VERSION ""

NS_ :

BS_:

BU_: L_3HKBD L_FHPTC L_ATCU L_2HKBD L_PCM L_ATCU_vMON L_EVNT L_HKBD L_RHPTC

BO_ 36 L_ATCU_04: 8 L_ATCU
 SG_ L_ATCU_ArClnIntroEvt : 0|1@1+ (1,0) [0|0] ""  L_HKBD
 SG_ L_ATCU_ArClnSmblClr : 1|4@1+ (1,0) [0|0] ""  L_HKBD
 SG_ L_ATCU_DustLevelDis : 19|3@1+ (1,0) [0|0] ""  L_HKBD
 SG_ L_ATCU_DustBarDisOff : 22|1@1+ (1,0) [0|0] ""  L_HKBD
 SG_ L_ATCU_DustSnrStepDis : 23|6@1+ (1,0) [0|0] ""  L_HKBD
 SG_ L_ATCU_FragStrhDis : 29|2@1+ (1,0) [0|0] ""  L_HKBD,L_PCM
 SG_ L_ATCU_FragKindDis : 31|3@1+ (1,0) [0|0] ""  L_HKBD,L_PCM
 SG_ L_ATCU_Frag1Inform : 34|4@1+ (1,0) [0|0] ""  L_HKBD,L_PCM
 SG_ L_ATCU_Frag2Inform : 38|4@1+ (1,0) [0|0] ""  L_HKBD,L_PCM
 SG_ L_ATCU_Frag1RemainDisp : 42|4@1+ (1,0) [0|0] ""  L_HKBD,L_PCM
 SG_ L_ATCU_Frag2RemainDisp : 46|4@1+ (1,0) [0|0] ""  L_2HKBD,L_HKBD
 SG_ L_ATCU_ArClnSmblTyp : 5|4@1+ (1,0) [0|0] ""  L_HKBD
 SG_ L_ATCU_FrtBlwMaxLvlVaild : 50|4@1+ (1,0) [0|0] ""  L_2HKBD,L_HKBD
 SG_ L_ATCU_OpSta : 54|3@1+ (1,0) [0|0] ""  L_EVNT,L_HKBD
 SG_ L_ATCU_TempDispUnit : 57|2@1+ (1,0) [0|0] ""  L_2HKBD,L_HKBD
 SG_ L_ATCU_DrvAUTOStep : 59|4@1+ (1,0) [0|0] ""  L_HKBD
 SG_ L_ATCU_DiagCodeDis : 9|10@1+ (1,-1) [0|0] ""  L_HKBD

BO_ 784 L_ATCU_MON_35: 8 L_ATCU_vMON
 SG_ MON_StatMngr_AirQuality : 0|64@1+ (1,0) [0|0] ""  L_ATCU

BO_ 37 L_ATCU_05: 8 L_ATCU
 SG_ L_ATCU_RrOpSta : 0|3@1+ (1,0) [0|0] ""  L_2HKBD,L_HKBD
 SG_ L_ATCU_RrDrvTempFDis : 11|8@1+ (1,56) [0|0] "¢µ"  L_2HKBD,L_HKBD
 SG_ L_ATCU_RrDrvModDis : 19|4@1+ (1,0) [0|0] ""  L_2HKBD,L_EVNT,L_HKBD
 SG_ L_ATCU_RrDrvBlwDis : 23|4@1+ (1,0) [0|0] ""  L_2HKBD,L_HKBD
 SG_ L_ATCU_RrDrvAutoDis : 27|2@1+ (1,0) [0|0] ""  L_2HKBD,L_HKBD
 SG_ L_ATCU_RrDrvMultiAutoBlwDis : 29|2@1+ (1,0) [0|0] ""  L_2HKBD,L_HKBD
 SG_ L_ATCU_RrDrvTempCDis : 3|8@1+ (0.5,14) [0|0] "¡É"  L_2HKBD,L_HKBD
 SG_ L_ATCU_RrSyncDis : 31|2@1+ (1,0) [0|0] ""  L_2HKBD,L_HKBD
 SG_ L_ATCU_RrLcdBckLightSta : 33|1@1+ (1,0) [0|0] ""  L_2HKBD,L_HKBD
 SG_ L_ATCU_RrGUIBlankDis : 34|1@1+ (1,0) [0|0] ""  L_2HKBD,L_HKBD
 SG_ L_ATCU_RLStHeatSwHInd : 35|1@1+ (1,0) [0|0] ""  L_2HKBD,L_HKBD
 SG_ L_ATCU_RLStHeatSwMInd : 36|1@1+ (1,0) [0|0] ""  L_2HKBD,L_HKBD
 SG_ L_ATCU_RLStHeatSwLInd : 37|1@1+ (1,0) [0|0] ""  L_2HKBD,L_HKBD
 SG_ L_ATCU_RLStVntSwHInd : 38|1@1+ (1,0) [0|0] ""  L_2HKBD,L_HKBD
 SG_ L_ATCU_RLStVntSwMInd : 39|1@1+ (1,0) [0|0] ""  L_2HKBD,L_HKBD
 SG_ L_ATCU_RLStVntSwLInd : 40|1@1+ (1,0) [0|0] ""  L_2HKBD,L_HKBD
 SG_ L_ATCU_RRStHeatSwHInd : 41|1@1+ (1,0) [0|0] ""  L_2HKBD,L_HKBD
 SG_ L_ATCU_RRStHeatSwMInd : 42|1@1+ (1,0) [0|0] ""  L_2HKBD,L_HKBD
 SG_ L_ATCU_RRStHeatSwLInd : 43|1@1+ (1,0) [0|0] ""  L_2HKBD,L_HKBD
 SG_ L_ATCU_RRStVntSwHInd : 44|1@1+ (1,0) [0|0] ""  L_2HKBD,L_HKBD
 SG_ L_ATCU_RRStVntSwMInd : 45|1@1+ (1,0) [0|0] ""  L_2HKBD,L_HKBD
 SG_ L_ATCU_RRStVntSwLInd : 46|1@1+ (1,0) [0|0] ""  L_2HKBD,L_HKBD
 SG_ L_ATCU_RrMTCOpSta : 47|2@1+ (1,0) [0|0] ""  L_2HKBD,L_HKBD
 SG_ L_ATCU_RrMTCTempLvl : 49|4@1+ (1,0) [0|0] ""  L_2HKBD,L_HKBD
 SG_ L_ATCU_RrPsModDis : 53|4@1+ (1,0) [0|0] ""  L_2HKBD,L_EVNT,L_HKBD
 SG_ L_ATCU_RrLockDis : 57|2@1+ (1,0) [0|0] ""  L_2HKBD,L_HKBD
 SG_ L_ATCU_RrDrvAutoStep : 59|4@1+ (1,0) [0|0] ""  L_2HKBD,L_HKBD

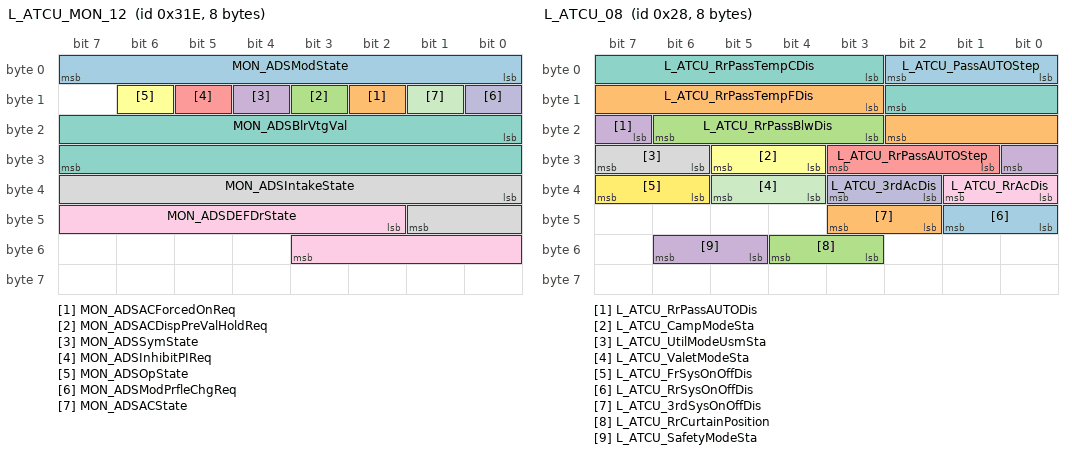
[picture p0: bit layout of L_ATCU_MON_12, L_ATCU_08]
BO_ 798 L_ATCU_MON_12: 8 L_ATCU_vMON
 SG_ MON_ADSModState : 0|8@1+ (1,0) [0|0] ""  L_ATCU
 SG_ MON_ADSACForcedOnReq : 10|1@1+ (1,0) [0|0] ""  L_ATCU
 SG_ MON_ADSACDispPreValHoldReq : 11|1@1+ (1,0) [0|0] ""  L_ATCU
 SG_ MON_ADSSymState : 12|1@1+ (1,0) [0|0] ""  L_ATCU
 SG_ MON_ADSInhibitPIReq : 13|1@1+ (1,0) [0|0] ""  L_ATCU
 SG_ MON_ADSOpState : 14|1@1+ (1,0) [0|0] ""  L_ATCU
 SG_ MON_ADSBlrVtgVal : 16|16@1+ (0.001,0) [0|0] ""  L_ATCU
 SG_ MON_ADSIntakeState : 32|10@1+ (1,0) [0|0] ""  L_ATCU
 SG_ MON_ADSDEFDrState : 42|10@1+ (0.1,0) [0|0] ""  L_ATCU
 SG_ MON_ADSModPrfleChgReq : 8|1@1+ (1,0) [0|0] ""  L_ATCU
 SG_ MON_ADSACState : 9|1@1+ (1,0) [0|0] ""  L_ATCU

BO_ 40 L_ATCU_08: 8 L_ATCU
 SG_ L_ATCU_PassAUTOStep : 0|3@1+ (1,0) [0|0] ""  L_2HKBD,L_HKBD
 SG_ L_ATCU_RrPassTempFDis : 11|8@1+ (1,56) [0|0] "¢µ"  L_2HKBD,L_HKBD
 SG_ L_ATCU_RrPassBlwDis : 19|4@1+ (1,0) [0|0] ""  L_2HKBD,L_HKBD
 SG_ L_ATCU_RrPassAUTODis : 23|2@1+ (1,0) [0|0] ""  L_2HKBD,L_HKBD
 SG_ L_ATCU_RrPassAUTOStep : 25|3@1+ (1,0) [0|0] ""  L_2HKBD,L_HKBD
 SG_ L_ATCU_CampModeSta : 28|2@1+ (1,0) [0|0] ""  L_2HKBD,L_3HKBD,L_EVNT,L_HKBD
 SG_ L_ATCU_RrPassTempCDis : 3|8@1+ (0.5,14) [0|0] "¡É"  L_2HKBD,L_HKBD
 SG_ L_ATCU_UtilModeUsmSta : 30|2@1+ (1,0) [0|0] ""  L_2HKBD,L_3HKBD,L_EVNT,L_HKBD
 SG_ L_ATCU_RrAcDis : 32|2@1+ (1,0) [0|0] ""  L_2HKBD,L_3HKBD,L_HKBD
 SG_ L_ATCU_3rdAcDis : 34|2@1+ (1,0) [0|0] ""  L_2HKBD,L_3HKBD,L_HKBD
 SG_ L_ATCU_ValetModeSta : 36|2@1+ (1,0) [0|0] ""  L_EVNT
 SG_ L_ATCU_FrSysOnOffDis : 38|2@1+ (1,0) [0|0] ""  L_2HKBD,L_3HKBD,L_HKBD
 SG_ L_ATCU_RrSysOnOffDis : 40|2@1+ (1,0) [0|0] ""  L_2HKBD,L_3HKBD,L_HKBD
 SG_ L_ATCU_3rdSysOnOffDis : 42|2@1+ (1,0) [0|0] ""  L_2HKBD,L_3HKBD,L_HKBD
 SG_ L_ATCU_RrCurtainPosition : 51|2@1+ (1,0) [0|0] ""  L_2HKBD,L_3HKBD
 SG_ L_ATCU_SafetyModeSta : 53|2@1+ (1,0) [0|0] ""  L_2HKBD,L_3HKBD,L_EVNT,L_HKBD

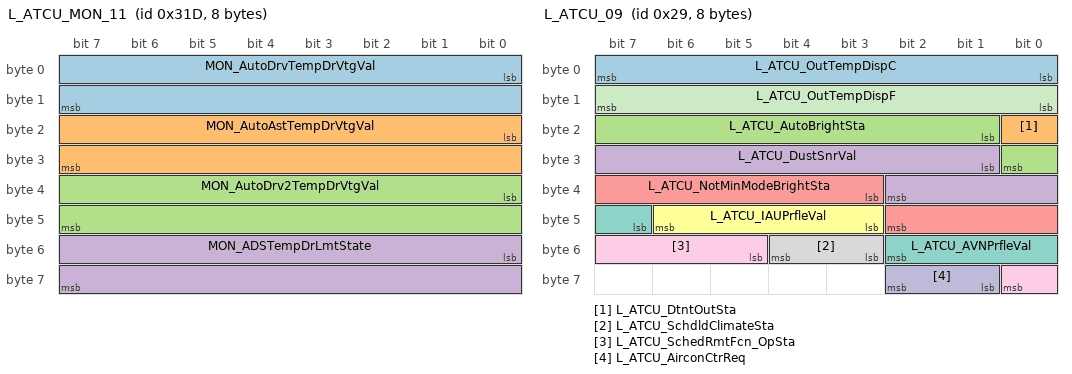
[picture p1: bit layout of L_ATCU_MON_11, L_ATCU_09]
BO_ 797 L_ATCU_MON_11: 8 L_ATCU_vMON
 SG_ MON_AutoDrvTempDrVtgVal : 0|16@1+ (0.001,0) [0|0] ""  L_ATCU
 SG_ MON_AutoAstTempDrVtgVal : 16|16@1+ (0.001,0) [0|0] ""  L_ATCU
 SG_ MON_AutoDrv2TempDrVtgVal : 32|16@1+ (0.001,0) [0|0] ""  L_ATCU
 SG_ MON_ADSTempDrLmtState : 48|16@1+ (0.001,0) [0|0] ""  L_ATCU

BO_ 41 L_ATCU_09: 8 L_ATCU
 SG_ L_ATCU_OutTempDispC : 0|8@1+ (0.5,-41) [0|0] "¡É"  L_FHPTC,L_HKBD,L_RHPTC
 SG_ L_ATCU_DtntOutSta : 16|1@1+ (1,0) [0|0] ""  L_2HKBD,L_EVNT,L_HKBD
 SG_ L_ATCU_AutoBrightSta : 17|8@1+ (1,0) [0|0] ""  L_2HKBD,L_EVNT,L_HKBD
 SG_ L_ATCU_DustSnrVal : 25|10@1+ (1,0) [0|0] "um/m3"  L_HKBD
 SG_ L_ATCU_NotMinModeBrightSta : 35|8@1+ (1,0) [0|0] ""  L_2HKBD,L_3HKBD,L_EVNT,L_HKBD
 SG_ L_ATCU_IAUPrfleVal : 43|4@1+ (1,0) [0|0] ""  L_EVNT
 SG_ L_ATCU_AVNPrfleVal : 47|4@1+ (1,0) [0|0] ""  L_EVNT
 SG_ L_ATCU_SchdldClimateSta : 51|2@1+ (1,0) [0|0] ""  L_EVNT
 SG_ L_ATCU_SchedRmtFcn_OpSta : 53|4@1+ (1,0) [0|15] ""  L_2HKBD,L_3HKBD,L_EVNT,L_HKBD
 SG_ L_ATCU_AirconCtrReq : 57|2@1+ (1,0) [0|0] ""  L_2HKBD,L_3HKBD,L_EVNT,L_HKBD
 SG_ L_ATCU_OutTempDispF : 8|8@1+ (1,-42) [0|0] "¢µ"  L_FHPTC,L_HKBD,L_RHPTC

BO_ 795 L_ATCU_MON_46: 8 L_ATCU_vMON
 SG_ MON_StatMngr_2ndFuelEfficiency : 0|64@1+ (1,0) [0|0] ""  L_ATCU

BO_ 794 L_ATCU_MON_45: 8 L_ATCU_vMON
 SG_ MON_StatMngr_2ndETC : 0|64@1+ (1,0) [0|0] ""  L_ATCU

BO_ 793 L_ATCU_MON_44: 8 L_ATCU_vMON
 SG_ MON_StatMngr_2ndAirQuality : 0|64@1+ (1,0) [0|0] ""  L_ATCU

BO_ 792 L_ATCU_MON_43: 8 L_ATCU_vMON
 SG_ MON_StatMngr_2ndConvenience : 0|64@1+ (1,0) [0|0] ""  L_ATCU

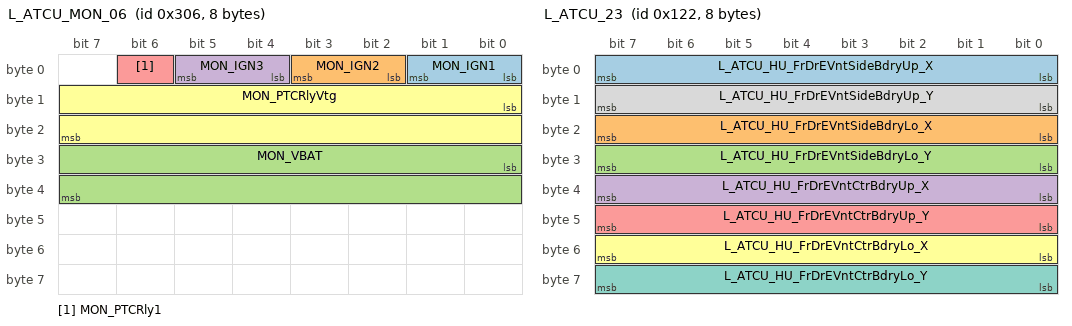
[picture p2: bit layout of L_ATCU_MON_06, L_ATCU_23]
BO_ 774 L_ATCU_MON_06: 8 L_ATCU_vMON
 SG_ MON_IGN1 : 0|2@1+ (1,0) [0|3] ""  L_ATCU
 SG_ MON_IGN2 : 2|2@1+ (1,0) [0|3] ""  L_ATCU
 SG_ MON_VBAT : 24|16@1+ (0.001,0) [0|0] ""  L_ATCU
 SG_ MON_IGN3 : 4|2@1+ (1,0) [0|3] ""  L_ATCU
 SG_ MON_PTCRly1 : 6|1@1+ (1,0) [0|1] ""  L_ATCU
 SG_ MON_PTCRlyVtg : 8|16@1+ (0.001,0) [0|5] "V"  L_ATCU

BO_ 775 L_ATCU_MON_07: 8 L_ATCU_vMON
 SG_ MON_RgnOpt : 0|4@1+ (1,0) [0|15] ""  L_ATCU
 SG_ MON_DrvOnlyOpt : 10|1@1+ (1,0) [0|1] ""  L_ATCU
 SG_ MON_ADSOpt : 11|1@1+ (1,0) [0|1] ""  L_ATCU
 SG_ MON_AfterBlowOpt : 12|1@1+ (1,0) [0|1] ""  L_ATCU
 SG_ MON_SchdldVentOpt : 13|1@1+ (1,0) [0|1] ""  L_ATCU
 SG_ MON_FineDustOpt : 14|1@1+ (1,0) [0|1] ""  L_ATCU
 SG_ MON_FrontSyncCtrlTypOpt : 15|1@1+ (1,0) [0|1] ""  L_ATCU
 SG_ MON_CompOpt : 16|3@1+ (1,0) [0|7] ""  L_ATCU
 SG_ MON_WheelDrivePosOpt : 19|2@1+ (1,0) [0|3] ""  L_ATCU
 SG_ MON_NetworkTypOpt : 21|3@1+ (1,0) [0|7] ""  L_ATCU
 SG_ MON_AutoSwTyp : 24|1@1+ (1,0) [0|1] ""  L_ATCU
 SG_ MON_ModSwTypOpt : 25|2@1+ (1,0) [0|3] ""  L_ATCU
 SG_ MON_IntakeSwTypOpt : 27|1@1+ (1,0) [0|1] ""  L_ATCU
 SG_ MON_OffSwTypOpt : 28|2@1+ (1,0) [0|3] ""  L_ATCU
 SG_ MON_TempSwKnobOpt : 30|1@1+ (1,0) [0|1] ""  L_ATCU
 SG_ MON_BlrSwKnobOpt : 31|1@1+ (1,0) [0|1] ""  L_ATCU
 SG_ MON_BATCoolingTypOpt : 32|2@1+ (1,0) [0|3] ""  L_ATCU
 SG_ MON_PTCStepOpt : 34|1@1+ (1,0) [0|1] ""  L_ATCU
 SG_ MON_PTCTypOpt : 35|2@1+ (1,0) [0|3] ""  L_ATCU
 SG_ MON_ThermostatOpt : 37|1@1+ (1,0) [0|1] ""  L_ATCU
 SG_ MON_SmartVentOpt : 38|1@1+ (1,0) [0|1] ""  L_ATCU
 SG_ MON_ROATypOpt : 39|1@1+ (1,0) [0|1] ""  L_ATCU
 SG_ MON_VehTypOpt : 4|3@1+ (1,0) [0|7] ""  L_ATCU
 SG_ MON_VRLedOpt : 40|1@1+ (1,0) [0|1] ""  L_ATCU
 SG_ MON_FrontAutoStepOpt : 41|2@1+ (1,0) [0|3] ""  L_ATCU
 SG_ MON_2ndAutoStepOpt : 43|2@1+ (1,0) [0|3] ""  L_ATCU
 SG_ MON_2ndAutoSwTyp : 45|1@1+ (1,0) [0|1] ""  L_ATCU
 SG_ MON_2ndOffSwTypOpt : 46|2@1+ (1,0) [0|3] ""  L_ATCU
 SG_ MON_2ndModSwTypOpt : 48|2@1+ (1,0) [0|3] ""  L_ATCU
 SG_ MON_2ndAutoBtnOpt : 50|2@1+ (1,0) [0|3] ""  L_ATCU
 SG_ MON_2ndBlrBtnOpt : 52|2@1+ (1,0) [0|3] ""  L_ATCU
 SG_ MON_2ndModBtnOpt : 54|2@1+ (1,0) [0|3] ""  L_ATCU
 SG_ MON_2ndTmpBtnOpt : 56|2@1+ (1,0) [0|3] ""  L_ATCU
 SG_ MON_2ndTempSwKnobOpt : 58|1@1+ (1,0) [0|1] ""  L_ATCU
 SG_ MON_DrvHndSideOpt : 7|1@1+ (1,0) [0|1] ""  L_ATCU
 SG_ MON_DisplayOpt : 8|2@1+ (1,0) [0|3] ""  L_ATCU

BO_ 290 L_ATCU_23: 8 L_ATCU
 SG_ L_ATCU_HU_FrDrEVntSideBdryUp_X : 0|8@1+ (10,0) [0|0] ""  L_EVNT
 SG_ L_ATCU_HU_FrDrEVntSideBdryLo_X : 16|8@1+ (10,0) [0|0] ""  L_EVNT
 SG_ L_ATCU_HU_FrDrEVntSideBdryLo_Y : 24|8@1+ (10,0) [0|0] ""  L_EVNT
 SG_ L_ATCU_HU_FrDrEVntCtrBdryUp_X : 32|8@1+ (10,0) [0|0] ""  L_EVNT
 SG_ L_ATCU_HU_FrDrEVntCtrBdryUp_Y : 40|8@1+ (10,0) [0|0] ""  L_EVNT
 SG_ L_ATCU_HU_FrDrEVntCtrBdryLo_X : 48|8@1+ (10,0) [0|0] ""  L_EVNT
 SG_ L_ATCU_HU_FrDrEVntCtrBdryLo_Y : 56|8@1+ (10,0) [0|0] ""  L_EVNT
 SG_ L_ATCU_HU_FrDrEVntSideBdryUp_Y : 8|8@1+ (10,0) [0|0] ""  L_EVNT

BO_ 49 L_ATCU_11: 8 L_ATCU
 SG_ L_ATCU_ResetPreWrngForOthers : 0|2@1+ (1,0) [0|0] ""  L_2HKBD,L_3HKBD,L_EVNT,L_HKBD,L_PCM
 SG_ L_ATCU_ResetReqForOthers : 2|2@1+ (1,0) [0|0] ""  L_2HKBD,L_3HKBD,L_EVNT,L_HKBD,L_PCM

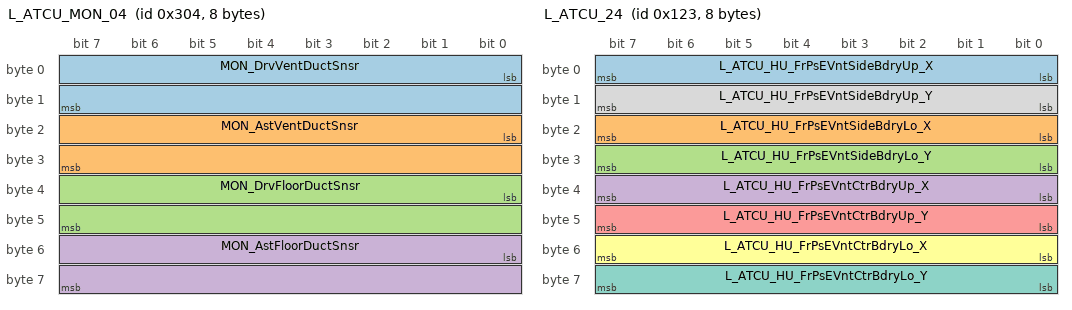
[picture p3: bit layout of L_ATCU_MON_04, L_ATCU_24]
BO_ 772 L_ATCU_MON_04: 8 L_ATCU_vMON
 SG_ MON_DrvVentDuctSnsr : 0|16@1+ (0.1,-40) [-40|120] "¡É"  L_ATCU
 SG_ MON_AstVentDuctSnsr : 16|16@1+ (0.1,-40) [-40|120] "¡É"  L_ATCU
 SG_ MON_DrvFloorDuctSnsr : 32|16@1+ (0.1,-40) [-40|120] "¡É"  L_ATCU
 SG_ MON_AstFloorDuctSnsr : 48|16@1+ (0.1,-40) [-40|120] "¡É"  L_ATCU

BO_ 291 L_ATCU_24: 8 L_ATCU
 SG_ L_ATCU_HU_FrPsEVntSideBdryUp_X : 0|8@1+ (10,0) [0|0] ""  L_EVNT
 SG_ L_ATCU_HU_FrPsEVntSideBdryLo_X : 16|8@1+ (10,0) [0|0] ""  L_EVNT
 SG_ L_ATCU_HU_FrPsEVntSideBdryLo_Y : 24|8@1+ (10,0) [0|0] ""  L_EVNT
 SG_ L_ATCU_HU_FrPsEVntCtrBdryUp_X : 32|8@1+ (10,0) [0|0] ""  L_EVNT
 SG_ L_ATCU_HU_FrPsEVntCtrBdryUp_Y : 40|8@1+ (10,0) [0|0] ""  L_EVNT
 SG_ L_ATCU_HU_FrPsEVntCtrBdryLo_X : 48|8@1+ (10,0) [0|0] ""  L_EVNT
 SG_ L_ATCU_HU_FrPsEVntCtrBdryLo_Y : 56|8@1+ (10,0) [0|0] ""  L_EVNT
 SG_ L_ATCU_HU_FrPsEVntSideBdryUp_Y : 8|8@1+ (10,0) [0|0] ""  L_EVNT

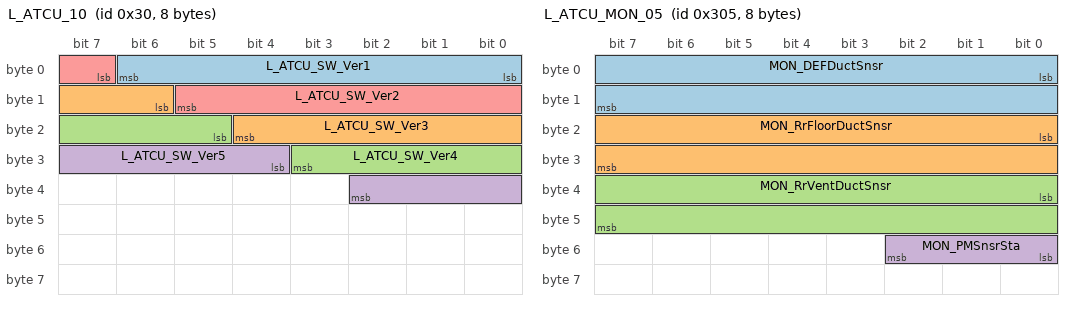
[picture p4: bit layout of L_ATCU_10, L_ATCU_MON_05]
BO_ 48 L_ATCU_10: 8 L_ATCU
 SG_ L_ATCU_SW_Ver1 : 0|7@1+ (1,0) [0|0] ""  L_HKBD
 SG_ L_ATCU_SW_Ver3 : 14|7@1+ (1,0) [0|0] ""  L_HKBD
 SG_ L_ATCU_SW_Ver4 : 21|7@1+ (1,0) [0|0] ""  L_HKBD
 SG_ L_ATCU_SW_Ver5 : 28|7@1+ (1,0) [0|0] ""  L_HKBD
 SG_ L_ATCU_SW_Ver2 : 7|7@1+ (1,0) [0|0] ""  L_HKBD

BO_ 773 L_ATCU_MON_05: 8 L_ATCU_vMON
 SG_ MON_DEFDuctSnsr : 0|16@1+ (0.1,-40) [-40|120] "¡É"  L_ATCU
 SG_ MON_RrFloorDuctSnsr : 16|16@1+ (0.1,-40) [-40|120] "¡É"  L_ATCU
 SG_ MON_RrVentDuctSnsr : 32|16@1+ (0.1,-40) [-40|120] "¡É"  L_ATCU
 SG_ MON_PMSnsrSta : 48|3@1+ (1,0) [0|0] ""  L_ATCU

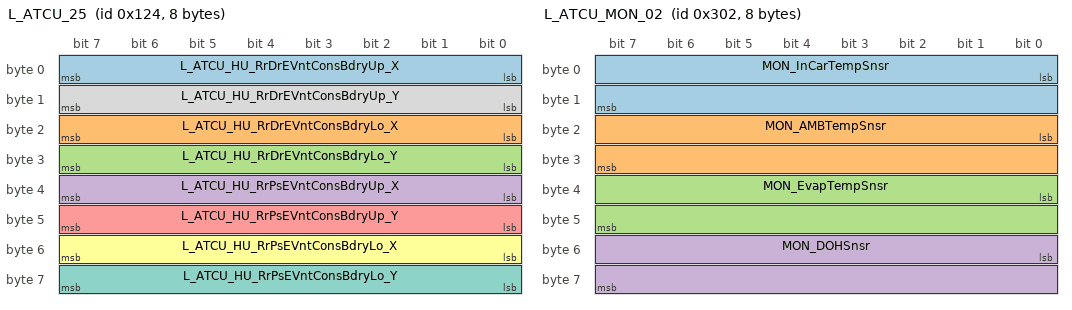
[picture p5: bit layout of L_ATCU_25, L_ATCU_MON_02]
BO_ 292 L_ATCU_25: 8 L_ATCU
 SG_ L_ATCU_HU_RrDrEVntConsBdryUp_X : 0|8@1+ (10,0) [0|0] ""  L_EVNT
 SG_ L_ATCU_HU_RrDrEVntConsBdryLo_X : 16|8@1+ (10,0) [0|0] ""  L_EVNT
 SG_ L_ATCU_HU_RrDrEVntConsBdryLo_Y : 24|8@1+ (10,0) [0|0] ""  L_EVNT
 SG_ L_ATCU_HU_RrPsEVntConsBdryUp_X : 32|8@1+ (10,0) [0|0] ""  L_EVNT
 SG_ L_ATCU_HU_RrPsEVntConsBdryUp_Y : 40|8@1+ (10,0) [0|0] ""  L_EVNT
 SG_ L_ATCU_HU_RrPsEVntConsBdryLo_X : 48|8@1+ (10,0) [0|0] ""  L_EVNT
 SG_ L_ATCU_HU_RrPsEVntConsBdryLo_Y : 56|8@1+ (10,0) [0|0] ""  L_EVNT
 SG_ L_ATCU_HU_RrDrEVntConsBdryUp_Y : 8|8@1+ (10,0) [0|0] ""  L_EVNT

BO_ 770 L_ATCU_MON_02: 8 L_ATCU_vMON
 SG_ MON_InCarTempSnsr : 0|16@1+ (0.1,-40) [-40|60] "¡É"  L_ATCU
 SG_ MON_AMBTempSnsr : 16|16@1+ (0.1,-40) [-40|60] "¡É"  L_ATCU
 SG_ MON_EvapTempSnsr : 32|16@1+ (0.1,-20) [-20|40] "¡É"  L_ATCU
 SG_ MON_DOHSnsr : 48|16@1+ (1,0) [0|100] "%"  L_ATCU

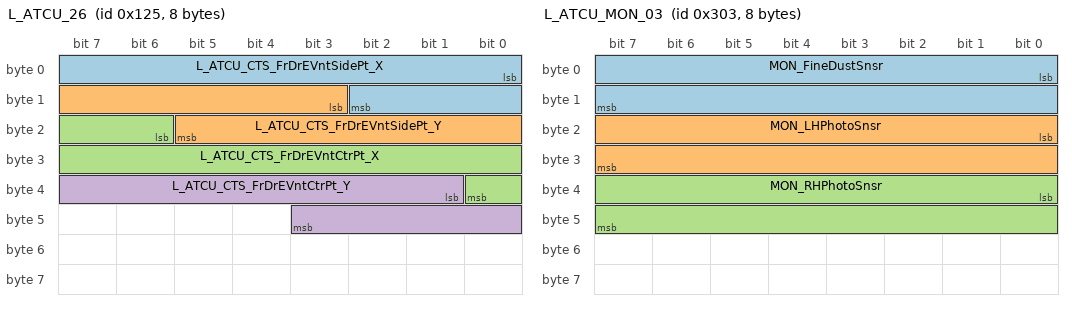
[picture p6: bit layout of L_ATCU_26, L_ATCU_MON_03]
BO_ 293 L_ATCU_26: 8 L_ATCU
 SG_ L_ATCU_CTS_FrDrEVntSidePt_X : 0|11@1+ (1,0) [0|0] ""  L_EVNT
 SG_ L_ATCU_CTS_FrDrEVntSidePt_Y : 11|11@1+ (1,0) [0|0] ""  L_EVNT
 SG_ L_ATCU_CTS_FrDrEVntCtrPt_X : 22|11@1+ (1,0) [0|0] ""  L_EVNT
 SG_ L_ATCU_CTS_FrDrEVntCtrPt_Y : 33|11@1+ (1,0) [0|0] ""  L_EVNT

BO_ 771 L_ATCU_MON_03: 8 L_ATCU_vMON
 SG_ MON_FineDustSnsr : 0|16@1+ (1,0) [0|255] ""  L_ATCU
 SG_ MON_LHPhotoSnsr : 16|16@1+ (0.001,0) [0|5] "V"  L_ATCU
 SG_ MON_RHPhotoSnsr : 32|16@1+ (0.001,0) [0|5] "V"  L_ATCU

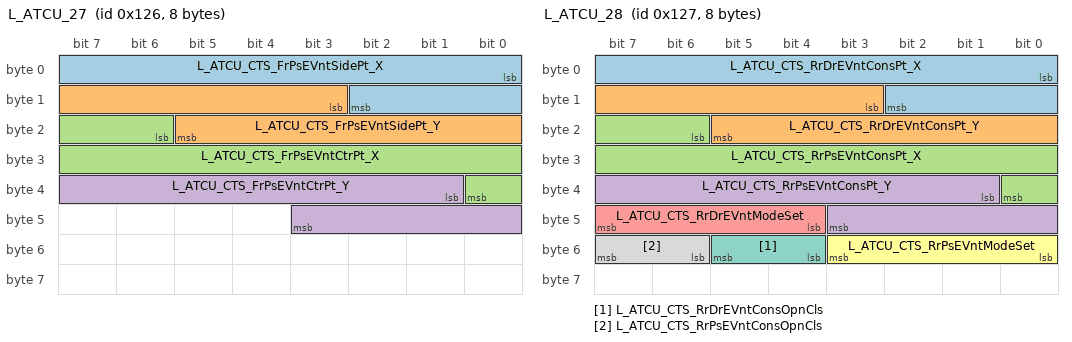
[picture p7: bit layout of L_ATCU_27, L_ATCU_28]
BO_ 294 L_ATCU_27: 8 L_ATCU
 SG_ L_ATCU_CTS_FrPsEVntSidePt_X : 0|11@1+ (1,0) [0|0] ""  L_EVNT
 SG_ L_ATCU_CTS_FrPsEVntSidePt_Y : 11|11@1+ (1,0) [0|0] ""  L_EVNT
 SG_ L_ATCU_CTS_FrPsEVntCtrPt_X : 22|11@1+ (1,0) [0|0] ""  L_EVNT
 SG_ L_ATCU_CTS_FrPsEVntCtrPt_Y : 33|11@1+ (1,0) [0|0] ""  L_EVNT

BO_ 295 L_ATCU_28: 8 L_ATCU
 SG_ L_ATCU_CTS_RrDrEVntConsPt_X : 0|11@1+ (1,0) [0|0] ""  L_EVNT
 SG_ L_ATCU_CTS_RrDrEVntConsPt_Y : 11|11@1+ (1,0) [0|0] ""  L_EVNT
 SG_ L_ATCU_CTS_RrPsEVntConsPt_X : 22|11@1+ (1,0) [0|0] ""  L_EVNT
 SG_ L_ATCU_CTS_RrPsEVntConsPt_Y : 33|11@1+ (1,0) [0|0] ""  L_EVNT
 SG_ L_ATCU_CTS_RrDrEVntModeSet : 44|4@1+ (1,0) [0|0] ""  L_EVNT
 SG_ L_ATCU_CTS_RrPsEVntModeSet : 48|4@1+ (1,0) [0|0] ""  L_EVNT
 SG_ L_ATCU_CTS_RrDrEVntConsOpnCls : 52|2@1+ (1,0) [0|0] ""  L_EVNT
 SG_ L_ATCU_CTS_RrPsEVntConsOpnCls : 54|2@1+ (1,0) [0|0] ""  L_EVNT

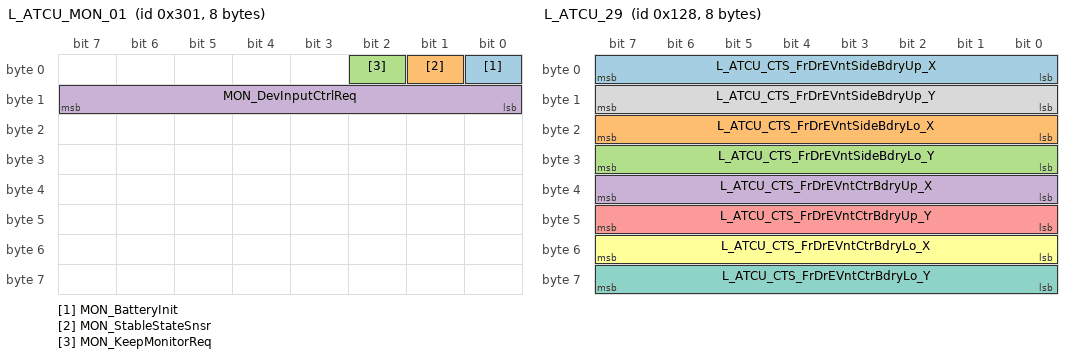
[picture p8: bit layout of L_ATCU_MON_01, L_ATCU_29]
BO_ 769 L_ATCU_MON_01: 8 L_ATCU_vMON
 SG_ MON_BatteryInit : 0|1@1+ (1,0) [0|1] ""  L_ATCU
 SG_ MON_StableStateSnsr : 1|1@1+ (1,0) [0|1] ""  L_ATCU
 SG_ MON_KeepMonitorReq : 2|1@1+ (1,0) [0|1] ""  L_ATCU
 SG_ MON_DevInputCtrlReq : 8|8@1+ (1,0) [0|0] ""  L_ATCU

BO_ 782 L_ATCU_MON_33: 8 L_ATCU_vMON
 SG_ MON_StatMngr_Mngr : 0|64@1+ (1,0) [0|0] ""  L_ATCU

BO_ 296 L_ATCU_29: 8 L_ATCU
 SG_ L_ATCU_CTS_FrDrEVntSideBdryUp_X : 0|8@1+ (10,0) [0|0] ""  L_EVNT
 SG_ L_ATCU_CTS_FrDrEVntSideBdryLo_X : 16|8@1+ (10,0) [0|0] ""  L_EVNT
 SG_ L_ATCU_CTS_FrDrEVntSideBdryLo_Y : 24|8@1+ (10,0) [0|0] ""  L_EVNT
 SG_ L_ATCU_CTS_FrDrEVntCtrBdryUp_X : 32|8@1+ (10,0) [0|0] ""  L_EVNT
 SG_ L_ATCU_CTS_FrDrEVntCtrBdryUp_Y : 40|8@1+ (10,0) [0|0] ""  L_EVNT
 SG_ L_ATCU_CTS_FrDrEVntCtrBdryLo_X : 48|8@1+ (10,0) [0|0] ""  L_EVNT
 SG_ L_ATCU_CTS_FrDrEVntCtrBdryLo_Y : 56|8@1+ (10,0) [0|0] ""  L_EVNT
 SG_ L_ATCU_CTS_FrDrEVntSideBdryUp_Y : 8|8@1+ (10,0) [0|0] ""  L_EVNT

BO_ 783 L_ATCU_MON_34: 8 L_ATCU_vMON
 SG_ MON_StatMngr_Convenience : 0|64@1+ (1,0) [0|0] ""  L_ATCU

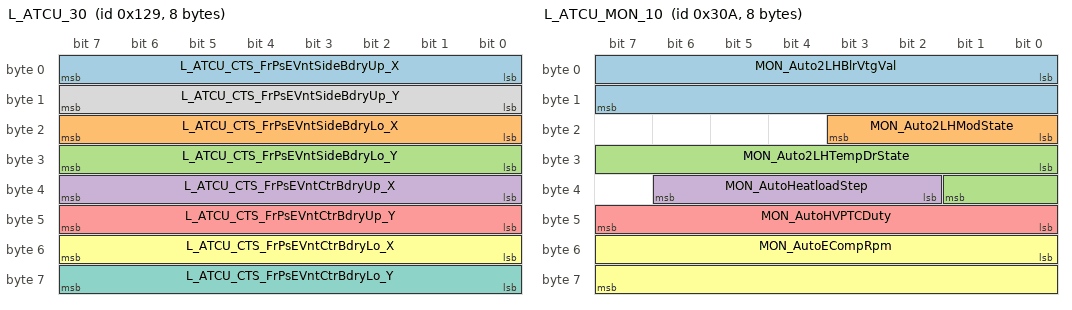
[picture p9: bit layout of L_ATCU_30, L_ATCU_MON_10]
BO_ 297 L_ATCU_30: 8 L_ATCU
 SG_ L_ATCU_CTS_FrPsEVntSideBdryUp_X : 0|8@1+ (10,0) [0|0] ""  L_EVNT
 SG_ L_ATCU_CTS_FrPsEVntSideBdryLo_X : 16|8@1+ (10,0) [0|0] ""  L_EVNT
 SG_ L_ATCU_CTS_FrPsEVntSideBdryLo_Y : 24|8@1+ (10,0) [0|0] ""  L_EVNT
 SG_ L_ATCU_CTS_FrPsEVntCtrBdryUp_X : 32|8@1+ (10,0) [0|0] ""  L_EVNT
 SG_ L_ATCU_CTS_FrPsEVntCtrBdryUp_Y : 40|8@1+ (10,0) [0|0] ""  L_EVNT
 SG_ L_ATCU_CTS_FrPsEVntCtrBdryLo_X : 48|8@1+ (10,0) [0|0] ""  L_EVNT
 SG_ L_ATCU_CTS_FrPsEVntCtrBdryLo_Y : 56|8@1+ (10,0) [0|0] ""  L_EVNT
 SG_ L_ATCU_CTS_FrPsEVntSideBdryUp_Y : 8|8@1+ (10,0) [0|0] ""  L_EVNT

BO_ 780 L_ATCU_MON_31: 8 L_ATCU_vMON
 SG_ MON_StatMngr_Temp : 0|64@1+ (1,0) [0|0] ""  L_ATCU

BO_ 781 L_ATCU_MON_32: 8 L_ATCU_vMON
 SG_ MON_StatMngr_SafetynCool : 0|64@1+ (1,0) [0|0] ""  L_ATCU

BO_ 778 L_ATCU_MON_10: 8 L_ATCU_vMON
 SG_ MON_Auto2LHBlrVtgVal : 0|16@1+ (1,0) [0|65535] ""  L_ATCU
 SG_ MON_Auto2LHModState : 16|4@1+ (1,0) [0|15] ""  L_ATCU
 SG_ MON_Auto2LHTempDrState : 24|10@1+ (1,0) [0|1023] ""  L_ATCU
 SG_ MON_AutoHeatloadStep : 34|5@1+ (1,0) [0|31] ""  L_ATCU
 SG_ MON_AutoHVPTCDuty : 40|8@1+ (1,0) [0|255] "%"  L_ATCU
 SG_ MON_AutoECompRpm : 48|16@1+ (1,0) [0|65535] ""  L_ATCU

BO_ 779 L_ATCU_MON_30: 8 L_ATCU_vMON
 SG_ MON_StatMngr_Humid : 0|64@1+ (1,0) [0|0] ""  L_ATCU

CM_ BO_ 36 "[PE] Periodic and On Event";
CM_ SG_ 36 L_ATCU_ArClnIntroEvt "ATCU_AirCleaningIntroEvent";
CM_ SG_ 36 L_ATCU_ArClnSmblClr "ATCU_AirCleaningSymbolColor";
CM_ SG_ 36 L_ATCU_DustLevelDis "ATCU_DustLevelDisplay";
CM_ SG_ 36 L_ATCU_DustBarDisOff "ATCU_DustBarDisplayOff";
CM_ SG_ 36 L_ATCU_DustSnrStepDis "ATCU_DustSensorStepDisplay";
CM_ SG_ 36 L_ATCU_FragStrhDis "ATCU_FragStrengthDisplay";
CM_ SG_ 36 L_ATCU_FragKindDis "ATCU_FragKindDisplay";
CM_ SG_ 36 L_ATCU_Frag1Inform "ATCU_Frag1Information";
CM_ SG_ 36 L_ATCU_Frag2Inform "ATCU_Frag2Information";
CM_ SG_ 36 L_ATCU_Frag1RemainDisp "ATCU_Frag1RemainDisplay";
CM_ SG_ 36 L_ATCU_Frag2RemainDisp "ATCU_Frag2RemainDisplay";
CM_ SG_ 36 L_ATCU_ArClnSmblTyp "ATCU_AircCleaningSymbolType";
CM_ SG_ 36 L_ATCU_FrtBlwMaxLvlVaild "ATCU_FrontBlowerMaxLevelVaild";
CM_ SG_ 36 L_ATCU_OpSta "ATCU_OperationStatus";
CM_ SG_ 36 L_ATCU_TempDispUnit "ATCU_TemperatureDisplayUnit";
CM_ SG_ 36 L_ATCU_DrvAUTOStep "ATCU_DriverAutoStep";
CM_ SG_ 36 L_ATCU_DiagCodeDis "ATCU_DiagCodeDisplay";
CM_ BO_ 37 "[PE] Periodic and On Event";
CM_ SG_ 37 L_ATCU_RrOpSta "ATCU_RearOperationStatus";
CM_ SG_ 37 L_ATCU_RrDrvTempFDis "ATCU_RearDriverTemperature¢µDisplay";
CM_ SG_ 37 L_ATCU_RrDrvModDis "ATCU_RearDriverModeDisplay";
CM_ SG_ 37 L_ATCU_RrDrvBlwDis "ATCU_RearDriverBlowerDisplay";
CM_ SG_ 37 L_ATCU_RrDrvAutoDis "ATCU_RearDriverAutoDisplay";
CM_ SG_ 37 L_ATCU_RrDrvMultiAutoBlwDis "ATCU_RearDriverMultiAutoBlowerDisplay";
CM_ SG_ 37 L_ATCU_RrDrvTempCDis "ATCU_RearDriverTemperature¡ÉDisplay";
CM_ SG_ 37 L_ATCU_RrSyncDis "ATCU_RearSyncDisplay";
CM_ SG_ 37 L_ATCU_RrLcdBckLightSta "ATCU_RearLCDBackLightStatus";
CM_ SG_ 37 L_ATCU_RrGUIBlankDis "ATCU_RearGUIBlankDisplay";
CM_ SG_ 37 L_ATCU_RLStHeatSwHInd "ATCU_RearLeftSeatHeatSwitchHighIndicator";
CM_ SG_ 37 L_ATCU_RLStHeatSwMInd "ATCU_RearLeftSeatHeatSwitchMiddleIndicator";
CM_ SG_ 37 L_ATCU_RLStHeatSwLInd "ATCU_RearLeftSeatHeatSwitchLowIndicator";
CM_ SG_ 37 L_ATCU_RLStVntSwHInd "ATCU_RearLeftSeatVentilationSwitchHighIndicator";
CM_ SG_ 37 L_ATCU_RLStVntSwMInd "ATCU_RearLeftSeatVentilationSwitchMiddleIndicator";
CM_ SG_ 37 L_ATCU_RLStVntSwLInd "ATCU_RearLeftSeatVentilationSwitchLowIndicator";
CM_ SG_ 37 L_ATCU_RRStHeatSwHInd "ATCU_RearRightSeatHeatSwitchHighIndicator";
CM_ SG_ 37 L_ATCU_RRStHeatSwMInd "ATCU_RearRightSeatHeatSwitchMiddleIndicator";
CM_ SG_ 37 L_ATCU_RRStHeatSwLInd "ATCU_RearRightSeatHeatSwitchLowIndicator";
CM_ SG_ 37 L_ATCU_RRStVntSwHInd "ATCU_RearRightSeatVentilationSwitchHighIndicator";
CM_ SG_ 37 L_ATCU_RRStVntSwMInd "ATCU_RearRightSeatVentilationSwitchMiddleIndicator";
CM_ SG_ 37 L_ATCU_RRStVntSwLInd "ATCU_RearRightSeatVentilationSwitchLowIndicator";
CM_ SG_ 37 L_ATCU_RrMTCOpSta "ATCU_RearMTCOperationStatus";
CM_ SG_ 37 L_ATCU_RrMTCTempLvl "ATCU_RearMTCTempLevel";
CM_ SG_ 37 L_ATCU_RrPsModDis "ATCU_RearPassengerModeDisplay";
CM_ SG_ 37 L_ATCU_RrLockDis "ATCU_RearLockDisplay";
CM_ SG_ 37 L_ATCU_RrDrvAutoStep "ATCU_RearDriverAutoStep";
CM_ BO_ 40 "[PE] Periodic and On Event";
CM_ SG_ 40 L_ATCU_PassAUTOStep "ATCU_PassAUTOStep";
CM_ SG_ 40 L_ATCU_RrPassTempFDis "ATCU_RrPassTempFDisplay";
CM_ SG_ 40 L_ATCU_RrPassBlwDis "ATCU_RrPassBlwDis";
CM_ SG_ 40 L_ATCU_RrPassAUTODis "ATCU_RrPassAUTODis";
CM_ SG_ 40 L_ATCU_RrPassAUTOStep "ATCU_RrPassAUTOStep";
CM_ SG_ 40 L_ATCU_CampModeSta "ATCU_CampModeStatus";
CM_ SG_ 40 L_ATCU_RrPassTempCDis "ATCU_RrPassTempCDisplay";
CM_ SG_ 40 L_ATCU_UtilModeUsmSta "ATCU_UtilityModeUSMStatus";
CM_ SG_ 40 L_ATCU_RrAcDis "ATCU_RrAcDisplay";
CM_ SG_ 40 L_ATCU_3rdAcDis "L_ATCU_3rdAcDisplay";
CM_ SG_ 40 L_ATCU_ValetModeSta "L_ATCU_ValetModeSta";
CM_ SG_ 40 L_ATCU_FrSysOnOffDis "DATC_FrontSystemOnOffDisplay";
CM_ SG_ 40 L_ATCU_RrSysOnOffDis "DATC_RearSystemOnOffDisplay";
CM_ SG_ 40 L_ATCU_3rdSysOnOffDis "DATC_3rdSystemOnOffDisplay";
CM_ SG_ 40 L_ATCU_RrCurtainPosition "Rear Curtain Position Information. This signal is valid when rear curtain is wire type.";
CM_ SG_ 40 L_ATCU_SafetyModeSta "L_ATCU_SafetyModeSta";
CM_ BO_ 41 "[P] Periodic";
CM_ SG_ 41 L_ATCU_OutTempDispC "ATCU_OutTemperatureDisplay(¡É)";
CM_ SG_ 41 L_ATCU_DtntOutSta "ATCU_DetentOutStatus";
CM_ SG_ 41 L_ATCU_AutoBrightSta "ATCU_AutoBrightStatus";
CM_ SG_ 41 L_ATCU_DustSnrVal "ATCU_DustSensorValue";
CM_ SG_ 41 L_ATCU_NotMinModeBrightSta "ATCU_NotMinimumModeBrightStatus";
CM_ SG_ 41 L_ATCU_IAUPrfleVal "L_ATCU_IAUProfileValue";
CM_ SG_ 41 L_ATCU_AVNPrfleVal "L_ATCU_AVNProfileValue";
CM_ SG_ 41 L_ATCU_SchdldClimateSta "Operation of the air conditioning system, controlled by the remote control instructions according to the Power status and VCU(HCU, CCU, etc.), NOT ROUTING.";
CM_ SG_ 41 L_ATCU_SchedRmtFcn_OpSta "L_ATCU_ScheduledRemoteFunction_OperatingStatus";
CM_ SG_ 41 L_ATCU_AirconCtrReq "L_ATCU_AirconControlRequest";
CM_ SG_ 41 L_ATCU_OutTempDispF "ATCU_OutTemperatureDisplay(¢µ)";
CM_ BO_ 48 "[PE] Periodic and On Event";
CM_ SG_ 48 L_ATCU_SW_Ver1 "ATCU_SoftWare_Version1";
CM_ SG_ 48 L_ATCU_SW_Ver3 "ATCU_SoftWare_Version3";
CM_ SG_ 48 L_ATCU_SW_Ver4 "ATCU_SoftWare_Version4";
CM_ SG_ 48 L_ATCU_SW_Ver5 "ATCU_SoftWare_Version5";
CM_ SG_ 48 L_ATCU_SW_Ver2 "ATCU_SoftWare_Version2";
CM_ BO_ 49 "[PE] Periodic and On Event";
CM_ SG_ 49 L_ATCU_ResetPreWrngForOthers "This is a PDC routing signal for reset preparing sideeffect of reset";
CM_ SG_ 49 L_ATCU_ResetReqForOthers "This is a PDC routing signal for SW reset except for Gateway";
CM_ BO_ 290 "[P] Periodic";
CM_ SG_ 290 L_ATCU_HU_FrDrEVntSideBdryUp_X "Front Driver Electric Vent Side Boundary Upper X Point";
CM_ SG_ 290 L_ATCU_HU_FrDrEVntSideBdryLo_X "Front Driver Electric Vent Side Boundary Lower X Point";
CM_ SG_ 290 L_ATCU_HU_FrDrEVntSideBdryLo_Y "Front Driver Electric Vent Side Boundary Lower Y Point";
CM_ SG_ 290 L_ATCU_HU_FrDrEVntCtrBdryUp_X "Front Driver Electric Vent Center Boundary Upper X Point";
CM_ SG_ 290 L_ATCU_HU_FrDrEVntCtrBdryUp_Y "Front Driver Electric Vent Center Boundary Upper Y Point";
CM_ SG_ 290 L_ATCU_HU_FrDrEVntCtrBdryLo_X "Front Driver Electric Vent Center Boundary Lower X Point";
CM_ SG_ 290 L_ATCU_HU_FrDrEVntCtrBdryLo_Y "Front Driver Electric Vent Center Boundary Lower Y Point";
CM_ SG_ 290 L_ATCU_HU_FrDrEVntSideBdryUp_Y "Front Driver Electric Vent Side Boundary Upper Y Point";
CM_ BO_ 291 "[P] Periodic";
CM_ SG_ 291 L_ATCU_HU_FrPsEVntSideBdryUp_X "Front Passenger Electric Vent Side Boundary Upper X Point";
CM_ SG_ 291 L_ATCU_HU_FrPsEVntSideBdryLo_X "Front Passenger Electric Vent Side Boundary Lower X Point";
CM_ SG_ 291 L_ATCU_HU_FrPsEVntSideBdryLo_Y "Front Passenger Electric Vent Side Boundary Lower Y Point";
CM_ SG_ 291 L_ATCU_HU_FrPsEVntCtrBdryUp_X "Front Passenger Electric Vent Center Boundary Upper X Point";
CM_ SG_ 291 L_ATCU_HU_FrPsEVntCtrBdryUp_Y "Front Passenger Electric Vent Center Boundary Upper Y Point";
CM_ SG_ 291 L_ATCU_HU_FrPsEVntCtrBdryLo_X "Front Passenger Electric Vent Center Boundary Lower X Point";
CM_ SG_ 291 L_ATCU_HU_FrPsEVntCtrBdryLo_Y "Front Passenger Electric Vent Center Boundary Lower Y Point";
CM_ SG_ 291 L_ATCU_HU_FrPsEVntSideBdryUp_Y "Front Passenger Electric Vent Side Boundary Upper Y Point";
CM_ BO_ 292 "[P] Periodic";
CM_ SG_ 292 L_ATCU_HU_RrDrEVntConsBdryUp_X "Rear Driver Electric Vent Console Boundary Upper X Point";
CM_ SG_ 292 L_ATCU_HU_RrDrEVntConsBdryLo_X "Rear Driver Electric Vent Console Boundary Lower X Point";
CM_ SG_ 292 L_ATCU_HU_RrDrEVntConsBdryLo_Y "Rear Driver Electric Vent Console Boundary Lower Y Point";
CM_ SG_ 292 L_ATCU_HU_RrPsEVntConsBdryUp_X "Rear Passenger Electric Vent Console Boundary Upper X Point";
CM_ SG_ 292 L_ATCU_HU_RrPsEVntConsBdryUp_Y "Rear Passenger Electric Vent Console Boundary Upper Y Point";
CM_ SG_ 292 L_ATCU_HU_RrPsEVntConsBdryLo_X "Rear Passenger Electric Vent Console Boundary Lower X Point";
CM_ SG_ 292 L_ATCU_HU_RrPsEVntConsBdryLo_Y "Rear Passenger Electric Vent Console Boundary Lower Y Point";
CM_ SG_ 292 L_ATCU_HU_RrDrEVntConsBdryUp_Y "Rear Driver Electric Vent Console Boundary Upper Y Point";
CM_ BO_ 293 "[EC] On Event and On Change";
CM_ SG_ 293 L_ATCU_CTS_FrDrEVntSidePt_X "Front Driver Electric Vent Side Touch Point X Value";
CM_ SG_ 293 L_ATCU_CTS_FrDrEVntSidePt_Y "Front Driver Electric Vent Side Touch Point Y Value";
CM_ SG_ 293 L_ATCU_CTS_FrDrEVntCtrPt_X "Front Driver Electric Vent Center Touch Point X Value";
CM_ SG_ 293 L_ATCU_CTS_FrDrEVntCtrPt_Y "Front Driver Electric Vent Center Touch Point Y Value";
CM_ BO_ 294 "[EC] On Event and On Change";
CM_ SG_ 294 L_ATCU_CTS_FrPsEVntSidePt_X "Front Passenger Electric Vent Side Touch Point X Value";
CM_ SG_ 294 L_ATCU_CTS_FrPsEVntSidePt_Y "Front Passenger Electric Vent Side Touch Point Y Value";
CM_ SG_ 294 L_ATCU_CTS_FrPsEVntCtrPt_X "Front Passenger Electric Vent Center Touch Point X Value";
CM_ SG_ 294 L_ATCU_CTS_FrPsEVntCtrPt_Y "Front Passenger Electric Vent Center Touch Point Y Value";
CM_ BO_ 295 "[EC] On Event and On Change";
CM_ SG_ 295 L_ATCU_CTS_RrDrEVntConsPt_X "Rear Driver Electric Vent Console Touch Point  X Value";
CM_ SG_ 295 L_ATCU_CTS_RrDrEVntConsPt_Y "Rear Driver Electric Vent Console Touch Point  Y Value";
CM_ SG_ 295 L_ATCU_CTS_RrPsEVntConsPt_X "Rear Passenger Electric Vent Console Touch Point  X Value";
CM_ SG_ 295 L_ATCU_CTS_RrPsEVntConsPt_Y "Rear Passenger Electric Vent Console Touch Point  Y Value";
CM_ SG_ 295 L_ATCU_CTS_RrDrEVntModeSet "Rear Driver Electric Vent Mode Set";
CM_ SG_ 295 L_ATCU_CTS_RrPsEVntModeSet "Rear Passenger Electric Vent Mode Set";
CM_ SG_ 295 L_ATCU_CTS_RrDrEVntConsOpnCls "Rear Driver Electric Vent Console Open Close Signal";
CM_ SG_ 295 L_ATCU_CTS_RrPsEVntConsOpnCls "Rear Passenger Electric Vent Console Open Close Signal";
CM_ BO_ 296 "[P] Periodic";
CM_ SG_ 296 L_ATCU_CTS_FrDrEVntSideBdryUp_X "Front Driver Electric Vent Side Boundary Upper X Point";
CM_ SG_ 296 L_ATCU_CTS_FrDrEVntSideBdryLo_X "Front Driver Electric Vent Side Boundary Lower X Point";
CM_ SG_ 296 L_ATCU_CTS_FrDrEVntSideBdryLo_Y "Front Driver Electric Vent Side Boundary Lower Y Point";
CM_ SG_ 296 L_ATCU_CTS_FrDrEVntCtrBdryUp_X "Front Driver Electric Vent Center Boundary Upper X Point";
CM_ SG_ 296 L_ATCU_CTS_FrDrEVntCtrBdryUp_Y "Front Driver Electric Vent Center Boundary Upper Y Point";
CM_ SG_ 296 L_ATCU_CTS_FrDrEVntCtrBdryLo_X "Front Driver Electric Vent Center Boundary Lower X Point";
CM_ SG_ 296 L_ATCU_CTS_FrDrEVntCtrBdryLo_Y "Front Driver Electric Vent Center Boundary Lower Y Point";
CM_ SG_ 296 L_ATCU_CTS_FrDrEVntSideBdryUp_Y "Front Driver Electric Vent Side Boundary Upper Y Point";
CM_ BO_ 297 "[P] Periodic";
CM_ SG_ 297 L_ATCU_CTS_FrPsEVntSideBdryUp_X "Front Passenger Electric Vent Side Boundary Upper X Point";
CM_ SG_ 297 L_ATCU_CTS_FrPsEVntSideBdryLo_X "Front Passenger Electric Vent Side Boundary Lower X Point";
CM_ SG_ 297 L_ATCU_CTS_FrPsEVntSideBdryLo_Y "Front Passenger Electric Vent Side Boundary Lower Y Point";
CM_ SG_ 297 L_ATCU_CTS_FrPsEVntCtrBdryUp_X "Front Passenger Electric Vent Center Boundary Upper X Point";
CM_ SG_ 297 L_ATCU_CTS_FrPsEVntCtrBdryUp_Y "Front Passenger Electric Vent Center Boundary Upper Y Point";
CM_ SG_ 297 L_ATCU_CTS_FrPsEVntCtrBdryLo_X "Front Passenger Electric Vent Center Boundary Lower X Point";
CM_ SG_ 297 L_ATCU_CTS_FrPsEVntCtrBdryLo_Y "Front Passenger Electric Vent Center Boundary Lower Y Point";
CM_ SG_ 297 L_ATCU_CTS_FrPsEVntSideBdryUp_Y "Front Passenger Electric Vent Side Boundary Upper Y Point";
CM_ BO_ 769 "[PE] Periodic and On Event";
CM_ SG_ 769 MON_BatteryInit "ATCU Monitoring Function Battery Init Req";
CM_ SG_ 769 MON_StableStateSnsr "ATCU Monitoring Function Sensor Stable State";
CM_ SG_ 769 MON_KeepMonitorReq "ATCU Monitoring Function Keep Operating Req";
CM_ SG_ 769 MON_DevInputCtrlReq "ATCU Monitoring Function Development Mode Request";
CM_ BO_ 770 "[PE] Periodic and On Event";
CM_ SG_ 770 MON_InCarTempSnsr "ATCU Monitoring InCarTemp Raw Value";
CM_ SG_ 770 MON_AMBTempSnsr "ATCU Monitoring AmbTemp Raw Value";
CM_ SG_ 770 MON_EvapTempSnsr "ATCU Monitoring EvapTemp Raw Value";
CM_ SG_ 770 MON_DOHSnsr "ATCU Monitoring DOH Raw Value";
CM_ BO_ 771 "[PE] Periodic and On Event";
CM_ SG_ 771 MON_FineDustSnsr "ATCU Monitoring FineDust Raw Value";
CM_ SG_ 771 MON_LHPhotoSnsr "ATCU Monitoring Photo Sensor(Drv) Raw Value";
CM_ SG_ 771 MON_RHPhotoSnsr "ATCU Monitoring Photo Sensor(Ast) Raw Value";
CM_ BO_ 772 "[PE] Periodic and On Event";
CM_ SG_ 772 MON_DrvVentDuctSnsr "ATCU Monitoring Driver Vent Duct Temp Raw Value";
CM_ SG_ 772 MON_AstVentDuctSnsr "ATCU Monitoring Assist Vent Duct Temp Raw Value";
CM_ SG_ 772 MON_DrvFloorDuctSnsr "ATCU Monitoring Driver Floor Duct Temp Raw Value";
CM_ SG_ 772 MON_AstFloorDuctSnsr "ATCU Monitoring Assist Floor Duct Temp Raw Value";
CM_ BO_ 773 "[PE] Periodic and On Event";
CM_ SG_ 773 MON_DEFDuctSnsr "ATCU Monitoring DEF Duct Temp Raw Value";
CM_ SG_ 773 MON_RrFloorDuctSnsr "ATCU Monitoring 2nd LH Vent Duct Temp Raw Value";
CM_ SG_ 773 MON_RrVentDuctSnsr "ATCU Monitoring 2nd LH Floor Duct Temp Raw Value";
CM_ SG_ 773 MON_PMSnsrSta "ATCU Monitoring PM Sensor State";
CM_ BO_ 774 "[PE] Periodic and On Event";
CM_ SG_ 774 MON_IGN1 "ATCU Monitoring Function Ignition1 power test state";
CM_ SG_ 774 MON_IGN2 "ATCU Monitoring Function Ignition2 power test state";
CM_ SG_ 774 MON_VBAT "ATCU Monitoring Function Battery Voltage";
CM_ SG_ 774 MON_IGN3 "ATCU Monitoring Function Ignition3 power test state";
CM_ SG_ 774 MON_PTCRly1 "ATCU Monitoring Function PTC operation test state";
CM_ SG_ 774 MON_PTCRlyVtg "ATCU Monitoring Function PTC Relay voltage test state";
CM_ BO_ 775 "[PE] Periodic and On Event";
CM_ SG_ 775 MON_RgnOpt "ATCU Monitoring Test Mode Region Option";
CM_ SG_ 775 MON_DrvOnlyOpt "ATCU Monitoring Test Mode DriverOnly Option";
CM_ SG_ 775 MON_ADSOpt "ATCU Monitoring Test Mode ATCU Library ADS Option";
CM_ SG_ 775 MON_AfterBlowOpt "ATCU Monitoring Test Mode AfterBlow Option";
CM_ SG_ 775 MON_SchdldVentOpt "ATCU Monitoring Test Mode Schduled Ventilation Option";
CM_ SG_ 775 MON_FineDustOpt "ATCU Monitoring Test Mode FineDust Option";
CM_ SG_ 775 MON_FrontSyncCtrlTypOpt "ATCU Monitoring Test Mode Sync Option";
CM_ SG_ 775 MON_CompOpt "ATCU Monitoring Test Mode Compressor Type";
CM_ SG_ 775 MON_WheelDrivePosOpt "ATCU Monitoring Test Mode Drive Wheel Position Type";
CM_ SG_ 775 MON_NetworkTypOpt "ATCU Monitoring Test Mode NetworkType";
CM_ SG_ 775 MON_AutoSwTyp "ATCU Monitoring Test Mode Auto Switch Type(1/2 button)";
CM_ SG_ 775 MON_ModSwTypOpt "ATCU Monitoring Test Mode Mode Switch Type(1/2/3 button) Option";
CM_ SG_ 775 MON_IntakeSwTypOpt "ATCU Monitoring Test Mode Intake Switch Type(1/2 button) Option";
CM_ SG_ 775 MON_OffSwTypOpt "ATCU Monitoring Test Mode Off Switch Type(Off/DownOff) Option";
CM_ SG_ 775 MON_TempSwKnobOpt "ATCU Monitoring Test Mode Temp Knob Option";
CM_ SG_ 775 MON_BlrSwKnobOpt "ATCU Monitoring Test Mode Blower Knob Option";
CM_ SG_ 775 MON_BATCoolingTypOpt "ATCU Monitoring Test Mode Battery Cooling Type";
CM_ SG_ 775 MON_PTCStepOpt "ATCU Monitoring Test Mode PTC Step Option";
CM_ SG_ 775 MON_PTCTypOpt "ATCU Monitoring Test Mode PTC Type";
CM_ SG_ 775 MON_ThermostatOpt "ATCU Monitoring Test Mode Thermostat Option";
CM_ SG_ 775 MON_SmartVentOpt "ATCU Monitoring Test Mode SmartVent Option";
CM_ SG_ 775 MON_ROATypOpt "ATCU Monitoring Test Mode ROA Option";
CM_ SG_ 775 MON_VehTypOpt "ATCU Monitoring Test Mode Vehicle Type (ICE/HEV/EV)";
CM_ SG_ 775 MON_VRLedOpt "ATCU Monitoring Test Mode VR LED Option";
CM_ SG_ 775 MON_FrontAutoStepOpt "ATCU Monitoring Test Mode Auto Step Option";
CM_ SG_ 775 MON_2ndAutoStepOpt "ATCU Monitoring Test Mode 2nd Auto Step Option";
CM_ SG_ 775 MON_2ndAutoSwTyp "ATCU Monitoring Test Mode 2nd Auto Switch Type(1/2 button)";
CM_ SG_ 775 MON_2ndOffSwTypOpt "ATCU Monitoring Test Mode 2nd Off Switch Type(Off/DownOff) Option";
CM_ SG_ 775 MON_2ndModSwTypOpt "ATCU Monitoring Test Mode 2nd Mode Switch Type(1/2/3 button) Option";
CM_ SG_ 775 MON_2ndAutoBtnOpt "ATCU Monitoring Test Mode 2nd Auto Type (Single/Dual)";
CM_ SG_ 775 MON_2ndBlrBtnOpt "ATCU Monitoring Test Mode 2nd Blower Type (Single/Dual)";
CM_ SG_ 775 MON_2ndModBtnOpt "ATCU Monitoring Test Mode 2nd Mode Type (Single/Dual)";
CM_ SG_ 775 MON_2ndTmpBtnOpt "ATCU Monitoring Test Mode 2nd Temp Type (Single/Dual)";
CM_ SG_ 775 MON_2ndTempSwKnobOpt "ATCU Monitoring Test Mode 2nd Temp Knob Option";
CM_ SG_ 775 MON_DrvHndSideOpt "ATCU Monitoring Test Mode Driver Handel Side Type";
CM_ SG_ 775 MON_DisplayOpt "ATCU Monitoring Test Mode LCD Display Type";
CM_ BO_ 778 "[PE] Periodic and On Event";
CM_ SG_ 778 MON_Auto2LHBlrVtgVal "ATCU Monitoring Test mode AutoLogic:2nd Leftside Blower Voltage";
CM_ SG_ 778 MON_Auto2LHModState "ATCU Monitoring Test mode AutoLogic:2nd Leftside Mode";
CM_ SG_ 778 MON_Auto2LHTempDrState "ATCU Monitoring Test mode AutoLogic:2nd Leftside Temp Door";
CM_ SG_ 778 MON_AutoHeatloadStep "ATCU Monitoring Test mode AutoLogic:Heatload Step";
CM_ SG_ 778 MON_AutoHVPTCDuty "ATCU Monitoring Test mode AutoLogic:High Voltage PTC Duty";
CM_ SG_ 778 MON_AutoECompRpm "ATCU Monitoring Test mode AutoLogic:Electric Comprossor RPM";
CM_ BO_ 797 "[PE] Periodic and On Event";
CM_ SG_ 797 MON_AutoDrvTempDrVtgVal "ATCU Monitoring Test mode AutoLogic:Driverside Temp Door Voltage Value";
CM_ SG_ 797 MON_AutoAstTempDrVtgVal "ATCU Monitoring Test mode AutoLogic:Driverside Temp Door Voltage Value";
CM_ SG_ 797 MON_AutoDrv2TempDrVtgVal "ATCU Monitoring Test mode AutoLogic:Driverside Temp Door Voltage Value";
CM_ SG_ 797 MON_ADSTempDrLmtState "ATCU Monitoring Test mode ADS TempDoor Limited State";
CM_ BO_ 798 "[PE] Periodic and On Event";
CM_ SG_ 798 MON_ADSModState "ATCU Monitoring Test mode ADS Mode State";
CM_ SG_ 798 MON_ADSACForcedOnReq "ATCU Monitoring Test mode ADS Forced On Request";
CM_ SG_ 798 MON_ADSACDispPreValHoldReq "ATCU Monitoring Test mode ADS AC Indicator Hold Req";
CM_ SG_ 798 MON_ADSSymState "ATCU Monitoring Test mode ADS Symbol";
CM_ SG_ 798 MON_ADSInhibitPIReq "ATCU Monitoring Test mode ADS Mode State";
CM_ SG_ 798 MON_ADSOpState "ATCU Monitoring Test mode ADS Operating State";
CM_ SG_ 798 MON_ADSBlrVtgVal "ATCU Monitoring Test mode ADS Blower Voltage Value";
CM_ SG_ 798 MON_ADSIntakeState "ATCU Monitoring Test mode ADS Intake";
CM_ SG_ 798 MON_ADSDEFDrState "ATCU Monitoring Test mode ADS DEF Door";
CM_ SG_ 798 MON_ADSModPrfleChgReq "ATCU Monitoring Test mode ADS Mode Profile Change Request";
CM_ SG_ 798 MON_ADSACState "ATCU Monitoring Test mode ADS AC";
CM_ BO_ 779 "[PE] Periodic and On Event";
CM_ SG_ 779 MON_StatMngr_Humid "ATCU Monitoring Test mode StateManagement Control (Humid)";
CM_ BO_ 780 "[PE] Periodic and On Event";
CM_ SG_ 780 MON_StatMngr_Temp "ATCU Monitoring Test mode StateManagement Control (Temp)";
CM_ BO_ 781 "[PE] Periodic and On Event";
CM_ SG_ 781 MON_StatMngr_SafetynCool "ATCU Monitoring Test mode StateManagement Control (SafetynCool)";
CM_ BO_ 782 "[PE] Periodic and On Event";
CM_ SG_ 782 MON_StatMngr_Mngr "ATCU Monitoring Test mode StateManagement Control (Mngr)";
CM_ BO_ 783 "[PE] Periodic and On Event";
CM_ SG_ 783 MON_StatMngr_Convenience "ATCU Monitoring Test mode StateManagement Control (Convenience)";
CM_ BO_ 784 "[PE] Periodic and On Event";
CM_ SG_ 784 MON_StatMngr_AirQuality "ATCU Monitoring Test mode StateManagement Control (AirQuality)";
CM_ BO_ 792 "[PE] Periodic and On Event";
CM_ SG_ 792 MON_StatMngr_2ndConvenience "ATCU Monitoring Test mode StateManagement Control (2ndConvenience)";
CM_ BO_ 793 "[PE] Periodic and On Event";
CM_ SG_ 793 MON_StatMngr_2ndAirQuality "ATCU Monitoring Test mode StateManagement Control (2ndAirQuality)";
CM_ BO_ 794 "[PE] Periodic and On Event";
CM_ SG_ 794 MON_StatMngr_2ndETC "ATCU Monitoring Test mode StateManagement Control (2ndETC)";
CM_ BO_ 795 "[PE] Periodic and On Event";
CM_ SG_ 795 MON_StatMngr_2ndFuelEfficiency "ATCU Monitoring Test mode StateManagement Control (2ndFuelEfficiency)";
BA_DEF_ BO_ "UsrMsgIDSforwardDeviation" INT 0 100 ;
BA_DEF_ BO_ "UsrMsgIDSbackwardDeviation" INT 50 1000 ;
BA_DEF_ BO_ "GenMsgCycleTime" INT 0 2000 ;
BA_DEF_ BO_ "GenMsgStartDelayTime" INT 0 2000 ;
BA_DEF_ BO_ "GenMsgSendType" ENUM "Cyclic","NoMsgSendType" ;
BA_DEF_ BO_ "GenMsgCycleTimeFast" INT 0 500 ;
BA_DEF_ BO_ "GenMsgDelayTime" INT 0 20 ;
BA_DEF_ BO_ "GenMsgILSupport" ENUM "No","Yes" ;
BA_DEF_ BO_ "GenMsgNrOfRepetition" INT 0 3 ;
BA_DEF_ BO_ "VFrameFormat" ENUM "StandardCAN","ExtendedCAN","reserved","reserved","reserved","reserved","reserved","reserved","reserved","reserved","reserved","reserved","reserved","reserved","StandardCAN_FD","ExtendedCAN_FD" ;
BA_DEF_ SG_ "UserSigValidity" ENUM "B+","ACC","IG","IG1","IG2","IG3","IG1 or IG2","IG1 or IG3","Undef" ;
BA_DEF_ SG_ "UsrSigPurpose" ENUM "Undef","FN","DIAG","DIAG(Req)","DIAG(Res)","DIAG(Phy)","DEV","CCP(Req)","CCP(Res)","NM","TP" ;
BA_DEF_ SG_ "GenSigStartValue" INT 0 1215752192 ;
BA_DEF_ SG_ "NetworkRequestHoldingTime" INT 0 65535 ;
BA_DEF_ SG_ "Description" STRING ;
BA_DEF_ SG_ "Version" STRING ;
BA_DEF_ SG_ "GenSigEnvVarType" ENUM "Int","Float","Undef" ;
BA_DEF_ SG_ "GenSigSendType" ENUM "Cyclic","OnWrite","OnWriteWithRepetition","OnChange","OnChangeWithRepetition","IfActive","IfActiveWithRepetition","NoSigSendType","OnChangeAndIfActive","OnChangeAndIfActiveWithRepetition" ;
BA_DEF_ SG_ "GwSigLatencyTime" INT 0 65536 ;
BA_DEF_ SG_ "GwSigMissingSourceType" ENUM "Undef","OldValue","DefaultValue","InitialValue" ;
BA_DEF_ SG_ "NWM-WakeupAllowed" ENUM "<n.a.>" ;
BA_DEF_ SG_ "RoutingFactor" INT 1 1215752192 ;
BA_DEF_REL_ BU_SG_REL_ "GenSigTimeoutTime" INT 0 7000 ;
BA_DEF_DEF_ "UsrMsgIDSforwardDeviation" 10 ;
BA_DEF_DEF_ "UsrMsgIDSbackwardDeviation" 100 ;
BA_DEF_DEF_ "GenMsgCycleTime" 200 ;
BA_DEF_DEF_ "GenMsgStartDelayTime" 0 ;
BA_DEF_DEF_ "GenMsgSendType" "NoMsgSendType" ;
BA_DEF_DEF_ "GenMsgCycleTimeFast" 40 ;
BA_DEF_DEF_ "GenMsgDelayTime" 20 ;
BA_DEF_DEF_ "GenMsgILSupport" "Yes" ;
BA_DEF_DEF_ "GenMsgNrOfRepetition" 3 ;
BA_DEF_DEF_ "VFrameFormat" "StandardCAN" ;
BA_DEF_DEF_ "UserSigValidity" "IG" ;
BA_DEF_DEF_ "UsrSigPurpose" "FN" ;
BA_DEF_DEF_ "GenSigStartValue" 0 ;
BA_DEF_DEF_ "NetworkRequestHoldingTime" 0 ;
BA_DEF_DEF_ "Description" "" ;
BA_DEF_DEF_ "Version" "" ;
BA_DEF_DEF_ "GenSigEnvVarType" "Undef" ;
BA_DEF_DEF_ "GenSigSendType" "NoSigSendType" ;
BA_DEF_DEF_ "GwSigLatencyTime" 40 ;
BA_DEF_DEF_ "GwSigMissingSourceType" "Undef" ;
BA_DEF_DEF_ "NWM-WakeupAllowed" "<n.a.>" ;
BA_DEF_DEF_ "RoutingFactor" 1 ;
BA_DEF_DEF_REL_ "GenSigTimeoutTime" 500 ;
BA_ "GenMsgSendType" BO_ 36 0;
BA_ "GenSigSendType" SG_ 36 L_ATCU_ArClnIntroEvt 4;
BA_ "UserSigValidity" SG_ 36 L_ATCU_ArClnIntroEvt 7;
BA_REL_ "GenSigTimeoutTime" BU_SG_REL_ L_HKBD SG_ 36 L_ATCU_ArClnIntroEvt 1500;
BA_ "Version" SG_ 36 L_ATCU_ArClnIntroEvt "23.08.13";
BA_ "Description" SG_ 36 L_ATCU_ArClnSmblClr "This signal indicates the information about Color of AirCleaning Symbol displaying in the AVN";
BA_ "GenSigSendType" SG_ 36 L_ATCU_ArClnSmblClr 4;
BA_ "UserSigValidity" SG_ 36 L_ATCU_ArClnSmblClr 7;
BA_REL_ "GenSigTimeoutTime" BU_SG_REL_ L_HKBD SG_ 36 L_ATCU_ArClnSmblClr 1500;
BA_ "Version" SG_ 36 L_ATCU_ArClnSmblClr "23.08.13";
BA_ "GenSigSendType" SG_ 36 L_ATCU_DustLevelDis 4;
BA_ "UserSigValidity" SG_ 36 L_ATCU_DustLevelDis 7;
BA_REL_ "GenSigTimeoutTime" BU_SG_REL_ L_HKBD SG_ 36 L_ATCU_DustLevelDis 1500;
BA_ "Version" SG_ 36 L_ATCU_DustLevelDis "23.08.13";
BA_ "GenSigSendType" SG_ 36 L_ATCU_DustBarDisOff 4;
BA_ "UserSigValidity" SG_ 36 L_ATCU_DustBarDisOff 7;
BA_REL_ "GenSigTimeoutTime" BU_SG_REL_ L_HKBD SG_ 36 L_ATCU_DustBarDisOff 1500;
BA_ "Version" SG_ 36 L_ATCU_DustBarDisOff "23.08.13";
BA_ "GenSigSendType" SG_ 36 L_ATCU_DustSnrStepDis 4;
BA_ "UserSigValidity" SG_ 36 L_ATCU_DustSnrStepDis 7;
BA_REL_ "GenSigTimeoutTime" BU_SG_REL_ L_HKBD SG_ 36 L_ATCU_DustSnrStepDis 1500;
BA_ "Version" SG_ 36 L_ATCU_DustSnrStepDis "23.08.13";
BA_ "GenSigSendType" SG_ 36 L_ATCU_FragStrhDis 4;
BA_ "UserSigValidity" SG_ 36 L_ATCU_FragStrhDis 7;
BA_REL_ "GenSigTimeoutTime" BU_SG_REL_ L_HKBD SG_ 36 L_ATCU_FragStrhDis 1500;
BA_REL_ "GenSigTimeoutTime" BU_SG_REL_ L_PCM SG_ 36 L_ATCU_FragStrhDis 1500;
BA_ "Version" SG_ 36 L_ATCU_FragStrhDis "23.08.13";
BA_ "Description" SG_ 36 L_ATCU_FragKindDis "This singal indicates display value of Fragnance kind";
BA_ "GenSigSendType" SG_ 36 L_ATCU_FragKindDis 4;
BA_ "UserSigValidity" SG_ 36 L_ATCU_FragKindDis 7;
BA_REL_ "GenSigTimeoutTime" BU_SG_REL_ L_HKBD SG_ 36 L_ATCU_FragKindDis 1500;
BA_REL_ "GenSigTimeoutTime" BU_SG_REL_ L_PCM SG_ 36 L_ATCU_FragKindDis 1500;
BA_ "Version" SG_ 36 L_ATCU_FragKindDis "24.05.08";
BA_ "Description" SG_ 36 L_ATCU_Frag1Inform "This signal indicates Information of Fragrance 1";
BA_ "GenSigSendType" SG_ 36 L_ATCU_Frag1Inform 4;
BA_ "UserSigValidity" SG_ 36 L_ATCU_Frag1Inform 7;
BA_REL_ "GenSigTimeoutTime" BU_SG_REL_ L_HKBD SG_ 36 L_ATCU_Frag1Inform 1500;
BA_REL_ "GenSigTimeoutTime" BU_SG_REL_ L_PCM SG_ 36 L_ATCU_Frag1Inform 1500;
BA_ "Version" SG_ 36 L_ATCU_Frag1Inform "25.04.02";
BA_ "Description" SG_ 36 L_ATCU_Frag2Inform "This signal indicates Information of Fragrance 2";
BA_ "GenSigSendType" SG_ 36 L_ATCU_Frag2Inform 4;
BA_ "UserSigValidity" SG_ 36 L_ATCU_Frag2Inform 7;
BA_REL_ "GenSigTimeoutTime" BU_SG_REL_ L_HKBD SG_ 36 L_ATCU_Frag2Inform 1500;
BA_REL_ "GenSigTimeoutTime" BU_SG_REL_ L_PCM SG_ 36 L_ATCU_Frag2Inform 1500;
BA_ "Version" SG_ 36 L_ATCU_Frag2Inform "25.04.02";
BA_ "Description" SG_ 36 L_ATCU_Frag1RemainDisp "This signal indicates Remain Display of Ragrnace No.1";
BA_ "GenSigSendType" SG_ 36 L_ATCU_Frag1RemainDisp 4;
BA_ "UserSigValidity" SG_ 36 L_ATCU_Frag1RemainDisp 7;
BA_REL_ "GenSigTimeoutTime" BU_SG_REL_ L_HKBD SG_ 36 L_ATCU_Frag1RemainDisp 1500;
BA_REL_ "GenSigTimeoutTime" BU_SG_REL_ L_PCM SG_ 36 L_ATCU_Frag1RemainDisp 1500;
BA_ "Version" SG_ 36 L_ATCU_Frag1RemainDisp "23.08.13";
BA_ "Description" SG_ 36 L_ATCU_Frag2RemainDisp "This signal indicates Remain Display of Ragrnace No.2";
BA_ "GenSigSendType" SG_ 36 L_ATCU_Frag2RemainDisp 4;
BA_ "UserSigValidity" SG_ 36 L_ATCU_Frag2RemainDisp 7;
BA_REL_ "GenSigTimeoutTime" BU_SG_REL_ L_2HKBD SG_ 36 L_ATCU_Frag2RemainDisp 1500;
BA_REL_ "GenSigTimeoutTime" BU_SG_REL_ L_HKBD SG_ 36 L_ATCU_Frag2RemainDisp 1500;
BA_ "Version" SG_ 36 L_ATCU_Frag2RemainDisp "23.08.13";
BA_ "Description" SG_ 36 L_ATCU_ArClnSmblTyp "This signal indicate the feature of Air Cleaning Symbol displaying in the AVN";
BA_ "GenSigSendType" SG_ 36 L_ATCU_ArClnSmblTyp 4;
BA_ "UserSigValidity" SG_ 36 L_ATCU_ArClnSmblTyp 7;
BA_REL_ "GenSigTimeoutTime" BU_SG_REL_ L_HKBD SG_ 36 L_ATCU_ArClnSmblTyp 1500;
BA_ "Version" SG_ 36 L_ATCU_ArClnSmblTyp "23.08.13";
BA_ "Description" SG_ 36 L_ATCU_FrtBlwMaxLvlVaild "This signal indicates the maximum step of Front Blower according to multi auto steps.";
BA_ "GenSigSendType" SG_ 36 L_ATCU_FrtBlwMaxLvlVaild 4;
BA_ "UserSigValidity" SG_ 36 L_ATCU_FrtBlwMaxLvlVaild 7;
BA_REL_ "GenSigTimeoutTime" BU_SG_REL_ L_2HKBD SG_ 36 L_ATCU_FrtBlwMaxLvlVaild 1500;
BA_REL_ "GenSigTimeoutTime" BU_SG_REL_ L_HKBD SG_ 36 L_ATCU_FrtBlwMaxLvlVaild 1500;
BA_ "Version" SG_ 36 L_ATCU_FrtBlwMaxLvlVaild "23.08.13";
BA_ "GenSigSendType" SG_ 36 L_ATCU_OpSta 4;
BA_ "UserSigValidity" SG_ 36 L_ATCU_OpSta 7;
BA_REL_ "GenSigTimeoutTime" BU_SG_REL_ L_EVNT SG_ 36 L_ATCU_OpSta 1500;
BA_REL_ "GenSigTimeoutTime" BU_SG_REL_ L_HKBD SG_ 36 L_ATCU_OpSta 1500;
BA_ "Version" SG_ 36 L_ATCU_OpSta "23.08.13";
BA_ "Description" SG_ 36 L_ATCU_TempDispUnit "This signal is unit of Temperature display";
BA_ "GenSigSendType" SG_ 36 L_ATCU_TempDispUnit 4;
BA_ "UserSigValidity" SG_ 36 L_ATCU_TempDispUnit 7;
BA_REL_ "GenSigTimeoutTime" BU_SG_REL_ L_2HKBD SG_ 36 L_ATCU_TempDispUnit 1500;
BA_REL_ "GenSigTimeoutTime" BU_SG_REL_ L_HKBD SG_ 36 L_ATCU_TempDispUnit 1500;
BA_ "Version" SG_ 36 L_ATCU_TempDispUnit "24.05.08";
BA_ "GenSigSendType" SG_ 36 L_ATCU_DrvAUTOStep 4;
BA_ "UserSigValidity" SG_ 36 L_ATCU_DrvAUTOStep 7;
BA_REL_ "GenSigTimeoutTime" BU_SG_REL_ L_HKBD SG_ 36 L_ATCU_DrvAUTOStep 1500;
BA_ "Version" SG_ 36 L_ATCU_DrvAUTOStep "23.08.13";
BA_ "Description" SG_ 36 L_ATCU_DiagCodeDis "0x1~0x3FE:PHY=(HEX*1.0-1.0)";
BA_ "GenSigSendType" SG_ 36 L_ATCU_DiagCodeDis 4;
BA_ "UserSigValidity" SG_ 36 L_ATCU_DiagCodeDis 7;
BA_REL_ "GenSigTimeoutTime" BU_SG_REL_ L_HKBD SG_ 36 L_ATCU_DiagCodeDis 1500;
BA_ "Version" SG_ 36 L_ATCU_DiagCodeDis "23.08.13";
BA_ "GenMsgSendType" BO_ 37 0;
BA_ "Description" SG_ 37 L_ATCU_RrOpSta "ATCU_RearOperationStatus";
BA_ "GenSigSendType" SG_ 37 L_ATCU_RrOpSta 4;
BA_ "UserSigValidity" SG_ 37 L_ATCU_RrOpSta 7;
BA_REL_ "GenSigTimeoutTime" BU_SG_REL_ L_2HKBD SG_ 37 L_ATCU_RrOpSta 1500;
BA_REL_ "GenSigTimeoutTime" BU_SG_REL_ L_HKBD SG_ 37 L_ATCU_RrOpSta 1500;
BA_ "Version" SG_ 37 L_ATCU_RrOpSta "24.08.00";
BA_ "Description" SG_ 37 L_ATCU_RrDrvTempFDis "This signal indicates Outside Temperature (¢µ)

(Use for display only)";
BA_ "GenSigSendType" SG_ 37 L_ATCU_RrDrvTempFDis 4;
BA_ "UserSigValidity" SG_ 37 L_ATCU_RrDrvTempFDis 7;
BA_REL_ "GenSigTimeoutTime" BU_SG_REL_ L_2HKBD SG_ 37 L_ATCU_RrDrvTempFDis 1500;
BA_REL_ "GenSigTimeoutTime" BU_SG_REL_ L_HKBD SG_ 37 L_ATCU_RrDrvTempFDis 1500;
BA_ "Version" SG_ 37 L_ATCU_RrDrvTempFDis "23.08.13";
BA_ "Description" SG_ 37 L_ATCU_RrDrvModDis "ATCU_RearDriverModeDisplay";
BA_ "GenSigSendType" SG_ 37 L_ATCU_RrDrvModDis 4;
BA_ "UserSigValidity" SG_ 37 L_ATCU_RrDrvModDis 7;
BA_REL_ "GenSigTimeoutTime" BU_SG_REL_ L_2HKBD SG_ 37 L_ATCU_RrDrvModDis 1500;
BA_REL_ "GenSigTimeoutTime" BU_SG_REL_ L_EVNT SG_ 37 L_ATCU_RrDrvModDis 1500;
BA_REL_ "GenSigTimeoutTime" BU_SG_REL_ L_HKBD SG_ 37 L_ATCU_RrDrvModDis 1500;
BA_ "Version" SG_ 37 L_ATCU_RrDrvModDis "24.05.08";
BA_ "GenSigSendType" SG_ 37 L_ATCU_RrDrvBlwDis 4;
BA_ "UserSigValidity" SG_ 37 L_ATCU_RrDrvBlwDis 7;
BA_REL_ "GenSigTimeoutTime" BU_SG_REL_ L_2HKBD SG_ 37 L_ATCU_RrDrvBlwDis 1500;
BA_REL_ "GenSigTimeoutTime" BU_SG_REL_ L_HKBD SG_ 37 L_ATCU_RrDrvBlwDis 1500;
BA_ "Version" SG_ 37 L_ATCU_RrDrvBlwDis "23.08.13";
BA_ "GenSigSendType" SG_ 37 L_ATCU_RrDrvAutoDis 4;
BA_ "UserSigValidity" SG_ 37 L_ATCU_RrDrvAutoDis 7;
BA_REL_ "GenSigTimeoutTime" BU_SG_REL_ L_2HKBD SG_ 37 L_ATCU_RrDrvAutoDis 1500;
BA_REL_ "GenSigTimeoutTime" BU_SG_REL_ L_HKBD SG_ 37 L_ATCU_RrDrvAutoDis 1500;
BA_ "Version" SG_ 37 L_ATCU_RrDrvAutoDis "23.08.13";
BA_ "GenSigSendType" SG_ 37 L_ATCU_RrDrvMultiAutoBlwDis 4;
BA_ "UserSigValidity" SG_ 37 L_ATCU_RrDrvMultiAutoBlwDis 7;
BA_REL_ "GenSigTimeoutTime" BU_SG_REL_ L_2HKBD SG_ 37 L_ATCU_RrDrvMultiAutoBlwDis 1500;
BA_REL_ "GenSigTimeoutTime" BU_SG_REL_ L_HKBD SG_ 37 L_ATCU_RrDrvMultiAutoBlwDis 1500;
BA_ "Version" SG_ 37 L_ATCU_RrDrvMultiAutoBlwDis "23.08.13";
BA_ "Description" SG_ 37 L_ATCU_RrDrvTempCDis "This signal indicates Outside temperature (¡É).

(Use for display only)";
BA_ "GenSigSendType" SG_ 37 L_ATCU_RrDrvTempCDis 4;
BA_ "UserSigValidity" SG_ 37 L_ATCU_RrDrvTempCDis 7;
BA_REL_ "GenSigTimeoutTime" BU_SG_REL_ L_2HKBD SG_ 37 L_ATCU_RrDrvTempCDis 1500;
BA_REL_ "GenSigTimeoutTime" BU_SG_REL_ L_HKBD SG_ 37 L_ATCU_RrDrvTempCDis 1500;
BA_ "Version" SG_ 37 L_ATCU_RrDrvTempCDis "23.08.13";
BA_ "GenSigSendType" SG_ 37 L_ATCU_RrSyncDis 4;
BA_ "UserSigValidity" SG_ 37 L_ATCU_RrSyncDis 7;
BA_REL_ "GenSigTimeoutTime" BU_SG_REL_ L_2HKBD SG_ 37 L_ATCU_RrSyncDis 1500;
BA_REL_ "GenSigTimeoutTime" BU_SG_REL_ L_HKBD SG_ 37 L_ATCU_RrSyncDis 1500;
BA_ "Version" SG_ 37 L_ATCU_RrSyncDis "23.08.13";
BA_ "GenSigSendType" SG_ 37 L_ATCU_RrLcdBckLightSta 4;
BA_ "UserSigValidity" SG_ 37 L_ATCU_RrLcdBckLightSta 7;
BA_REL_ "GenSigTimeoutTime" BU_SG_REL_ L_2HKBD SG_ 37 L_ATCU_RrLcdBckLightSta 1500;
BA_REL_ "GenSigTimeoutTime" BU_SG_REL_ L_HKBD SG_ 37 L_ATCU_RrLcdBckLightSta 1500;
BA_ "Version" SG_ 37 L_ATCU_RrLcdBckLightSta "23.08.13";
BA_ "GenSigSendType" SG_ 37 L_ATCU_RrGUIBlankDis 4;
BA_ "UserSigValidity" SG_ 37 L_ATCU_RrGUIBlankDis 7;
BA_REL_ "GenSigTimeoutTime" BU_SG_REL_ L_2HKBD SG_ 37 L_ATCU_RrGUIBlankDis 1500;
BA_REL_ "GenSigTimeoutTime" BU_SG_REL_ L_HKBD SG_ 37 L_ATCU_RrGUIBlankDis 1500;
BA_ "Version" SG_ 37 L_ATCU_RrGUIBlankDis "23.08.13";
BA_ "GenSigSendType" SG_ 37 L_ATCU_RLStHeatSwHInd 4;
BA_ "UserSigValidity" SG_ 37 L_ATCU_RLStHeatSwHInd 7;
BA_REL_ "GenSigTimeoutTime" BU_SG_REL_ L_2HKBD SG_ 37 L_ATCU_RLStHeatSwHInd 1500;
BA_REL_ "GenSigTimeoutTime" BU_SG_REL_ L_HKBD SG_ 37 L_ATCU_RLStHeatSwHInd 1500;
BA_ "Version" SG_ 37 L_ATCU_RLStHeatSwHInd "23.08.13";
BA_ "GenSigSendType" SG_ 37 L_ATCU_RLStHeatSwMInd 4;
BA_ "UserSigValidity" SG_ 37 L_ATCU_RLStHeatSwMInd 7;
BA_REL_ "GenSigTimeoutTime" BU_SG_REL_ L_2HKBD SG_ 37 L_ATCU_RLStHeatSwMInd 1500;
BA_REL_ "GenSigTimeoutTime" BU_SG_REL_ L_HKBD SG_ 37 L_ATCU_RLStHeatSwMInd 1500;
BA_ "Version" SG_ 37 L_ATCU_RLStHeatSwMInd "23.08.13";
BA_ "GenSigSendType" SG_ 37 L_ATCU_RLStHeatSwLInd 4;
BA_ "UserSigValidity" SG_ 37 L_ATCU_RLStHeatSwLInd 7;
BA_REL_ "GenSigTimeoutTime" BU_SG_REL_ L_2HKBD SG_ 37 L_ATCU_RLStHeatSwLInd 1500;
BA_REL_ "GenSigTimeoutTime" BU_SG_REL_ L_HKBD SG_ 37 L_ATCU_RLStHeatSwLInd 1500;
BA_ "Version" SG_ 37 L_ATCU_RLStHeatSwLInd "23.08.13";
BA_ "GenSigSendType" SG_ 37 L_ATCU_RLStVntSwHInd 4;
BA_ "UserSigValidity" SG_ 37 L_ATCU_RLStVntSwHInd 7;
BA_REL_ "GenSigTimeoutTime" BU_SG_REL_ L_2HKBD SG_ 37 L_ATCU_RLStVntSwHInd 1500;
BA_REL_ "GenSigTimeoutTime" BU_SG_REL_ L_HKBD SG_ 37 L_ATCU_RLStVntSwHInd 1500;
BA_ "Version" SG_ 37 L_ATCU_RLStVntSwHInd "23.08.13";
BA_ "GenSigSendType" SG_ 37 L_ATCU_RLStVntSwMInd 4;
BA_ "UserSigValidity" SG_ 37 L_ATCU_RLStVntSwMInd 7;
BA_REL_ "GenSigTimeoutTime" BU_SG_REL_ L_2HKBD SG_ 37 L_ATCU_RLStVntSwMInd 1500;
BA_REL_ "GenSigTimeoutTime" BU_SG_REL_ L_HKBD SG_ 37 L_ATCU_RLStVntSwMInd 1500;
BA_ "Version" SG_ 37 L_ATCU_RLStVntSwMInd "23.08.13";
BA_ "GenSigSendType" SG_ 37 L_ATCU_RLStVntSwLInd 4;
BA_ "UserSigValidity" SG_ 37 L_ATCU_RLStVntSwLInd 7;
BA_REL_ "GenSigTimeoutTime" BU_SG_REL_ L_2HKBD SG_ 37 L_ATCU_RLStVntSwLInd 1500;
BA_REL_ "GenSigTimeoutTime" BU_SG_REL_ L_HKBD SG_ 37 L_ATCU_RLStVntSwLInd 1500;
BA_ "Version" SG_ 37 L_ATCU_RLStVntSwLInd "23.08.13";
BA_ "GenSigSendType" SG_ 37 L_ATCU_RRStHeatSwHInd 4;
BA_ "UserSigValidity" SG_ 37 L_ATCU_RRStHeatSwHInd 7;
BA_REL_ "GenSigTimeoutTime" BU_SG_REL_ L_2HKBD SG_ 37 L_ATCU_RRStHeatSwHInd 1500;
BA_REL_ "GenSigTimeoutTime" BU_SG_REL_ L_HKBD SG_ 37 L_ATCU_RRStHeatSwHInd 1500;
BA_ "Version" SG_ 37 L_ATCU_RRStHeatSwHInd "23.08.13";
BA_ "GenSigSendType" SG_ 37 L_ATCU_RRStHeatSwMInd 4;
BA_ "UserSigValidity" SG_ 37 L_ATCU_RRStHeatSwMInd 7;
BA_REL_ "GenSigTimeoutTime" BU_SG_REL_ L_2HKBD SG_ 37 L_ATCU_RRStHeatSwMInd 1500;
BA_REL_ "GenSigTimeoutTime" BU_SG_REL_ L_HKBD SG_ 37 L_ATCU_RRStHeatSwMInd 1500;
BA_ "Version" SG_ 37 L_ATCU_RRStHeatSwMInd "23.08.13";
BA_ "GenSigSendType" SG_ 37 L_ATCU_RRStHeatSwLInd 4;
BA_ "UserSigValidity" SG_ 37 L_ATCU_RRStHeatSwLInd 7;
BA_REL_ "GenSigTimeoutTime" BU_SG_REL_ L_2HKBD SG_ 37 L_ATCU_RRStHeatSwLInd 1500;
BA_REL_ "GenSigTimeoutTime" BU_SG_REL_ L_HKBD SG_ 37 L_ATCU_RRStHeatSwLInd 1500;
BA_ "Version" SG_ 37 L_ATCU_RRStHeatSwLInd "23.08.13";
BA_ "GenSigSendType" SG_ 37 L_ATCU_RRStVntSwHInd 4;
BA_ "UserSigValidity" SG_ 37 L_ATCU_RRStVntSwHInd 7;
BA_REL_ "GenSigTimeoutTime" BU_SG_REL_ L_2HKBD SG_ 37 L_ATCU_RRStVntSwHInd 1500;
BA_REL_ "GenSigTimeoutTime" BU_SG_REL_ L_HKBD SG_ 37 L_ATCU_RRStVntSwHInd 1500;
BA_ "Version" SG_ 37 L_ATCU_RRStVntSwHInd "23.08.13";
BA_ "GenSigSendType" SG_ 37 L_ATCU_RRStVntSwMInd 4;
BA_ "UserSigValidity" SG_ 37 L_ATCU_RRStVntSwMInd 7;
BA_REL_ "GenSigTimeoutTime" BU_SG_REL_ L_2HKBD SG_ 37 L_ATCU_RRStVntSwMInd 1500;
BA_REL_ "GenSigTimeoutTime" BU_SG_REL_ L_HKBD SG_ 37 L_ATCU_RRStVntSwMInd 1500;
BA_ "Version" SG_ 37 L_ATCU_RRStVntSwMInd "23.08.13";
BA_ "GenSigSendType" SG_ 37 L_ATCU_RRStVntSwLInd 4;
BA_ "UserSigValidity" SG_ 37 L_ATCU_RRStVntSwLInd 7;
BA_REL_ "GenSigTimeoutTime" BU_SG_REL_ L_2HKBD SG_ 37 L_ATCU_RRStVntSwLInd 1500;
BA_REL_ "GenSigTimeoutTime" BU_SG_REL_ L_HKBD SG_ 37 L_ATCU_RRStVntSwLInd 1500;
BA_ "Version" SG_ 37 L_ATCU_RRStVntSwLInd "23.08.13";
BA_ "GenSigSendType" SG_ 37 L_ATCU_RrMTCOpSta 4;
BA_ "UserSigValidity" SG_ 37 L_ATCU_RrMTCOpSta 7;
BA_REL_ "GenSigTimeoutTime" BU_SG_REL_ L_2HKBD SG_ 37 L_ATCU_RrMTCOpSta 1500;
BA_REL_ "GenSigTimeoutTime" BU_SG_REL_ L_HKBD SG_ 37 L_ATCU_RrMTCOpSta 1500;
BA_ "Version" SG_ 37 L_ATCU_RrMTCOpSta "23.08.13";
BA_ "GenSigSendType" SG_ 37 L_ATCU_RrMTCTempLvl 4;
BA_ "UserSigValidity" SG_ 37 L_ATCU_RrMTCTempLvl 7;
BA_REL_ "GenSigTimeoutTime" BU_SG_REL_ L_2HKBD SG_ 37 L_ATCU_RrMTCTempLvl 1500;
BA_REL_ "GenSigTimeoutTime" BU_SG_REL_ L_HKBD SG_ 37 L_ATCU_RrMTCTempLvl 1500;
BA_ "Version" SG_ 37 L_ATCU_RrMTCTempLvl "23.08.13";
BA_ "Description" SG_ 37 L_ATCU_RrPsModDis "ATCU_RearPassengerModeDisplay";
BA_ "GenSigSendType" SG_ 37 L_ATCU_RrPsModDis 4;
BA_ "UserSigValidity" SG_ 37 L_ATCU_RrPsModDis 7;
BA_REL_ "GenSigTimeoutTime" BU_SG_REL_ L_2HKBD SG_ 37 L_ATCU_RrPsModDis 1500;
BA_REL_ "GenSigTimeoutTime" BU_SG_REL_ L_EVNT SG_ 37 L_ATCU_RrPsModDis 1500;
BA_REL_ "GenSigTimeoutTime" BU_SG_REL_ L_HKBD SG_ 37 L_ATCU_RrPsModDis 1500;
BA_ "Version" SG_ 37 L_ATCU_RrPsModDis "24.05.08";
BA_ "GenSigSendType" SG_ 37 L_ATCU_RrLockDis 4;
BA_ "UserSigValidity" SG_ 37 L_ATCU_RrLockDis 7;
BA_REL_ "GenSigTimeoutTime" BU_SG_REL_ L_2HKBD SG_ 37 L_ATCU_RrLockDis 1500;
BA_REL_ "GenSigTimeoutTime" BU_SG_REL_ L_HKBD SG_ 37 L_ATCU_RrLockDis 1500;
BA_ "Version" SG_ 37 L_ATCU_RrLockDis "23.08.13";
BA_ "GenSigSendType" SG_ 37 L_ATCU_RrDrvAutoStep 4;
BA_ "UserSigValidity" SG_ 37 L_ATCU_RrDrvAutoStep 7;
BA_REL_ "GenSigTimeoutTime" BU_SG_REL_ L_2HKBD SG_ 37 L_ATCU_RrDrvAutoStep 1500;
BA_REL_ "GenSigTimeoutTime" BU_SG_REL_ L_HKBD SG_ 37 L_ATCU_RrDrvAutoStep 1500;
BA_ "Version" SG_ 37 L_ATCU_RrDrvAutoStep "23.08.13";
BA_ "GenMsgSendType" BO_ 40 0;
BA_ "GenSigSendType" SG_ 40 L_ATCU_PassAUTOStep 4;
BA_ "UserSigValidity" SG_ 40 L_ATCU_PassAUTOStep 7;
BA_REL_ "GenSigTimeoutTime" BU_SG_REL_ L_2HKBD SG_ 40 L_ATCU_PassAUTOStep 1500;
BA_REL_ "GenSigTimeoutTime" BU_SG_REL_ L_HKBD SG_ 40 L_ATCU_PassAUTOStep 1500;
BA_ "Version" SG_ 40 L_ATCU_PassAUTOStep "23.08.13";
BA_ "GenSigSendType" SG_ 40 L_ATCU_RrPassTempFDis 4;
BA_ "UserSigValidity" SG_ 40 L_ATCU_RrPassTempFDis 7;
BA_REL_ "GenSigTimeoutTime" BU_SG_REL_ L_2HKBD SG_ 40 L_ATCU_RrPassTempFDis 1500;
BA_REL_ "GenSigTimeoutTime" BU_SG_REL_ L_HKBD SG_ 40 L_ATCU_RrPassTempFDis 1500;
BA_ "Version" SG_ 40 L_ATCU_RrPassTempFDis "23.08.13";
BA_ "GenSigSendType" SG_ 40 L_ATCU_RrPassBlwDis 4;
BA_ "UserSigValidity" SG_ 40 L_ATCU_RrPassBlwDis 7;
BA_REL_ "GenSigTimeoutTime" BU_SG_REL_ L_2HKBD SG_ 40 L_ATCU_RrPassBlwDis 1500;
BA_REL_ "GenSigTimeoutTime" BU_SG_REL_ L_HKBD SG_ 40 L_ATCU_RrPassBlwDis 1500;
BA_ "Version" SG_ 40 L_ATCU_RrPassBlwDis "23.08.13";
BA_ "GenSigSendType" SG_ 40 L_ATCU_RrPassAUTODis 4;
BA_ "UserSigValidity" SG_ 40 L_ATCU_RrPassAUTODis 7;
BA_REL_ "GenSigTimeoutTime" BU_SG_REL_ L_2HKBD SG_ 40 L_ATCU_RrPassAUTODis 1500;
BA_REL_ "GenSigTimeoutTime" BU_SG_REL_ L_HKBD SG_ 40 L_ATCU_RrPassAUTODis 1500;
BA_ "Version" SG_ 40 L_ATCU_RrPassAUTODis "23.08.13";
BA_ "GenSigSendType" SG_ 40 L_ATCU_RrPassAUTOStep 4;
BA_ "UserSigValidity" SG_ 40 L_ATCU_RrPassAUTOStep 7;
BA_REL_ "GenSigTimeoutTime" BU_SG_REL_ L_2HKBD SG_ 40 L_ATCU_RrPassAUTOStep 1500;
BA_REL_ "GenSigTimeoutTime" BU_SG_REL_ L_HKBD SG_ 40 L_ATCU_RrPassAUTOStep 1500;
BA_ "Version" SG_ 40 L_ATCU_RrPassAUTOStep "23.08.13";
BA_ "Description" SG_ 40 L_ATCU_CampModeSta "Define the status of Camp Mode in EV";
BA_ "GenSigSendType" SG_ 40 L_ATCU_CampModeSta 4;
BA_ "UserSigValidity" SG_ 40 L_ATCU_CampModeSta 7;
BA_REL_ "GenSigTimeoutTime" BU_SG_REL_ L_2HKBD SG_ 40 L_ATCU_CampModeSta 1500;
BA_REL_ "GenSigTimeoutTime" BU_SG_REL_ L_3HKBD SG_ 40 L_ATCU_CampModeSta 1500;
BA_REL_ "GenSigTimeoutTime" BU_SG_REL_ L_EVNT SG_ 40 L_ATCU_CampModeSta 1500;
BA_REL_ "GenSigTimeoutTime" BU_SG_REL_ L_HKBD SG_ 40 L_ATCU_CampModeSta 1500;
BA_ "Version" SG_ 40 L_ATCU_CampModeSta "23.08.13";
BA_ "GenSigSendType" SG_ 40 L_ATCU_RrPassTempCDis 4;
BA_ "UserSigValidity" SG_ 40 L_ATCU_RrPassTempCDis 7;
BA_REL_ "GenSigTimeoutTime" BU_SG_REL_ L_2HKBD SG_ 40 L_ATCU_RrPassTempCDis 1500;
BA_REL_ "GenSigTimeoutTime" BU_SG_REL_ L_HKBD SG_ 40 L_ATCU_RrPassTempCDis 1500;
BA_ "Version" SG_ 40 L_ATCU_RrPassTempCDis "23.08.13";
BA_ "Description" SG_ 40 L_ATCU_UtilModeUsmSta "Timeout : Utility Mode OFF(Rest Mode OFF)";
BA_ "GenSigSendType" SG_ 40 L_ATCU_UtilModeUsmSta 4;
BA_ "UserSigValidity" SG_ 40 L_ATCU_UtilModeUsmSta 7;
BA_REL_ "GenSigTimeoutTime" BU_SG_REL_ L_2HKBD SG_ 40 L_ATCU_UtilModeUsmSta 1500;
BA_REL_ "GenSigTimeoutTime" BU_SG_REL_ L_3HKBD SG_ 40 L_ATCU_UtilModeUsmSta 1500;
BA_REL_ "GenSigTimeoutTime" BU_SG_REL_ L_EVNT SG_ 40 L_ATCU_UtilModeUsmSta 1500;
BA_REL_ "GenSigTimeoutTime" BU_SG_REL_ L_HKBD SG_ 40 L_ATCU_UtilModeUsmSta 1500;
BA_ "Version" SG_ 40 L_ATCU_UtilModeUsmSta "23.08.13";
BA_ "GenSigSendType" SG_ 40 L_ATCU_RrAcDis 4;
BA_ "UserSigValidity" SG_ 40 L_ATCU_RrAcDis 7;
BA_REL_ "GenSigTimeoutTime" BU_SG_REL_ L_2HKBD SG_ 40 L_ATCU_RrAcDis 1500;
BA_REL_ "GenSigTimeoutTime" BU_SG_REL_ L_3HKBD SG_ 40 L_ATCU_RrAcDis 1500;
BA_REL_ "GenSigTimeoutTime" BU_SG_REL_ L_HKBD SG_ 40 L_ATCU_RrAcDis 1500;
BA_ "Version" SG_ 40 L_ATCU_RrAcDis "24.02.01";
BA_ "GenSigSendType" SG_ 40 L_ATCU_3rdAcDis 4;
BA_ "UserSigValidity" SG_ 40 L_ATCU_3rdAcDis 7;
BA_REL_ "GenSigTimeoutTime" BU_SG_REL_ L_2HKBD SG_ 40 L_ATCU_3rdAcDis 1500;
BA_REL_ "GenSigTimeoutTime" BU_SG_REL_ L_3HKBD SG_ 40 L_ATCU_3rdAcDis 1500;
BA_REL_ "GenSigTimeoutTime" BU_SG_REL_ L_HKBD SG_ 40 L_ATCU_3rdAcDis 1500;
BA_ "Version" SG_ 40 L_ATCU_3rdAcDis "24.02.01";
BA_ "GenSigSendType" SG_ 40 L_ATCU_ValetModeSta 4;
BA_ "UserSigValidity" SG_ 40 L_ATCU_ValetModeSta 7;
BA_REL_ "GenSigTimeoutTime" BU_SG_REL_ L_EVNT SG_ 40 L_ATCU_ValetModeSta 1500;
BA_ "Version" SG_ 40 L_ATCU_ValetModeSta "25.05.04";
BA_ "GenSigSendType" SG_ 40 L_ATCU_FrSysOnOffDis 4;
BA_ "UserSigValidity" SG_ 40 L_ATCU_FrSysOnOffDis 7;
BA_REL_ "GenSigTimeoutTime" BU_SG_REL_ L_2HKBD SG_ 40 L_ATCU_FrSysOnOffDis 1500;
BA_REL_ "GenSigTimeoutTime" BU_SG_REL_ L_3HKBD SG_ 40 L_ATCU_FrSysOnOffDis 1500;
BA_REL_ "GenSigTimeoutTime" BU_SG_REL_ L_HKBD SG_ 40 L_ATCU_FrSysOnOffDis 1500;
BA_ "Version" SG_ 40 L_ATCU_FrSysOnOffDis "25.05.04";
BA_ "GenSigSendType" SG_ 40 L_ATCU_RrSysOnOffDis 4;
BA_ "UserSigValidity" SG_ 40 L_ATCU_RrSysOnOffDis 7;
BA_REL_ "GenSigTimeoutTime" BU_SG_REL_ L_2HKBD SG_ 40 L_ATCU_RrSysOnOffDis 1500;
BA_REL_ "GenSigTimeoutTime" BU_SG_REL_ L_3HKBD SG_ 40 L_ATCU_RrSysOnOffDis 1500;
BA_REL_ "GenSigTimeoutTime" BU_SG_REL_ L_HKBD SG_ 40 L_ATCU_RrSysOnOffDis 1500;
BA_ "Version" SG_ 40 L_ATCU_RrSysOnOffDis "25.05.04";
BA_ "GenSigSendType" SG_ 40 L_ATCU_3rdSysOnOffDis 4;
BA_ "UserSigValidity" SG_ 40 L_ATCU_3rdSysOnOffDis 7;
BA_REL_ "GenSigTimeoutTime" BU_SG_REL_ L_2HKBD SG_ 40 L_ATCU_3rdSysOnOffDis 1500;
BA_REL_ "GenSigTimeoutTime" BU_SG_REL_ L_3HKBD SG_ 40 L_ATCU_3rdSysOnOffDis 1500;
BA_REL_ "GenSigTimeoutTime" BU_SG_REL_ L_HKBD SG_ 40 L_ATCU_3rdSysOnOffDis 1500;
BA_ "Version" SG_ 40 L_ATCU_3rdSysOnOffDis "25.05.04";
BA_ "Description" SG_ 40 L_ATCU_RrCurtainPosition "Rear Curtain Position Information.";
BA_ "GenSigSendType" SG_ 40 L_ATCU_RrCurtainPosition 4;
BA_ "UserSigValidity" SG_ 40 L_ATCU_RrCurtainPosition 7;
BA_REL_ "GenSigTimeoutTime" BU_SG_REL_ L_2HKBD SG_ 40 L_ATCU_RrCurtainPosition 1500;
BA_REL_ "GenSigTimeoutTime" BU_SG_REL_ L_3HKBD SG_ 40 L_ATCU_RrCurtainPosition 1500;
BA_ "Version" SG_ 40 L_ATCU_RrCurtainPosition "25.08.06";
BA_ "Description" SG_ 40 L_ATCU_SafetyModeSta "L_ATCU_SafetyModeSta";
BA_ "GenSigSendType" SG_ 40 L_ATCU_SafetyModeSta 4;
BA_ "UserSigValidity" SG_ 40 L_ATCU_SafetyModeSta 7;
BA_REL_ "GenSigTimeoutTime" BU_SG_REL_ L_2HKBD SG_ 40 L_ATCU_SafetyModeSta 1500;
BA_REL_ "GenSigTimeoutTime" BU_SG_REL_ L_3HKBD SG_ 40 L_ATCU_SafetyModeSta 1500;
BA_REL_ "GenSigTimeoutTime" BU_SG_REL_ L_EVNT SG_ 40 L_ATCU_SafetyModeSta 1500;
BA_REL_ "GenSigTimeoutTime" BU_SG_REL_ L_HKBD SG_ 40 L_ATCU_SafetyModeSta 1500;
BA_ "Version" SG_ 40 L_ATCU_SafetyModeSta "25.08.06";
BA_ "GenMsgSendType" BO_ 41 0;
BA_ "GenMsgCycleTime" BO_ 41 20;
BA_ "GenMsgCycleTimeFast" BO_ 41 0;
BA_ "GenMsgNrOfRepetition" BO_ 41 0;
BA_ "GenMsgDelayTime" BO_ 41 0;
BA_ "Description" SG_ 41 L_ATCU_OutTempDispC "This signal indicates Outside temperature (¡É).

(Use for display only)";
BA_ "UserSigValidity" SG_ 41 L_ATCU_OutTempDispC 7;
BA_ "Version" SG_ 41 L_ATCU_OutTempDispC "23.08.13";
BA_ "UserSigValidity" SG_ 41 L_ATCU_DtntOutSta 7;
BA_ "Version" SG_ 41 L_ATCU_DtntOutSta "23.08.13";
BA_ "UserSigValidity" SG_ 41 L_ATCU_AutoBrightSta 7;
BA_ "Version" SG_ 41 L_ATCU_AutoBrightSta "23.08.13";
BA_ "UserSigValidity" SG_ 41 L_ATCU_DustSnrVal 7;
BA_ "Version" SG_ 41 L_ATCU_DustSnrVal "23.08.13";
BA_ "Description" SG_ 41 L_ATCU_NotMinModeBrightSta "This signal indicates the bright level of original state. Original state means the previous state of Camp Mode.";
BA_ "UserSigValidity" SG_ 41 L_ATCU_NotMinModeBrightSta 7;
BA_ "Version" SG_ 41 L_ATCU_NotMinModeBrightSta "23.08.13";
BA_ "Description" SG_ 41 L_ATCU_IAUPrfleVal "This signal Indicate the Current detected Profile ID by IAU.

This signal is a signal that forwards profile signals from IAU to L_ATCU, and L_ATCU then forwards them as is to L_EVNT.(NOTICE : MAIN CAN's original validity is B+)";
BA_ "UserSigValidity" SG_ 41 L_ATCU_IAUPrfleVal 7;
BA_ "Version" SG_ 41 L_ATCU_IAUPrfleVal "24.03.06";
BA_ "Description" SG_ 41 L_ATCU_AVNPrfleVal "This signal is a signal that forwards profile signals from HU to L_ATCU, and L_ATCU then forwards them as is to L_EVNT.(NOTICE : MAIN CAN's original validity is B+) 

Profile 3~Profile9 value is only used from Vehicle Architecture 2.0 (STD_DB_CAR_R2, SV 24.6~) vehicle models Vehicle Architecture 1.0 (STD_DB_CAR) vehicle models can us";
BA_ "GenSigStartValue" SG_ 41 L_ATCU_AVNPrfleVal 15;
BA_ "UserSigValidity" SG_ 41 L_ATCU_AVNPrfleVal 7;
BA_ "Version" SG_ 41 L_ATCU_AVNPrfleVal "24.03.06";
BA_ "Description" SG_ 41 L_ATCU_SchdldClimateSta "Operation of the air conditioning system(NOT ROUTING)";
BA_ "UserSigValidity" SG_ 41 L_ATCU_SchdldClimateSta 7;
BA_ "Version" SG_ 41 L_ATCU_SchdldClimateSta "24.08.08";
BA_ "Description" SG_ 41 L_ATCU_SchedRmtFcn_OpSta "Scheduled and Remote Function's operating status routing ATCU";
BA_ "UserSigValidity" SG_ 41 L_ATCU_SchedRmtFcn_OpSta 7;
BA_ "Version" SG_ 41 L_ATCU_SchedRmtFcn_OpSta "25.06.00";
BA_ "Description" SG_ 41 L_ATCU_AirconCtrReq "Main CAN routing ATCU(VCU_AirconCtrReq)";
BA_ "UserSigValidity" SG_ 41 L_ATCU_AirconCtrReq 7;
BA_ "Version" SG_ 41 L_ATCU_AirconCtrReq "25.06.00";
BA_ "Description" SG_ 41 L_ATCU_OutTempDispF "This signal indicates Outside Temperature (¢µ)

(Use for display only)";
BA_ "UserSigValidity" SG_ 41 L_ATCU_OutTempDispF 7;
BA_ "Version" SG_ 41 L_ATCU_OutTempDispF "23.08.13";
BA_ "GenMsgSendType" BO_ 48 0;
BA_ "GenMsgCycleTime" BO_ 48 500;
BA_ "GenSigSendType" SG_ 48 L_ATCU_SW_Ver1 4;
BA_ "UserSigValidity" SG_ 48 L_ATCU_SW_Ver1 7;
BA_REL_ "GenSigTimeoutTime" BU_SG_REL_ L_HKBD SG_ 48 L_ATCU_SW_Ver1 5000;
BA_ "Version" SG_ 48 L_ATCU_SW_Ver1 "23.08.13";
BA_ "GenSigSendType" SG_ 48 L_ATCU_SW_Ver3 4;
BA_ "UserSigValidity" SG_ 48 L_ATCU_SW_Ver3 7;
BA_REL_ "GenSigTimeoutTime" BU_SG_REL_ L_HKBD SG_ 48 L_ATCU_SW_Ver3 5000;
BA_ "Version" SG_ 48 L_ATCU_SW_Ver3 "23.08.13";
BA_ "GenSigSendType" SG_ 48 L_ATCU_SW_Ver4 4;
BA_ "UserSigValidity" SG_ 48 L_ATCU_SW_Ver4 7;
BA_REL_ "GenSigTimeoutTime" BU_SG_REL_ L_HKBD SG_ 48 L_ATCU_SW_Ver4 5000;
BA_ "Version" SG_ 48 L_ATCU_SW_Ver4 "23.08.13";
BA_ "GenSigSendType" SG_ 48 L_ATCU_SW_Ver5 4;
BA_ "UserSigValidity" SG_ 48 L_ATCU_SW_Ver5 7;
BA_REL_ "GenSigTimeoutTime" BU_SG_REL_ L_HKBD SG_ 48 L_ATCU_SW_Ver5 5000;
BA_ "Version" SG_ 48 L_ATCU_SW_Ver5 "23.08.13";
BA_ "GenSigSendType" SG_ 48 L_ATCU_SW_Ver2 4;
BA_ "UserSigValidity" SG_ 48 L_ATCU_SW_Ver2 7;
BA_REL_ "GenSigTimeoutTime" BU_SG_REL_ L_HKBD SG_ 48 L_ATCU_SW_Ver2 5000;
BA_ "Version" SG_ 48 L_ATCU_SW_Ver2 "23.08.13";
BA_ "GenMsgSendType" BO_ 49 0;
BA_ "Description" SG_ 49 L_ATCU_ResetPreWrngForOthers "This is a PDC routing signal for reset preparing sideeffect of reset";
BA_ "GenSigSendType" SG_ 49 L_ATCU_ResetPreWrngForOthers 4;
BA_ "UserSigValidity" SG_ 49 L_ATCU_ResetPreWrngForOthers 0;
BA_REL_ "GenSigTimeoutTime" BU_SG_REL_ L_2HKBD SG_ 49 L_ATCU_ResetPreWrngForOthers 1500;
BA_REL_ "GenSigTimeoutTime" BU_SG_REL_ L_3HKBD SG_ 49 L_ATCU_ResetPreWrngForOthers 1500;
BA_REL_ "GenSigTimeoutTime" BU_SG_REL_ L_EVNT SG_ 49 L_ATCU_ResetPreWrngForOthers 1500;
BA_REL_ "GenSigTimeoutTime" BU_SG_REL_ L_HKBD SG_ 49 L_ATCU_ResetPreWrngForOthers 1500;
BA_REL_ "GenSigTimeoutTime" BU_SG_REL_ L_PCM SG_ 49 L_ATCU_ResetPreWrngForOthers 1500;
BA_ "Version" SG_ 49 L_ATCU_ResetPreWrngForOthers "24.07.02";
BA_ "Description" SG_ 49 L_ATCU_ResetReqForOthers "This is a PDC routing signal for SW reset except for Gateway";
BA_ "GenSigSendType" SG_ 49 L_ATCU_ResetReqForOthers 4;
BA_ "UserSigValidity" SG_ 49 L_ATCU_ResetReqForOthers 0;
BA_REL_ "GenSigTimeoutTime" BU_SG_REL_ L_2HKBD SG_ 49 L_ATCU_ResetReqForOthers 1500;
BA_REL_ "GenSigTimeoutTime" BU_SG_REL_ L_3HKBD SG_ 49 L_ATCU_ResetReqForOthers 1500;
BA_REL_ "GenSigTimeoutTime" BU_SG_REL_ L_EVNT SG_ 49 L_ATCU_ResetReqForOthers 1500;
BA_REL_ "GenSigTimeoutTime" BU_SG_REL_ L_HKBD SG_ 49 L_ATCU_ResetReqForOthers 1500;
BA_REL_ "GenSigTimeoutTime" BU_SG_REL_ L_PCM SG_ 49 L_ATCU_ResetReqForOthers 1500;
BA_ "Version" SG_ 49 L_ATCU_ResetReqForOthers "24.07.02";
BA_ "GenMsgSendType" BO_ 290 0;
BA_ "GenMsgCycleTime" BO_ 290 1000;
BA_ "GenMsgCycleTimeFast" BO_ 290 0;
BA_ "GenMsgNrOfRepetition" BO_ 290 0;
BA_ "Description" SG_ 290 L_ATCU_HU_FrDrEVntSideBdryUp_X "Electric Vent FRT Dr Side Electric Vent Upper Range X Coordinate";
BA_ "UserSigValidity" SG_ 290 L_ATCU_HU_FrDrEVntSideBdryUp_X 7;
BA_REL_ "GenSigTimeoutTime" BU_SG_REL_ L_EVNT SG_ 290 L_ATCU_HU_FrDrEVntSideBdryUp_X 5000;
BA_ "Version" SG_ 290 L_ATCU_HU_FrDrEVntSideBdryUp_X "24.05.11";
BA_ "Description" SG_ 290 L_ATCU_HU_FrDrEVntSideBdryLo_X "Electric Vent FRT Dr Side Electric Vent Lower Range X Coordinate";
BA_ "UserSigValidity" SG_ 290 L_ATCU_HU_FrDrEVntSideBdryLo_X 7;
BA_REL_ "GenSigTimeoutTime" BU_SG_REL_ L_EVNT SG_ 290 L_ATCU_HU_FrDrEVntSideBdryLo_X 5000;
BA_ "Version" SG_ 290 L_ATCU_HU_FrDrEVntSideBdryLo_X "24.05.11";
BA_ "Description" SG_ 290 L_ATCU_HU_FrDrEVntSideBdryLo_Y "Electric Vent FRT Dr Side Electric Vent Lower Range Y Coordinate";
BA_ "UserSigValidity" SG_ 290 L_ATCU_HU_FrDrEVntSideBdryLo_Y 7;
BA_REL_ "GenSigTimeoutTime" BU_SG_REL_ L_EVNT SG_ 290 L_ATCU_HU_FrDrEVntSideBdryLo_Y 5000;
BA_ "Version" SG_ 290 L_ATCU_HU_FrDrEVntSideBdryLo_Y "24.05.11";
BA_ "Description" SG_ 290 L_ATCU_HU_FrDrEVntCtrBdryUp_X "Electric Vent FRT Dr Center Electric Vent Upper Range X Coordinate";
BA_ "UserSigValidity" SG_ 290 L_ATCU_HU_FrDrEVntCtrBdryUp_X 7;
BA_REL_ "GenSigTimeoutTime" BU_SG_REL_ L_EVNT SG_ 290 L_ATCU_HU_FrDrEVntCtrBdryUp_X 5000;
BA_ "Version" SG_ 290 L_ATCU_HU_FrDrEVntCtrBdryUp_X "24.05.11";
BA_ "Description" SG_ 290 L_ATCU_HU_FrDrEVntCtrBdryUp_Y "Electric Vent FRT Dr Center Electric Vent Upper Range Y Coordinate";
BA_ "UserSigValidity" SG_ 290 L_ATCU_HU_FrDrEVntCtrBdryUp_Y 7;
BA_REL_ "GenSigTimeoutTime" BU_SG_REL_ L_EVNT SG_ 290 L_ATCU_HU_FrDrEVntCtrBdryUp_Y 5000;
BA_ "Version" SG_ 290 L_ATCU_HU_FrDrEVntCtrBdryUp_Y "24.05.11";
BA_ "Description" SG_ 290 L_ATCU_HU_FrDrEVntCtrBdryLo_X "Electric Vent FRT Dr Center Electric Vent Lower Range X Coordinate";
BA_ "UserSigValidity" SG_ 290 L_ATCU_HU_FrDrEVntCtrBdryLo_X 7;
BA_REL_ "GenSigTimeoutTime" BU_SG_REL_ L_EVNT SG_ 290 L_ATCU_HU_FrDrEVntCtrBdryLo_X 5000;
BA_ "Version" SG_ 290 L_ATCU_HU_FrDrEVntCtrBdryLo_X "24.05.11";
BA_ "Description" SG_ 290 L_ATCU_HU_FrDrEVntCtrBdryLo_Y "Electric Vent FRT Dr Center Electric Vent Lower Range Y Coordinate";
BA_ "UserSigValidity" SG_ 290 L_ATCU_HU_FrDrEVntCtrBdryLo_Y 7;
BA_REL_ "GenSigTimeoutTime" BU_SG_REL_ L_EVNT SG_ 290 L_ATCU_HU_FrDrEVntCtrBdryLo_Y 5000;
BA_ "Version" SG_ 290 L_ATCU_HU_FrDrEVntCtrBdryLo_Y "24.05.11";
BA_ "Description" SG_ 290 L_ATCU_HU_FrDrEVntSideBdryUp_Y "Electric Vent FRT Dr Side Electric Vent Upper Range Y Coordinate";
BA_ "UserSigValidity" SG_ 290 L_ATCU_HU_FrDrEVntSideBdryUp_Y 7;
BA_REL_ "GenSigTimeoutTime" BU_SG_REL_ L_EVNT SG_ 290 L_ATCU_HU_FrDrEVntSideBdryUp_Y 5000;
BA_ "Version" SG_ 290 L_ATCU_HU_FrDrEVntSideBdryUp_Y "24.05.11";
BA_ "GenMsgSendType" BO_ 291 0;
BA_ "GenMsgCycleTime" BO_ 291 1000;
BA_ "GenMsgCycleTimeFast" BO_ 291 0;
BA_ "GenMsgNrOfRepetition" BO_ 291 0;
BA_ "Description" SG_ 291 L_ATCU_HU_FrPsEVntSideBdryUp_X "Electric Vent FRT Ps Side Electric Vent Upper Range X Coordinate";
BA_ "UserSigValidity" SG_ 291 L_ATCU_HU_FrPsEVntSideBdryUp_X 7;
BA_REL_ "GenSigTimeoutTime" BU_SG_REL_ L_EVNT SG_ 291 L_ATCU_HU_FrPsEVntSideBdryUp_X 5000;
BA_ "Version" SG_ 291 L_ATCU_HU_FrPsEVntSideBdryUp_X "24.05.11";
BA_ "Description" SG_ 291 L_ATCU_HU_FrPsEVntSideBdryLo_X "Electric Vent FRT Ps Side Electric Vent Lower Range X Coordinate";
BA_ "UserSigValidity" SG_ 291 L_ATCU_HU_FrPsEVntSideBdryLo_X 7;
BA_REL_ "GenSigTimeoutTime" BU_SG_REL_ L_EVNT SG_ 291 L_ATCU_HU_FrPsEVntSideBdryLo_X 5000;
BA_ "Version" SG_ 291 L_ATCU_HU_FrPsEVntSideBdryLo_X "24.05.11";
BA_ "Description" SG_ 291 L_ATCU_HU_FrPsEVntSideBdryLo_Y "Electric Vent FRT Ps Side Electric Vent Lower Range Y Coordinate";
BA_ "UserSigValidity" SG_ 291 L_ATCU_HU_FrPsEVntSideBdryLo_Y 7;
BA_REL_ "GenSigTimeoutTime" BU_SG_REL_ L_EVNT SG_ 291 L_ATCU_HU_FrPsEVntSideBdryLo_Y 5000;
BA_ "Version" SG_ 291 L_ATCU_HU_FrPsEVntSideBdryLo_Y "24.05.11";
BA_ "Description" SG_ 291 L_ATCU_HU_FrPsEVntCtrBdryUp_X "Electric Vent FRT Ps Center Electric Vent Upper Range X Coordinate";
BA_ "UserSigValidity" SG_ 291 L_ATCU_HU_FrPsEVntCtrBdryUp_X 7;
BA_REL_ "GenSigTimeoutTime" BU_SG_REL_ L_EVNT SG_ 291 L_ATCU_HU_FrPsEVntCtrBdryUp_X 5000;
BA_ "Version" SG_ 291 L_ATCU_HU_FrPsEVntCtrBdryUp_X "24.05.11";
BA_ "Description" SG_ 291 L_ATCU_HU_FrPsEVntCtrBdryUp_Y "Electric Vent FRT Ps Center Electric Vent Upper Range Y Coordinate";
BA_ "UserSigValidity" SG_ 291 L_ATCU_HU_FrPsEVntCtrBdryUp_Y 7;
BA_REL_ "GenSigTimeoutTime" BU_SG_REL_ L_EVNT SG_ 291 L_ATCU_HU_FrPsEVntCtrBdryUp_Y 5000;
BA_ "Version" SG_ 291 L_ATCU_HU_FrPsEVntCtrBdryUp_Y "24.05.11";
BA_ "Description" SG_ 291 L_ATCU_HU_FrPsEVntCtrBdryLo_X "Electric Vent FRT Ps Center Electric Vent Lower Range X Coordinate";
BA_ "UserSigValidity" SG_ 291 L_ATCU_HU_FrPsEVntCtrBdryLo_X 7;
BA_REL_ "GenSigTimeoutTime" BU_SG_REL_ L_EVNT SG_ 291 L_ATCU_HU_FrPsEVntCtrBdryLo_X 5000;
BA_ "Version" SG_ 291 L_ATCU_HU_FrPsEVntCtrBdryLo_X "24.05.11";
BA_ "Description" SG_ 291 L_ATCU_HU_FrPsEVntCtrBdryLo_Y "Electric Vent FRT Ps Center Electric Vent Lower Range Y Coordinate";
BA_ "UserSigValidity" SG_ 291 L_ATCU_HU_FrPsEVntCtrBdryLo_Y 7;
BA_REL_ "GenSigTimeoutTime" BU_SG_REL_ L_EVNT SG_ 291 L_ATCU_HU_FrPsEVntCtrBdryLo_Y 5000;
BA_ "Version" SG_ 291 L_ATCU_HU_FrPsEVntCtrBdryLo_Y "24.05.11";
BA_ "Description" SG_ 291 L_ATCU_HU_FrPsEVntSideBdryUp_Y "Electric Vent FRT Ps Side Electric Vent Upper Range Y Coordinate";
BA_ "UserSigValidity" SG_ 291 L_ATCU_HU_FrPsEVntSideBdryUp_Y 7;
BA_REL_ "GenSigTimeoutTime" BU_SG_REL_ L_EVNT SG_ 291 L_ATCU_HU_FrPsEVntSideBdryUp_Y 5000;
BA_ "Version" SG_ 291 L_ATCU_HU_FrPsEVntSideBdryUp_Y "24.05.11";
BA_ "GenMsgSendType" BO_ 292 0;
BA_ "GenMsgCycleTime" BO_ 292 1000;
BA_ "GenMsgCycleTimeFast" BO_ 292 0;
BA_ "GenMsgNrOfRepetition" BO_ 292 0;
BA_ "Description" SG_ 292 L_ATCU_HU_RrDrEVntConsBdryUp_X "Electric Vent RR Dr Console Electric Vent Upper Range X Coordinate";
BA_ "UserSigValidity" SG_ 292 L_ATCU_HU_RrDrEVntConsBdryUp_X 7;
BA_REL_ "GenSigTimeoutTime" BU_SG_REL_ L_EVNT SG_ 292 L_ATCU_HU_RrDrEVntConsBdryUp_X 5000;
BA_ "Version" SG_ 292 L_ATCU_HU_RrDrEVntConsBdryUp_X "24.05.11";
BA_ "Description" SG_ 292 L_ATCU_HU_RrDrEVntConsBdryLo_X "Electric Vent RR Dr Console Electric Vent Lower Range X Coordinate";
BA_ "UserSigValidity" SG_ 292 L_ATCU_HU_RrDrEVntConsBdryLo_X 7;
BA_REL_ "GenSigTimeoutTime" BU_SG_REL_ L_EVNT SG_ 292 L_ATCU_HU_RrDrEVntConsBdryLo_X 5000;
BA_ "Version" SG_ 292 L_ATCU_HU_RrDrEVntConsBdryLo_X "24.05.11";
BA_ "Description" SG_ 292 L_ATCU_HU_RrDrEVntConsBdryLo_Y "Electric Vent RR Dr Console Electric Vent Lower Range Y Coordinate";
BA_ "UserSigValidity" SG_ 292 L_ATCU_HU_RrDrEVntConsBdryLo_Y 7;
BA_REL_ "GenSigTimeoutTime" BU_SG_REL_ L_EVNT SG_ 292 L_ATCU_HU_RrDrEVntConsBdryLo_Y 5000;
BA_ "Version" SG_ 292 L_ATCU_HU_RrDrEVntConsBdryLo_Y "24.05.11";
BA_ "Description" SG_ 292 L_ATCU_HU_RrPsEVntConsBdryUp_X "Electric Vent RR Ps Console Electric Vent Upper Range X Coordinate";
BA_ "UserSigValidity" SG_ 292 L_ATCU_HU_RrPsEVntConsBdryUp_X 7;
BA_REL_ "GenSigTimeoutTime" BU_SG_REL_ L_EVNT SG_ 292 L_ATCU_HU_RrPsEVntConsBdryUp_X 5000;
BA_ "Version" SG_ 292 L_ATCU_HU_RrPsEVntConsBdryUp_X "24.05.11";
BA_ "Description" SG_ 292 L_ATCU_HU_RrPsEVntConsBdryUp_Y "Electric Vent RR Ps Console Electric Vent Upper Range Y Coordinate";
BA_ "UserSigValidity" SG_ 292 L_ATCU_HU_RrPsEVntConsBdryUp_Y 7;
BA_REL_ "GenSigTimeoutTime" BU_SG_REL_ L_EVNT SG_ 292 L_ATCU_HU_RrPsEVntConsBdryUp_Y 5000;
BA_ "Version" SG_ 292 L_ATCU_HU_RrPsEVntConsBdryUp_Y "24.05.11";
BA_ "Description" SG_ 292 L_ATCU_HU_RrPsEVntConsBdryLo_X "Electric Vent RR Ps Console Electric Vent Lower Range X Coordinate";
BA_ "UserSigValidity" SG_ 292 L_ATCU_HU_RrPsEVntConsBdryLo_X 7;
BA_REL_ "GenSigTimeoutTime" BU_SG_REL_ L_EVNT SG_ 292 L_ATCU_HU_RrPsEVntConsBdryLo_X 5000;
BA_ "Version" SG_ 292 L_ATCU_HU_RrPsEVntConsBdryLo_X "24.05.11";
BA_ "Description" SG_ 292 L_ATCU_HU_RrPsEVntConsBdryLo_Y "Electric Vent RR Ps Console Electric Vent Lower Range Y Coordinate";
BA_ "UserSigValidity" SG_ 292 L_ATCU_HU_RrPsEVntConsBdryLo_Y 7;
BA_REL_ "GenSigTimeoutTime" BU_SG_REL_ L_EVNT SG_ 292 L_ATCU_HU_RrPsEVntConsBdryLo_Y 5000;
BA_ "Version" SG_ 292 L_ATCU_HU_RrPsEVntConsBdryLo_Y "24.05.11";
BA_ "Description" SG_ 292 L_ATCU_HU_RrDrEVntConsBdryUp_Y "Electric Vent RR Dr Console Electric Vent Upper Range Y Coordinate";
BA_ "UserSigValidity" SG_ 292 L_ATCU_HU_RrDrEVntConsBdryUp_Y 7;
BA_REL_ "GenSigTimeoutTime" BU_SG_REL_ L_EVNT SG_ 292 L_ATCU_HU_RrDrEVntConsBdryUp_Y 5000;
BA_ "Version" SG_ 292 L_ATCU_HU_RrDrEVntConsBdryUp_Y "24.05.11";
BA_ "GenMsgCycleTime" BO_ 293 0;
BA_ "Description" SG_ 293 L_ATCU_CTS_FrDrEVntSidePt_X "Electric Vent FRT Dr Side Vent Select Point X Coordinate";
BA_ "GenSigSendType" SG_ 293 L_ATCU_CTS_FrDrEVntSidePt_X 4;
BA_ "UserSigValidity" SG_ 293 L_ATCU_CTS_FrDrEVntSidePt_X 7;
BA_REL_ "GenSigTimeoutTime" BU_SG_REL_ L_EVNT SG_ 293 L_ATCU_CTS_FrDrEVntSidePt_X 0;
BA_ "Version" SG_ 293 L_ATCU_CTS_FrDrEVntSidePt_X "24.05.11";
BA_ "Description" SG_ 293 L_ATCU_CTS_FrDrEVntSidePt_Y "Electric Vent FRT Dr Side Vent Select Point Y Coordinate";
BA_ "GenSigSendType" SG_ 293 L_ATCU_CTS_FrDrEVntSidePt_Y 4;
BA_ "UserSigValidity" SG_ 293 L_ATCU_CTS_FrDrEVntSidePt_Y 7;
BA_REL_ "GenSigTimeoutTime" BU_SG_REL_ L_EVNT SG_ 293 L_ATCU_CTS_FrDrEVntSidePt_Y 0;
BA_ "Version" SG_ 293 L_ATCU_CTS_FrDrEVntSidePt_Y "24.05.11";
BA_ "Description" SG_ 293 L_ATCU_CTS_FrDrEVntCtrPt_X "Electric Vent FRT Dr Center Vent Select Point X Coordinate";
BA_ "GenSigSendType" SG_ 293 L_ATCU_CTS_FrDrEVntCtrPt_X 4;
BA_ "UserSigValidity" SG_ 293 L_ATCU_CTS_FrDrEVntCtrPt_X 7;
BA_REL_ "GenSigTimeoutTime" BU_SG_REL_ L_EVNT SG_ 293 L_ATCU_CTS_FrDrEVntCtrPt_X 0;
BA_ "Version" SG_ 293 L_ATCU_CTS_FrDrEVntCtrPt_X "24.05.11";
BA_ "Description" SG_ 293 L_ATCU_CTS_FrDrEVntCtrPt_Y "Electric Vent FRT Dr Center Vent Select Point Y Coordinate";
BA_ "GenSigSendType" SG_ 293 L_ATCU_CTS_FrDrEVntCtrPt_Y 4;
BA_ "UserSigValidity" SG_ 293 L_ATCU_CTS_FrDrEVntCtrPt_Y 7;
BA_REL_ "GenSigTimeoutTime" BU_SG_REL_ L_EVNT SG_ 293 L_ATCU_CTS_FrDrEVntCtrPt_Y 0;
BA_ "Version" SG_ 293 L_ATCU_CTS_FrDrEVntCtrPt_Y "24.05.11";
BA_ "GenMsgCycleTime" BO_ 294 0;
BA_ "Description" SG_ 294 L_ATCU_CTS_FrPsEVntSidePt_X "Electric Vent FRT Ps Side Vent Select Point X Coordinate";
BA_ "GenSigSendType" SG_ 294 L_ATCU_CTS_FrPsEVntSidePt_X 4;
BA_ "UserSigValidity" SG_ 294 L_ATCU_CTS_FrPsEVntSidePt_X 7;
BA_REL_ "GenSigTimeoutTime" BU_SG_REL_ L_EVNT SG_ 294 L_ATCU_CTS_FrPsEVntSidePt_X 0;
BA_ "Version" SG_ 294 L_ATCU_CTS_FrPsEVntSidePt_X "24.05.11";
BA_ "Description" SG_ 294 L_ATCU_CTS_FrPsEVntSidePt_Y "Electric Vent FRT Ps Side Vent Select Point Y Coordinate";
BA_ "GenSigSendType" SG_ 294 L_ATCU_CTS_FrPsEVntSidePt_Y 4;
BA_ "UserSigValidity" SG_ 294 L_ATCU_CTS_FrPsEVntSidePt_Y 7;
BA_REL_ "GenSigTimeoutTime" BU_SG_REL_ L_EVNT SG_ 294 L_ATCU_CTS_FrPsEVntSidePt_Y 0;
BA_ "Version" SG_ 294 L_ATCU_CTS_FrPsEVntSidePt_Y "24.05.11";
BA_ "Description" SG_ 294 L_ATCU_CTS_FrPsEVntCtrPt_X "Electric Vent FRT Ps Center Vent Select Point X Coordinate";
BA_ "GenSigSendType" SG_ 294 L_ATCU_CTS_FrPsEVntCtrPt_X 4;
BA_ "UserSigValidity" SG_ 294 L_ATCU_CTS_FrPsEVntCtrPt_X 7;
BA_REL_ "GenSigTimeoutTime" BU_SG_REL_ L_EVNT SG_ 294 L_ATCU_CTS_FrPsEVntCtrPt_X 0;
BA_ "Version" SG_ 294 L_ATCU_CTS_FrPsEVntCtrPt_X "24.05.11";
BA_ "Description" SG_ 294 L_ATCU_CTS_FrPsEVntCtrPt_Y "Electric Vent FRT Ps Center Vent Select Point Y Coordinate";
BA_ "GenSigSendType" SG_ 294 L_ATCU_CTS_FrPsEVntCtrPt_Y 4;
BA_ "UserSigValidity" SG_ 294 L_ATCU_CTS_FrPsEVntCtrPt_Y 7;
BA_REL_ "GenSigTimeoutTime" BU_SG_REL_ L_EVNT SG_ 294 L_ATCU_CTS_FrPsEVntCtrPt_Y 0;
BA_ "Version" SG_ 294 L_ATCU_CTS_FrPsEVntCtrPt_Y "24.05.11";
BA_ "GenMsgCycleTime" BO_ 295 0;
BA_ "Description" SG_ 295 L_ATCU_CTS_RrDrEVntConsPt_X "Electric Vent RR Dr Console Vent Select Point X Coordinate";
BA_ "GenSigSendType" SG_ 295 L_ATCU_CTS_RrDrEVntConsPt_X 4;
BA_ "UserSigValidity" SG_ 295 L_ATCU_CTS_RrDrEVntConsPt_X 7;
BA_REL_ "GenSigTimeoutTime" BU_SG_REL_ L_EVNT SG_ 295 L_ATCU_CTS_RrDrEVntConsPt_X 0;
BA_ "Version" SG_ 295 L_ATCU_CTS_RrDrEVntConsPt_X "24.05.11";
BA_ "Description" SG_ 295 L_ATCU_CTS_RrDrEVntConsPt_Y "Electric Vent RR Dr Console Vent Select Point Y Coordinate";
BA_ "GenSigSendType" SG_ 295 L_ATCU_CTS_RrDrEVntConsPt_Y 4;
BA_ "UserSigValidity" SG_ 295 L_ATCU_CTS_RrDrEVntConsPt_Y 7;
BA_REL_ "GenSigTimeoutTime" BU_SG_REL_ L_EVNT SG_ 295 L_ATCU_CTS_RrDrEVntConsPt_Y 0;
BA_ "Version" SG_ 295 L_ATCU_CTS_RrDrEVntConsPt_Y "24.05.11";
BA_ "Description" SG_ 295 L_ATCU_CTS_RrPsEVntConsPt_X "Electric Vent RR Ps Console Vent Select Point X Coordinate";
BA_ "GenSigSendType" SG_ 295 L_ATCU_CTS_RrPsEVntConsPt_X 4;
BA_ "UserSigValidity" SG_ 295 L_ATCU_CTS_RrPsEVntConsPt_X 7;
BA_REL_ "GenSigTimeoutTime" BU_SG_REL_ L_EVNT SG_ 295 L_ATCU_CTS_RrPsEVntConsPt_X 0;
BA_ "Version" SG_ 295 L_ATCU_CTS_RrPsEVntConsPt_X "24.05.11";
BA_ "Description" SG_ 295 L_ATCU_CTS_RrPsEVntConsPt_Y "Electric Vent RR Ps Console Vent Select Point Y Coordinate";
BA_ "GenSigSendType" SG_ 295 L_ATCU_CTS_RrPsEVntConsPt_Y 4;
BA_ "UserSigValidity" SG_ 295 L_ATCU_CTS_RrPsEVntConsPt_Y 7;
BA_REL_ "GenSigTimeoutTime" BU_SG_REL_ L_EVNT SG_ 295 L_ATCU_CTS_RrPsEVntConsPt_Y 0;
BA_ "Version" SG_ 295 L_ATCU_CTS_RrPsEVntConsPt_Y "24.05.11";
BA_ "Description" SG_ 295 L_ATCU_CTS_RrDrEVntModeSet "Electric Vent Mode_Rr Dr";
BA_ "GenSigSendType" SG_ 295 L_ATCU_CTS_RrDrEVntModeSet 4;
BA_ "UserSigValidity" SG_ 295 L_ATCU_CTS_RrDrEVntModeSet 7;
BA_REL_ "GenSigTimeoutTime" BU_SG_REL_ L_EVNT SG_ 295 L_ATCU_CTS_RrDrEVntModeSet 0;
BA_ "Version" SG_ 295 L_ATCU_CTS_RrDrEVntModeSet "25.04.02";
BA_ "Description" SG_ 295 L_ATCU_CTS_RrPsEVntModeSet "Electric Vent Mode_Rr Ps";
BA_ "GenSigSendType" SG_ 295 L_ATCU_CTS_RrPsEVntModeSet 4;
BA_ "UserSigValidity" SG_ 295 L_ATCU_CTS_RrPsEVntModeSet 7;
BA_REL_ "GenSigTimeoutTime" BU_SG_REL_ L_EVNT SG_ 295 L_ATCU_CTS_RrPsEVntModeSet 0;
BA_ "Version" SG_ 295 L_ATCU_CTS_RrPsEVntModeSet "25.04.02";
BA_ "Description" SG_ 295 L_ATCU_CTS_RrDrEVntConsOpnCls "Electric Vent RR Dr Console Vent Open/Close Signal";
BA_ "GenSigSendType" SG_ 295 L_ATCU_CTS_RrDrEVntConsOpnCls 4;
BA_ "UserSigValidity" SG_ 295 L_ATCU_CTS_RrDrEVntConsOpnCls 7;
BA_REL_ "GenSigTimeoutTime" BU_SG_REL_ L_EVNT SG_ 295 L_ATCU_CTS_RrDrEVntConsOpnCls 0;
BA_ "Version" SG_ 295 L_ATCU_CTS_RrDrEVntConsOpnCls "24.05.11";
BA_ "Description" SG_ 295 L_ATCU_CTS_RrPsEVntConsOpnCls "Electric Vent RR Ps Console Vent Open/Close Signal";
BA_ "GenSigSendType" SG_ 295 L_ATCU_CTS_RrPsEVntConsOpnCls 4;
BA_ "UserSigValidity" SG_ 295 L_ATCU_CTS_RrPsEVntConsOpnCls 7;
BA_REL_ "GenSigTimeoutTime" BU_SG_REL_ L_EVNT SG_ 295 L_ATCU_CTS_RrPsEVntConsOpnCls 0;
BA_ "Version" SG_ 295 L_ATCU_CTS_RrPsEVntConsOpnCls "24.05.11";
BA_ "GenMsgSendType" BO_ 296 0;
BA_ "GenMsgCycleTime" BO_ 296 1000;
BA_ "GenMsgCycleTimeFast" BO_ 296 0;
BA_ "GenMsgNrOfRepetition" BO_ 296 0;
BA_ "Description" SG_ 296 L_ATCU_CTS_FrDrEVntSideBdryUp_X "Electric Vent FRT Dr Side Electric Vent Upper Range X Coordinate";
BA_ "UserSigValidity" SG_ 296 L_ATCU_CTS_FrDrEVntSideBdryUp_X 7;
BA_REL_ "GenSigTimeoutTime" BU_SG_REL_ L_EVNT SG_ 296 L_ATCU_CTS_FrDrEVntSideBdryUp_X 5000;
BA_ "Version" SG_ 296 L_ATCU_CTS_FrDrEVntSideBdryUp_X "24.05.11";
BA_ "Description" SG_ 296 L_ATCU_CTS_FrDrEVntSideBdryLo_X "Electric Vent FRT Dr Side Electric Vent Lower Range X Coordinate";
BA_ "UserSigValidity" SG_ 296 L_ATCU_CTS_FrDrEVntSideBdryLo_X 7;
BA_REL_ "GenSigTimeoutTime" BU_SG_REL_ L_EVNT SG_ 296 L_ATCU_CTS_FrDrEVntSideBdryLo_X 5000;
BA_ "Version" SG_ 296 L_ATCU_CTS_FrDrEVntSideBdryLo_X "24.05.11";
BA_ "Description" SG_ 296 L_ATCU_CTS_FrDrEVntSideBdryLo_Y "Electric Vent FRT Dr Side Electric Vent Lower Range Y Coordinate";
BA_ "UserSigValidity" SG_ 296 L_ATCU_CTS_FrDrEVntSideBdryLo_Y 7;
BA_REL_ "GenSigTimeoutTime" BU_SG_REL_ L_EVNT SG_ 296 L_ATCU_CTS_FrDrEVntSideBdryLo_Y 5000;
BA_ "Version" SG_ 296 L_ATCU_CTS_FrDrEVntSideBdryLo_Y "24.05.11";
BA_ "Description" SG_ 296 L_ATCU_CTS_FrDrEVntCtrBdryUp_X "Electric Vent FRT Dr Center Electric Vent Upper Range X Coordinate";
BA_ "UserSigValidity" SG_ 296 L_ATCU_CTS_FrDrEVntCtrBdryUp_X 7;
BA_REL_ "GenSigTimeoutTime" BU_SG_REL_ L_EVNT SG_ 296 L_ATCU_CTS_FrDrEVntCtrBdryUp_X 5000;
BA_ "Version" SG_ 296 L_ATCU_CTS_FrDrEVntCtrBdryUp_X "24.05.11";
BA_ "Description" SG_ 296 L_ATCU_CTS_FrDrEVntCtrBdryUp_Y "Electric Vent FRT Dr Center Electric Vent Upper Range Y Coordinate";
BA_ "UserSigValidity" SG_ 296 L_ATCU_CTS_FrDrEVntCtrBdryUp_Y 7;
BA_REL_ "GenSigTimeoutTime" BU_SG_REL_ L_EVNT SG_ 296 L_ATCU_CTS_FrDrEVntCtrBdryUp_Y 5000;
BA_ "Version" SG_ 296 L_ATCU_CTS_FrDrEVntCtrBdryUp_Y "24.05.11";
BA_ "Description" SG_ 296 L_ATCU_CTS_FrDrEVntCtrBdryLo_X "Electric Vent FRT Dr Center Electric Vent Lower Range X Coordinate";
BA_ "UserSigValidity" SG_ 296 L_ATCU_CTS_FrDrEVntCtrBdryLo_X 7;
BA_REL_ "GenSigTimeoutTime" BU_SG_REL_ L_EVNT SG_ 296 L_ATCU_CTS_FrDrEVntCtrBdryLo_X 5000;
BA_ "Version" SG_ 296 L_ATCU_CTS_FrDrEVntCtrBdryLo_X "24.05.11";
BA_ "Description" SG_ 296 L_ATCU_CTS_FrDrEVntCtrBdryLo_Y "Electric Vent FRT Dr Center Electric Vent Lower Range Y Coordinate";
BA_ "UserSigValidity" SG_ 296 L_ATCU_CTS_FrDrEVntCtrBdryLo_Y 7;
BA_REL_ "GenSigTimeoutTime" BU_SG_REL_ L_EVNT SG_ 296 L_ATCU_CTS_FrDrEVntCtrBdryLo_Y 5000;
BA_ "Version" SG_ 296 L_ATCU_CTS_FrDrEVntCtrBdryLo_Y "24.05.11";
BA_ "Description" SG_ 296 L_ATCU_CTS_FrDrEVntSideBdryUp_Y "Electric Vent FRT Dr Side Electric Vent Upper Range Y Coordinate";
BA_ "UserSigValidity" SG_ 296 L_ATCU_CTS_FrDrEVntSideBdryUp_Y 7;
BA_REL_ "GenSigTimeoutTime" BU_SG_REL_ L_EVNT SG_ 296 L_ATCU_CTS_FrDrEVntSideBdryUp_Y 5000;
BA_ "Version" SG_ 296 L_ATCU_CTS_FrDrEVntSideBdryUp_Y "24.05.11";
BA_ "GenMsgSendType" BO_ 297 0;
BA_ "GenMsgCycleTime" BO_ 297 1000;
BA_ "GenMsgCycleTimeFast" BO_ 297 0;
BA_ "GenMsgNrOfRepetition" BO_ 297 0;
BA_ "Description" SG_ 297 L_ATCU_CTS_FrPsEVntSideBdryUp_X "Electric Vent FRT Ps Side Electric Vent Upper Range X Coordinate";
BA_ "UserSigValidity" SG_ 297 L_ATCU_CTS_FrPsEVntSideBdryUp_X 7;
BA_REL_ "GenSigTimeoutTime" BU_SG_REL_ L_EVNT SG_ 297 L_ATCU_CTS_FrPsEVntSideBdryUp_X 5000;
BA_ "Version" SG_ 297 L_ATCU_CTS_FrPsEVntSideBdryUp_X "24.05.11";
BA_ "Description" SG_ 297 L_ATCU_CTS_FrPsEVntSideBdryLo_X "Electric Vent FRT Ps Side Electric Vent Lower Range X Coordinate";
BA_ "UserSigValidity" SG_ 297 L_ATCU_CTS_FrPsEVntSideBdryLo_X 7;
BA_REL_ "GenSigTimeoutTime" BU_SG_REL_ L_EVNT SG_ 297 L_ATCU_CTS_FrPsEVntSideBdryLo_X 5000;
BA_ "Version" SG_ 297 L_ATCU_CTS_FrPsEVntSideBdryLo_X "24.05.11";
BA_ "Description" SG_ 297 L_ATCU_CTS_FrPsEVntSideBdryLo_Y "Electric Vent FRT Ps Side Electric Vent Lower Range Y Coordinate";
BA_ "UserSigValidity" SG_ 297 L_ATCU_CTS_FrPsEVntSideBdryLo_Y 7;
BA_REL_ "GenSigTimeoutTime" BU_SG_REL_ L_EVNT SG_ 297 L_ATCU_CTS_FrPsEVntSideBdryLo_Y 5000;
BA_ "Version" SG_ 297 L_ATCU_CTS_FrPsEVntSideBdryLo_Y "24.05.11";
BA_ "Description" SG_ 297 L_ATCU_CTS_FrPsEVntCtrBdryUp_X "Electric Vent FRT Ps Center Electric Vent Upper Range X Coordinate";
BA_ "UserSigValidity" SG_ 297 L_ATCU_CTS_FrPsEVntCtrBdryUp_X 7;
BA_REL_ "GenSigTimeoutTime" BU_SG_REL_ L_EVNT SG_ 297 L_ATCU_CTS_FrPsEVntCtrBdryUp_X 5000;
BA_ "Version" SG_ 297 L_ATCU_CTS_FrPsEVntCtrBdryUp_X "24.05.11";
BA_ "Description" SG_ 297 L_ATCU_CTS_FrPsEVntCtrBdryUp_Y "Electric Vent FRT Ps Center Electric Vent Upper Range Y Coordinate";
BA_ "UserSigValidity" SG_ 297 L_ATCU_CTS_FrPsEVntCtrBdryUp_Y 7;
BA_REL_ "GenSigTimeoutTime" BU_SG_REL_ L_EVNT SG_ 297 L_ATCU_CTS_FrPsEVntCtrBdryUp_Y 5000;
BA_ "Version" SG_ 297 L_ATCU_CTS_FrPsEVntCtrBdryUp_Y "24.05.11";
BA_ "Description" SG_ 297 L_ATCU_CTS_FrPsEVntCtrBdryLo_X "Electric Vent FRT Ps Center Electric Vent Lower Range X Coordinate";
BA_ "UserSigValidity" SG_ 297 L_ATCU_CTS_FrPsEVntCtrBdryLo_X 7;
BA_REL_ "GenSigTimeoutTime" BU_SG_REL_ L_EVNT SG_ 297 L_ATCU_CTS_FrPsEVntCtrBdryLo_X 5000;
BA_ "Version" SG_ 297 L_ATCU_CTS_FrPsEVntCtrBdryLo_X "24.05.11";
BA_ "Description" SG_ 297 L_ATCU_CTS_FrPsEVntCtrBdryLo_Y "Electric Vent FRT Ps Center Electric Vent Lower Range Y Coordinate";
BA_ "UserSigValidity" SG_ 297 L_ATCU_CTS_FrPsEVntCtrBdryLo_Y 7;
BA_REL_ "GenSigTimeoutTime" BU_SG_REL_ L_EVNT SG_ 297 L_ATCU_CTS_FrPsEVntCtrBdryLo_Y 5000;
BA_ "Version" SG_ 297 L_ATCU_CTS_FrPsEVntCtrBdryLo_Y "24.05.11";
BA_ "Description" SG_ 297 L_ATCU_CTS_FrPsEVntSideBdryUp_Y "Electric Vent FRT Ps Side Electric Vent Upper Range Y Coordinate";
BA_ "UserSigValidity" SG_ 297 L_ATCU_CTS_FrPsEVntSideBdryUp_Y 7;
BA_REL_ "GenSigTimeoutTime" BU_SG_REL_ L_EVNT SG_ 297 L_ATCU_CTS_FrPsEVntSideBdryUp_Y 5000;
BA_ "Version" SG_ 297 L_ATCU_CTS_FrPsEVntSideBdryUp_Y "24.05.11";
BA_ "GenMsgSendType" BO_ 769 0;
BA_ "GenMsgCycleTime" BO_ 769 500;
BA_ "Description" SG_ 769 MON_BatteryInit "This value only use for ATCU Library data monitoring (Only use before SOP)";
BA_ "GenSigSendType" SG_ 769 MON_BatteryInit 4;
BA_ "UserSigValidity" SG_ 769 MON_BatteryInit 0;
BA_REL_ "GenSigTimeoutTime" BU_SG_REL_ L_ATCU SG_ 769 MON_BatteryInit 5000;
BA_ "Version" SG_ 769 MON_BatteryInit "24.02.01";
BA_ "Description" SG_ 769 MON_StableStateSnsr "This value only use for ATCU Library data monitoring (Only use before SOP)";
BA_ "GenSigSendType" SG_ 769 MON_StableStateSnsr 4;
BA_ "UserSigValidity" SG_ 769 MON_StableStateSnsr 0;
BA_REL_ "GenSigTimeoutTime" BU_SG_REL_ L_ATCU SG_ 769 MON_StableStateSnsr 5000;
BA_ "Version" SG_ 769 MON_StableStateSnsr "24.02.01";
BA_ "Description" SG_ 769 MON_KeepMonitorReq "This value only use for ATCU Library data monitoring (Only use before SOP)";
BA_ "GenSigSendType" SG_ 769 MON_KeepMonitorReq 4;
BA_ "UserSigValidity" SG_ 769 MON_KeepMonitorReq 0;
BA_REL_ "GenSigTimeoutTime" BU_SG_REL_ L_ATCU SG_ 769 MON_KeepMonitorReq 5000;
BA_ "Version" SG_ 769 MON_KeepMonitorReq "24.02.01";
BA_ "Description" SG_ 769 MON_DevInputCtrlReq "ATCU Monitoring Function Development Mode Request

Bit 0 : 0 - Dev Not Apply / 1 - Dev Apply

Bit 1 : 0 - Dev Option Not Apply / 1- Dev Option Apply

Bit 2 : 0 - Dev Auto Not Apply / 1 - Dev Auto Apply

Bit 3 : 0 - Dev StatMngr Not Apply / 1 - Dev StatMngr Apply

Bit 4~7 : Reserved";
BA_ "GenSigSendType" SG_ 769 MON_DevInputCtrlReq 4;
BA_ "UserSigValidity" SG_ 769 MON_DevInputCtrlReq 0;
BA_REL_ "GenSigTimeoutTime" BU_SG_REL_ L_ATCU SG_ 769 MON_DevInputCtrlReq 5000;
BA_ "Version" SG_ 769 MON_DevInputCtrlReq "24.09.00";
BA_ "GenMsgSendType" BO_ 770 0;
BA_ "GenMsgCycleTime" BO_ 770 500;
BA_ "Description" SG_ 770 MON_InCarTempSnsr "This value only use for ATCU Library data monitoring (Only use before SOP)";
BA_ "GenSigSendType" SG_ 770 MON_InCarTempSnsr 4;
BA_ "GenSigStartValue" SG_ 770 MON_InCarTempSnsr 400;
BA_ "UserSigValidity" SG_ 770 MON_InCarTempSnsr 0;
BA_REL_ "GenSigTimeoutTime" BU_SG_REL_ L_ATCU SG_ 770 MON_InCarTempSnsr 5000;
BA_ "Version" SG_ 770 MON_InCarTempSnsr "24.02.01";
BA_ "Description" SG_ 770 MON_AMBTempSnsr "This value only use for ATCU Library data monitoring (Only use before SOP)";
BA_ "GenSigSendType" SG_ 770 MON_AMBTempSnsr 4;
BA_ "GenSigStartValue" SG_ 770 MON_AMBTempSnsr 400;
BA_ "UserSigValidity" SG_ 770 MON_AMBTempSnsr 0;
BA_REL_ "GenSigTimeoutTime" BU_SG_REL_ L_ATCU SG_ 770 MON_AMBTempSnsr 5000;
BA_ "Version" SG_ 770 MON_AMBTempSnsr "24.02.01";
BA_ "Description" SG_ 770 MON_EvapTempSnsr "This value only use for ATCU Library data monitoring (Only use before SOP)";
BA_ "GenSigSendType" SG_ 770 MON_EvapTempSnsr 4;
BA_ "GenSigStartValue" SG_ 770 MON_EvapTempSnsr 200;
BA_ "UserSigValidity" SG_ 770 MON_EvapTempSnsr 0;
BA_REL_ "GenSigTimeoutTime" BU_SG_REL_ L_ATCU SG_ 770 MON_EvapTempSnsr 5000;
BA_ "Version" SG_ 770 MON_EvapTempSnsr "24.02.01";
BA_ "Description" SG_ 770 MON_DOHSnsr "This value only use for ATCU Library data monitoring (Only use before SOP)";
BA_ "GenSigSendType" SG_ 770 MON_DOHSnsr 4;
BA_ "UserSigValidity" SG_ 770 MON_DOHSnsr 0;
BA_REL_ "GenSigTimeoutTime" BU_SG_REL_ L_ATCU SG_ 770 MON_DOHSnsr 5000;
BA_ "Version" SG_ 770 MON_DOHSnsr "23.11.13";
BA_ "GenMsgSendType" BO_ 771 0;
BA_ "GenMsgCycleTime" BO_ 771 500;
BA_ "Description" SG_ 771 MON_FineDustSnsr "This value only use for ATCU Library data monitoring (Only use before SOP)";
BA_ "GenSigSendType" SG_ 771 MON_FineDustSnsr 4;
BA_ "UserSigValidity" SG_ 771 MON_FineDustSnsr 0;
BA_REL_ "GenSigTimeoutTime" BU_SG_REL_ L_ATCU SG_ 771 MON_FineDustSnsr 5000;
BA_ "Version" SG_ 771 MON_FineDustSnsr "23.11.13";
BA_ "Description" SG_ 771 MON_LHPhotoSnsr "This value only use for ATCU Library data monitoring (Only use before SOP)";
BA_ "GenSigSendType" SG_ 771 MON_LHPhotoSnsr 4;
BA_ "UserSigValidity" SG_ 771 MON_LHPhotoSnsr 0;
BA_REL_ "GenSigTimeoutTime" BU_SG_REL_ L_ATCU SG_ 771 MON_LHPhotoSnsr 5000;
BA_ "Version" SG_ 771 MON_LHPhotoSnsr "23.11.13";
BA_ "Description" SG_ 771 MON_RHPhotoSnsr "This value only use for ATCU Library data monitoring (Only use before SOP)";
BA_ "GenSigSendType" SG_ 771 MON_RHPhotoSnsr 4;
BA_ "UserSigValidity" SG_ 771 MON_RHPhotoSnsr 0;
BA_REL_ "GenSigTimeoutTime" BU_SG_REL_ L_ATCU SG_ 771 MON_RHPhotoSnsr 5000;
BA_ "Version" SG_ 771 MON_RHPhotoSnsr "23.11.13";
BA_ "GenMsgSendType" BO_ 772 0;
BA_ "GenMsgCycleTime" BO_ 772 500;
BA_ "Description" SG_ 772 MON_DrvVentDuctSnsr "This value only use for ATCU Library data monitoring (Only use before SOP)";
BA_ "GenSigSendType" SG_ 772 MON_DrvVentDuctSnsr 4;
BA_ "GenSigStartValue" SG_ 772 MON_DrvVentDuctSnsr 400;
BA_ "UserSigValidity" SG_ 772 MON_DrvVentDuctSnsr 0;
BA_REL_ "GenSigTimeoutTime" BU_SG_REL_ L_ATCU SG_ 772 MON_DrvVentDuctSnsr 5000;
BA_ "Version" SG_ 772 MON_DrvVentDuctSnsr "24.02.01";
BA_ "Description" SG_ 772 MON_AstVentDuctSnsr "This value only use for ATCU Library data monitoring (Only use before SOP)";
BA_ "GenSigSendType" SG_ 772 MON_AstVentDuctSnsr 4;
BA_ "GenSigStartValue" SG_ 772 MON_AstVentDuctSnsr 400;
BA_ "UserSigValidity" SG_ 772 MON_AstVentDuctSnsr 0;
BA_REL_ "GenSigTimeoutTime" BU_SG_REL_ L_ATCU SG_ 772 MON_AstVentDuctSnsr 5000;
BA_ "Version" SG_ 772 MON_AstVentDuctSnsr "24.02.01";
BA_ "Description" SG_ 772 MON_DrvFloorDuctSnsr "This value only use for ATCU Library data monitoring (Only use before SOP)";
BA_ "GenSigSendType" SG_ 772 MON_DrvFloorDuctSnsr 4;
BA_ "GenSigStartValue" SG_ 772 MON_DrvFloorDuctSnsr 400;
BA_ "UserSigValidity" SG_ 772 MON_DrvFloorDuctSnsr 0;
BA_REL_ "GenSigTimeoutTime" BU_SG_REL_ L_ATCU SG_ 772 MON_DrvFloorDuctSnsr 5000;
BA_ "Version" SG_ 772 MON_DrvFloorDuctSnsr "24.02.01";
BA_ "Description" SG_ 772 MON_AstFloorDuctSnsr "This value only use for ATCU Library data monitoring (Only use before SOP)";
BA_ "GenSigSendType" SG_ 772 MON_AstFloorDuctSnsr 4;
BA_ "GenSigStartValue" SG_ 772 MON_AstFloorDuctSnsr 400;
BA_ "UserSigValidity" SG_ 772 MON_AstFloorDuctSnsr 0;
BA_REL_ "GenSigTimeoutTime" BU_SG_REL_ L_ATCU SG_ 772 MON_AstFloorDuctSnsr 5000;
BA_ "Version" SG_ 772 MON_AstFloorDuctSnsr "24.02.01";
BA_ "GenMsgSendType" BO_ 773 0;
BA_ "GenMsgCycleTime" BO_ 773 500;
BA_ "Description" SG_ 773 MON_DEFDuctSnsr "This value only use for ATCU Library data monitoring (Only use before SOP)";
BA_ "GenSigSendType" SG_ 773 MON_DEFDuctSnsr 4;
BA_ "GenSigStartValue" SG_ 773 MON_DEFDuctSnsr 400;
BA_ "UserSigValidity" SG_ 773 MON_DEFDuctSnsr 0;
BA_REL_ "GenSigTimeoutTime" BU_SG_REL_ L_ATCU SG_ 773 MON_DEFDuctSnsr 5000;
BA_ "Version" SG_ 773 MON_DEFDuctSnsr "24.02.01";
BA_ "Description" SG_ 773 MON_RrFloorDuctSnsr "This value only use for ATCU Library data monitoring (Only use before SOP)";
BA_ "GenSigSendType" SG_ 773 MON_RrFloorDuctSnsr 4;
BA_ "GenSigStartValue" SG_ 773 MON_RrFloorDuctSnsr 400;
BA_ "UserSigValidity" SG_ 773 MON_RrFloorDuctSnsr 0;
BA_REL_ "GenSigTimeoutTime" BU_SG_REL_ L_ATCU SG_ 773 MON_RrFloorDuctSnsr 5000;
BA_ "Version" SG_ 773 MON_RrFloorDuctSnsr "24.02.01";
BA_ "Description" SG_ 773 MON_RrVentDuctSnsr "This value only use for ATCU Library data monitoring (Only use before SOP)";
BA_ "GenSigSendType" SG_ 773 MON_RrVentDuctSnsr 4;
BA_ "GenSigStartValue" SG_ 773 MON_RrVentDuctSnsr 400;
BA_ "UserSigValidity" SG_ 773 MON_RrVentDuctSnsr 0;
BA_REL_ "GenSigTimeoutTime" BU_SG_REL_ L_ATCU SG_ 773 MON_RrVentDuctSnsr 5000;
BA_ "Version" SG_ 773 MON_RrVentDuctSnsr "24.02.01";
BA_ "Description" SG_ 773 MON_PMSnsrSta "This value only use for ATCU Library data monitoring (Only use before SOP)";
BA_ "GenSigSendType" SG_ 773 MON_PMSnsrSta 4;
BA_ "UserSigValidity" SG_ 773 MON_PMSnsrSta 0;
BA_REL_ "GenSigTimeoutTime" BU_SG_REL_ L_ATCU SG_ 773 MON_PMSnsrSta 5000;
BA_ "Version" SG_ 773 MON_PMSnsrSta "25.05.04";
BA_ "GenMsgSendType" BO_ 774 0;
BA_ "GenMsgCycleTime" BO_ 774 500;
BA_ "Description" SG_ 774 MON_IGN1 "This value only use for ATCU Library data monitoring (Only use before SOP)";
BA_ "GenSigSendType" SG_ 774 MON_IGN1 4;
BA_ "UserSigValidity" SG_ 774 MON_IGN1 0;
BA_REL_ "GenSigTimeoutTime" BU_SG_REL_ L_ATCU SG_ 774 MON_IGN1 5000;
BA_ "Version" SG_ 774 MON_IGN1 "24.06.02";
BA_ "Description" SG_ 774 MON_IGN2 "This value only use for ATCU Library data monitoring (Only use before SOP)";
BA_ "GenSigSendType" SG_ 774 MON_IGN2 4;
BA_ "UserSigValidity" SG_ 774 MON_IGN2 0;
BA_REL_ "GenSigTimeoutTime" BU_SG_REL_ L_ATCU SG_ 774 MON_IGN2 5000;
BA_ "Version" SG_ 774 MON_IGN2 "24.06.02";
BA_ "Description" SG_ 774 MON_VBAT "This value only use for ATCU Library data monitoring (Only use before SOP)";
BA_ "GenSigSendType" SG_ 774 MON_VBAT 4;
BA_ "UserSigValidity" SG_ 774 MON_VBAT 0;
BA_REL_ "GenSigTimeoutTime" BU_SG_REL_ L_ATCU SG_ 774 MON_VBAT 5000;
BA_ "Version" SG_ 774 MON_VBAT "25.05.04";
BA_ "Description" SG_ 774 MON_IGN3 "This value only use for ATCU Library data monitoring (Only use before SOP)";
BA_ "GenSigSendType" SG_ 774 MON_IGN3 4;
BA_ "UserSigValidity" SG_ 774 MON_IGN3 0;
BA_REL_ "GenSigTimeoutTime" BU_SG_REL_ L_ATCU SG_ 774 MON_IGN3 5000;
BA_ "Version" SG_ 774 MON_IGN3 "24.06.02";
BA_ "Description" SG_ 774 MON_PTCRly1 "This value only use for ATCU Library data monitoring (Only use before SOP)";
BA_ "GenSigSendType" SG_ 774 MON_PTCRly1 4;
BA_ "UserSigValidity" SG_ 774 MON_PTCRly1 0;
BA_REL_ "GenSigTimeoutTime" BU_SG_REL_ L_ATCU SG_ 774 MON_PTCRly1 5000;
BA_ "Version" SG_ 774 MON_PTCRly1 "24.06.02";
BA_ "Description" SG_ 774 MON_PTCRlyVtg "This value only use for ATCU Library data monitoring (Only use before SOP)";
BA_ "GenSigSendType" SG_ 774 MON_PTCRlyVtg 4;
BA_ "UserSigValidity" SG_ 774 MON_PTCRlyVtg 0;
BA_REL_ "GenSigTimeoutTime" BU_SG_REL_ L_ATCU SG_ 774 MON_PTCRlyVtg 5000;
BA_ "Version" SG_ 774 MON_PTCRlyVtg "24.09.00";
BA_ "GenMsgSendType" BO_ 775 0;
BA_ "GenMsgCycleTime" BO_ 775 500;
BA_ "Description" SG_ 775 MON_RgnOpt "This value only use for ATCU Library data monitoring (Only use before SOP)";
BA_ "GenSigSendType" SG_ 775 MON_RgnOpt 4;
BA_ "UserSigValidity" SG_ 775 MON_RgnOpt 0;
BA_REL_ "GenSigTimeoutTime" BU_SG_REL_ L_ATCU SG_ 775 MON_RgnOpt 5000;
BA_ "Version" SG_ 775 MON_RgnOpt "24.06.02";
BA_ "Description" SG_ 775 MON_DrvOnlyOpt "This value only use for ATCU Library data monitoring (Only use before SOP)";
BA_ "GenSigSendType" SG_ 775 MON_DrvOnlyOpt 4;
BA_ "UserSigValidity" SG_ 775 MON_DrvOnlyOpt 0;
BA_REL_ "GenSigTimeoutTime" BU_SG_REL_ L_ATCU SG_ 775 MON_DrvOnlyOpt 5000;
BA_ "Version" SG_ 775 MON_DrvOnlyOpt "24.06.02";
BA_ "Description" SG_ 775 MON_ADSOpt "This value only use for ATCU Library data monitoring (Only use before SOP)";
BA_ "GenSigSendType" SG_ 775 MON_ADSOpt 4;
BA_ "UserSigValidity" SG_ 775 MON_ADSOpt 0;
BA_REL_ "GenSigTimeoutTime" BU_SG_REL_ L_ATCU SG_ 775 MON_ADSOpt 5000;
BA_ "Version" SG_ 775 MON_ADSOpt "24.06.02";
BA_ "Description" SG_ 775 MON_AfterBlowOpt "This value only use for ATCU Library data monitoring (Only use before SOP)";
BA_ "GenSigSendType" SG_ 775 MON_AfterBlowOpt 4;
BA_ "UserSigValidity" SG_ 775 MON_AfterBlowOpt 0;
BA_REL_ "GenSigTimeoutTime" BU_SG_REL_ L_ATCU SG_ 775 MON_AfterBlowOpt 5000;
BA_ "Version" SG_ 775 MON_AfterBlowOpt "24.06.02";
BA_ "Description" SG_ 775 MON_SchdldVentOpt "This value only use for ATCU Library data monitoring (Only use before SOP)";
BA_ "GenSigSendType" SG_ 775 MON_SchdldVentOpt 4;
BA_ "UserSigValidity" SG_ 775 MON_SchdldVentOpt 0;
BA_REL_ "GenSigTimeoutTime" BU_SG_REL_ L_ATCU SG_ 775 MON_SchdldVentOpt 5000;
BA_ "Version" SG_ 775 MON_SchdldVentOpt "24.06.02";
BA_ "Description" SG_ 775 MON_FineDustOpt "This value only use for ATCU Library data monitoring (Only use before SOP)";
BA_ "GenSigSendType" SG_ 775 MON_FineDustOpt 4;
BA_ "UserSigValidity" SG_ 775 MON_FineDustOpt 0;
BA_REL_ "GenSigTimeoutTime" BU_SG_REL_ L_ATCU SG_ 775 MON_FineDustOpt 5000;
BA_ "Version" SG_ 775 MON_FineDustOpt "24.06.02";
BA_ "Description" SG_ 775 MON_FrontSyncCtrlTypOpt "This value only use for ATCU Library data monitoring (Only use before SOP)";
BA_ "GenSigSendType" SG_ 775 MON_FrontSyncCtrlTypOpt 4;
BA_ "UserSigValidity" SG_ 775 MON_FrontSyncCtrlTypOpt 0;
BA_REL_ "GenSigTimeoutTime" BU_SG_REL_ L_ATCU SG_ 775 MON_FrontSyncCtrlTypOpt 5000;
BA_ "Version" SG_ 775 MON_FrontSyncCtrlTypOpt "24.09.00";
BA_ "Description" SG_ 775 MON_CompOpt "This value only use for ATCU Library data monitoring (Only use before SOP)";
BA_ "GenSigSendType" SG_ 775 MON_CompOpt 4;
BA_ "UserSigValidity" SG_ 775 MON_CompOpt 0;
BA_REL_ "GenSigTimeoutTime" BU_SG_REL_ L_ATCU SG_ 775 MON_CompOpt 5000;
BA_ "Version" SG_ 775 MON_CompOpt "24.09.00";
BA_ "Description" SG_ 775 MON_WheelDrivePosOpt "This value only use for ATCU Library data monitoring (Only use before SOP)";
BA_ "GenSigSendType" SG_ 775 MON_WheelDrivePosOpt 4;
BA_ "UserSigValidity" SG_ 775 MON_WheelDrivePosOpt 0;
BA_REL_ "GenSigTimeoutTime" BU_SG_REL_ L_ATCU SG_ 775 MON_WheelDrivePosOpt 5000;
BA_ "Version" SG_ 775 MON_WheelDrivePosOpt "24.06.02";
BA_ "Description" SG_ 775 MON_NetworkTypOpt "This value only use for ATCU Library data monitoring (Only use before SOP)";
BA_ "GenSigSendType" SG_ 775 MON_NetworkTypOpt 4;
BA_ "UserSigValidity" SG_ 775 MON_NetworkTypOpt 0;
BA_REL_ "GenSigTimeoutTime" BU_SG_REL_ L_ATCU SG_ 775 MON_NetworkTypOpt 5000;
BA_ "Version" SG_ 775 MON_NetworkTypOpt "24.09.00";
BA_ "Description" SG_ 775 MON_AutoSwTyp "This value only use for ATCU Library data monitoring (Only use before SOP)";
BA_ "GenSigSendType" SG_ 775 MON_AutoSwTyp 4;
BA_ "UserSigValidity" SG_ 775 MON_AutoSwTyp 0;
BA_REL_ "GenSigTimeoutTime" BU_SG_REL_ L_ATCU SG_ 775 MON_AutoSwTyp 5000;
BA_ "Version" SG_ 775 MON_AutoSwTyp "24.06.02";
BA_ "Description" SG_ 775 MON_ModSwTypOpt "This value only use for ATCU Library data monitoring (Only use before SOP)";
BA_ "GenSigSendType" SG_ 775 MON_ModSwTypOpt 4;
BA_ "UserSigValidity" SG_ 775 MON_ModSwTypOpt 0;
BA_REL_ "GenSigTimeoutTime" BU_SG_REL_ L_ATCU SG_ 775 MON_ModSwTypOpt 5000;
BA_ "Version" SG_ 775 MON_ModSwTypOpt "24.06.02";
BA_ "Description" SG_ 775 MON_IntakeSwTypOpt "This value only use for ATCU Library data monitoring (Only use before SOP)";
BA_ "GenSigSendType" SG_ 775 MON_IntakeSwTypOpt 4;
BA_ "UserSigValidity" SG_ 775 MON_IntakeSwTypOpt 0;
BA_REL_ "GenSigTimeoutTime" BU_SG_REL_ L_ATCU SG_ 775 MON_IntakeSwTypOpt 5000;
BA_ "Version" SG_ 775 MON_IntakeSwTypOpt "24.06.02";
BA_ "Description" SG_ 775 MON_OffSwTypOpt "This value only use for ATCU Library data monitoring (Only use before SOP)";
BA_ "GenSigSendType" SG_ 775 MON_OffSwTypOpt 4;
BA_ "UserSigValidity" SG_ 775 MON_OffSwTypOpt 0;
BA_REL_ "GenSigTimeoutTime" BU_SG_REL_ L_ATCU SG_ 775 MON_OffSwTypOpt 5000;
BA_ "Version" SG_ 775 MON_OffSwTypOpt "24.06.02";
BA_ "Description" SG_ 775 MON_TempSwKnobOpt "This value only use for ATCU Library data monitoring (Only use before SOP)";
BA_ "GenSigSendType" SG_ 775 MON_TempSwKnobOpt 4;
BA_ "UserSigValidity" SG_ 775 MON_TempSwKnobOpt 0;
BA_REL_ "GenSigTimeoutTime" BU_SG_REL_ L_ATCU SG_ 775 MON_TempSwKnobOpt 5000;
BA_ "Version" SG_ 775 MON_TempSwKnobOpt "24.06.02";
BA_ "Description" SG_ 775 MON_BlrSwKnobOpt "This value only use for ATCU Library data monitoring (Only use before SOP)";
BA_ "GenSigSendType" SG_ 775 MON_BlrSwKnobOpt 4;
BA_ "UserSigValidity" SG_ 775 MON_BlrSwKnobOpt 0;
BA_REL_ "GenSigTimeoutTime" BU_SG_REL_ L_ATCU SG_ 775 MON_BlrSwKnobOpt 5000;
BA_ "Version" SG_ 775 MON_BlrSwKnobOpt "24.06.02";
BA_ "Description" SG_ 775 MON_BATCoolingTypOpt "This value only use for ATCU Library data monitoring (Only use before SOP)";
BA_ "GenSigSendType" SG_ 775 MON_BATCoolingTypOpt 4;
BA_ "UserSigValidity" SG_ 775 MON_BATCoolingTypOpt 0;
BA_REL_ "GenSigTimeoutTime" BU_SG_REL_ L_ATCU SG_ 775 MON_BATCoolingTypOpt 5000;
BA_ "Version" SG_ 775 MON_BATCoolingTypOpt "24.06.02";
BA_ "Description" SG_ 775 MON_PTCStepOpt "This value only use for ATCU Library data monitoring (Only use before SOP)";
BA_ "GenSigSendType" SG_ 775 MON_PTCStepOpt 4;
BA_ "UserSigValidity" SG_ 775 MON_PTCStepOpt 0;
BA_REL_ "GenSigTimeoutTime" BU_SG_REL_ L_ATCU SG_ 775 MON_PTCStepOpt 5000;
BA_ "Version" SG_ 775 MON_PTCStepOpt "24.06.02";
BA_ "Description" SG_ 775 MON_PTCTypOpt "This value only use for ATCU Library data monitoring (Only use before SOP)";
BA_ "GenSigSendType" SG_ 775 MON_PTCTypOpt 4;
BA_ "UserSigValidity" SG_ 775 MON_PTCTypOpt 0;
BA_REL_ "GenSigTimeoutTime" BU_SG_REL_ L_ATCU SG_ 775 MON_PTCTypOpt 5000;
BA_ "Version" SG_ 775 MON_PTCTypOpt "24.06.02";
BA_ "Description" SG_ 775 MON_ThermostatOpt "This value only use for ATCU Library data monitoring (Only use before SOP)";
BA_ "GenSigSendType" SG_ 775 MON_ThermostatOpt 4;
BA_ "UserSigValidity" SG_ 775 MON_ThermostatOpt 0;
BA_REL_ "GenSigTimeoutTime" BU_SG_REL_ L_ATCU SG_ 775 MON_ThermostatOpt 5000;
BA_ "Version" SG_ 775 MON_ThermostatOpt "24.06.02";
BA_ "Description" SG_ 775 MON_SmartVentOpt "This value only use for ATCU Library data monitoring (Only use before SOP)";
BA_ "GenSigSendType" SG_ 775 MON_SmartVentOpt 4;
BA_ "UserSigValidity" SG_ 775 MON_SmartVentOpt 0;
BA_REL_ "GenSigTimeoutTime" BU_SG_REL_ L_ATCU SG_ 775 MON_SmartVentOpt 5000;
BA_ "Version" SG_ 775 MON_SmartVentOpt "24.06.02";
BA_ "Description" SG_ 775 MON_ROATypOpt "This value only use for ATCU Library data monitoring (Only use before SOP)";
BA_ "GenSigSendType" SG_ 775 MON_ROATypOpt 4;
BA_ "UserSigValidity" SG_ 775 MON_ROATypOpt 0;
BA_REL_ "GenSigTimeoutTime" BU_SG_REL_ L_ATCU SG_ 775 MON_ROATypOpt 5000;
BA_ "Version" SG_ 775 MON_ROATypOpt "24.06.02";
BA_ "Description" SG_ 775 MON_VehTypOpt "This value only use for ATCU Library data monitoring (Only use before SOP)";
BA_ "GenSigSendType" SG_ 775 MON_VehTypOpt 4;
BA_ "UserSigValidity" SG_ 775 MON_VehTypOpt 0;
BA_REL_ "GenSigTimeoutTime" BU_SG_REL_ L_ATCU SG_ 775 MON_VehTypOpt 5000;
BA_ "Version" SG_ 775 MON_VehTypOpt "24.06.02";
BA_ "Description" SG_ 775 MON_VRLedOpt "This value only use for ATCU Library data monitoring (Only use before SOP)";
BA_ "GenSigSendType" SG_ 775 MON_VRLedOpt 4;
BA_ "UserSigValidity" SG_ 775 MON_VRLedOpt 0;
BA_REL_ "GenSigTimeoutTime" BU_SG_REL_ L_ATCU SG_ 775 MON_VRLedOpt 5000;
BA_ "Version" SG_ 775 MON_VRLedOpt "24.06.02";
BA_ "Description" SG_ 775 MON_FrontAutoStepOpt "This value only use for ATCU Library data monitoring (Only use before SOP)";
BA_ "GenSigSendType" SG_ 775 MON_FrontAutoStepOpt 4;
BA_ "UserSigValidity" SG_ 775 MON_FrontAutoStepOpt 0;
BA_REL_ "GenSigTimeoutTime" BU_SG_REL_ L_ATCU SG_ 775 MON_FrontAutoStepOpt 5000;
BA_ "Version" SG_ 775 MON_FrontAutoStepOpt "24.06.02";
BA_ "Description" SG_ 775 MON_2ndAutoStepOpt "This value only use for ATCU Library data monitoring (Only use before SOP)";
BA_ "GenSigSendType" SG_ 775 MON_2ndAutoStepOpt 4;
BA_ "UserSigValidity" SG_ 775 MON_2ndAutoStepOpt 0;
BA_REL_ "GenSigTimeoutTime" BU_SG_REL_ L_ATCU SG_ 775 MON_2ndAutoStepOpt 5000;
BA_ "Version" SG_ 775 MON_2ndAutoStepOpt "24.06.02";
BA_ "Description" SG_ 775 MON_2ndAutoSwTyp "This value only use for ATCU Library data monitoring (Only use before SOP)";
BA_ "GenSigSendType" SG_ 775 MON_2ndAutoSwTyp 4;
BA_ "UserSigValidity" SG_ 775 MON_2ndAutoSwTyp 0;
BA_REL_ "GenSigTimeoutTime" BU_SG_REL_ L_ATCU SG_ 775 MON_2ndAutoSwTyp 5000;
BA_ "Version" SG_ 775 MON_2ndAutoSwTyp "24.06.02";
BA_ "Description" SG_ 775 MON_2ndOffSwTypOpt "This value only use for ATCU Library data monitoring (Only use before SOP)";
BA_ "GenSigSendType" SG_ 775 MON_2ndOffSwTypOpt 4;
BA_ "UserSigValidity" SG_ 775 MON_2ndOffSwTypOpt 0;
BA_REL_ "GenSigTimeoutTime" BU_SG_REL_ L_ATCU SG_ 775 MON_2ndOffSwTypOpt 5000;
BA_ "Version" SG_ 775 MON_2ndOffSwTypOpt "24.09.00";
BA_ "Description" SG_ 775 MON_2ndModSwTypOpt "This value only use for ATCU Library data monitoring (Only use before SOP)";
BA_ "GenSigSendType" SG_ 775 MON_2ndModSwTypOpt 4;
BA_ "UserSigValidity" SG_ 775 MON_2ndModSwTypOpt 0;
BA_REL_ "GenSigTimeoutTime" BU_SG_REL_ L_ATCU SG_ 775 MON_2ndModSwTypOpt 5000;
BA_ "Version" SG_ 775 MON_2ndModSwTypOpt "24.09.00";
BA_ "Description" SG_ 775 MON_2ndAutoBtnOpt "This value only use for ATCU Library data monitoring (Only use before SOP)";
BA_ "GenSigSendType" SG_ 775 MON_2ndAutoBtnOpt 4;
BA_ "UserSigValidity" SG_ 775 MON_2ndAutoBtnOpt 0;
BA_REL_ "GenSigTimeoutTime" BU_SG_REL_ L_ATCU SG_ 775 MON_2ndAutoBtnOpt 5000;
BA_ "Version" SG_ 775 MON_2ndAutoBtnOpt "24.09.00";
BA_ "Description" SG_ 775 MON_2ndBlrBtnOpt "This value only use for ATCU Library data monitoring (Only use before SOP)";
BA_ "GenSigSendType" SG_ 775 MON_2ndBlrBtnOpt 4;
BA_ "UserSigValidity" SG_ 775 MON_2ndBlrBtnOpt 0;
BA_REL_ "GenSigTimeoutTime" BU_SG_REL_ L_ATCU SG_ 775 MON_2ndBlrBtnOpt 5000;
BA_ "Version" SG_ 775 MON_2ndBlrBtnOpt "24.09.00";
BA_ "Description" SG_ 775 MON_2ndModBtnOpt "This value only use for ATCU Library data monitoring (Only use before SOP)";
BA_ "GenSigSendType" SG_ 775 MON_2ndModBtnOpt 4;
BA_ "UserSigValidity" SG_ 775 MON_2ndModBtnOpt 0;
BA_REL_ "GenSigTimeoutTime" BU_SG_REL_ L_ATCU SG_ 775 MON_2ndModBtnOpt 5000;
BA_ "Version" SG_ 775 MON_2ndModBtnOpt "24.09.00";
BA_ "Description" SG_ 775 MON_2ndTmpBtnOpt "This value only use for ATCU Library data monitoring (Only use before SOP)";
BA_ "GenSigSendType" SG_ 775 MON_2ndTmpBtnOpt 4;
BA_ "UserSigValidity" SG_ 775 MON_2ndTmpBtnOpt 0;
BA_REL_ "GenSigTimeoutTime" BU_SG_REL_ L_ATCU SG_ 775 MON_2ndTmpBtnOpt 5000;
BA_ "Version" SG_ 775 MON_2ndTmpBtnOpt "24.09.00";
BA_ "Description" SG_ 775 MON_2ndTempSwKnobOpt "This value only use for ATCU Library data monitoring (Only use before SOP)";
BA_ "GenSigSendType" SG_ 775 MON_2ndTempSwKnobOpt 4;
BA_ "UserSigValidity" SG_ 775 MON_2ndTempSwKnobOpt 0;
BA_REL_ "GenSigTimeoutTime" BU_SG_REL_ L_ATCU SG_ 775 MON_2ndTempSwKnobOpt 5000;
BA_ "Version" SG_ 775 MON_2ndTempSwKnobOpt "24.09.00";
BA_ "Description" SG_ 775 MON_DrvHndSideOpt "This value only use for ATCU Library data monitoring (Only use before SOP)";
BA_ "GenSigSendType" SG_ 775 MON_DrvHndSideOpt 4;
BA_ "UserSigValidity" SG_ 775 MON_DrvHndSideOpt 0;
BA_REL_ "GenSigTimeoutTime" BU_SG_REL_ L_ATCU SG_ 775 MON_DrvHndSideOpt 5000;
BA_ "Version" SG_ 775 MON_DrvHndSideOpt "24.09.00";
BA_ "Description" SG_ 775 MON_DisplayOpt "This value only use for ATCU Library data monitoring (Only use before SOP)";
BA_ "GenSigSendType" SG_ 775 MON_DisplayOpt 4;
BA_ "UserSigValidity" SG_ 775 MON_DisplayOpt 0;
BA_REL_ "GenSigTimeoutTime" BU_SG_REL_ L_ATCU SG_ 775 MON_DisplayOpt 5000;
BA_ "Version" SG_ 775 MON_DisplayOpt "24.09.00";
BA_ "GenMsgSendType" BO_ 778 0;
BA_ "GenMsgCycleTime" BO_ 778 500;
BA_ "Description" SG_ 778 MON_Auto2LHBlrVtgVal "This value only use for ATCU Library data monitoring (Only use before SOP)";
BA_ "GenSigSendType" SG_ 778 MON_Auto2LHBlrVtgVal 4;
BA_ "UserSigValidity" SG_ 778 MON_Auto2LHBlrVtgVal 0;
BA_REL_ "GenSigTimeoutTime" BU_SG_REL_ L_ATCU SG_ 778 MON_Auto2LHBlrVtgVal 5000;
BA_ "Version" SG_ 778 MON_Auto2LHBlrVtgVal "24.06.02";
BA_ "Description" SG_ 778 MON_Auto2LHModState "This value only use for ATCU Library data monitoring (Only use before SOP)";
BA_ "GenSigSendType" SG_ 778 MON_Auto2LHModState 4;
BA_ "UserSigValidity" SG_ 778 MON_Auto2LHModState 0;
BA_REL_ "GenSigTimeoutTime" BU_SG_REL_ L_ATCU SG_ 778 MON_Auto2LHModState 5000;
BA_ "Version" SG_ 778 MON_Auto2LHModState "24.06.02";
BA_ "Description" SG_ 778 MON_Auto2LHTempDrState "This value only use for ATCU Library data monitoring (Only use before SOP)";
BA_ "GenSigSendType" SG_ 778 MON_Auto2LHTempDrState 4;
BA_ "UserSigValidity" SG_ 778 MON_Auto2LHTempDrState 0;
BA_REL_ "GenSigTimeoutTime" BU_SG_REL_ L_ATCU SG_ 778 MON_Auto2LHTempDrState 5000;
BA_ "Version" SG_ 778 MON_Auto2LHTempDrState "24.06.02";
BA_ "Description" SG_ 778 MON_AutoHeatloadStep "This value only use for ATCU Library data monitoring (Only use before SOP)";
BA_ "GenSigSendType" SG_ 778 MON_AutoHeatloadStep 4;
BA_ "UserSigValidity" SG_ 778 MON_AutoHeatloadStep 0;
BA_REL_ "GenSigTimeoutTime" BU_SG_REL_ L_ATCU SG_ 778 MON_AutoHeatloadStep 5000;
BA_ "Version" SG_ 778 MON_AutoHeatloadStep "24.06.02";
BA_ "Description" SG_ 778 MON_AutoHVPTCDuty "This value only use for ATCU Library data monitoring (Only use before SOP)";
BA_ "GenSigSendType" SG_ 778 MON_AutoHVPTCDuty 4;
BA_ "UserSigValidity" SG_ 778 MON_AutoHVPTCDuty 0;
BA_REL_ "GenSigTimeoutTime" BU_SG_REL_ L_ATCU SG_ 778 MON_AutoHVPTCDuty 5000;
BA_ "Version" SG_ 778 MON_AutoHVPTCDuty "24.06.02";
BA_ "Description" SG_ 778 MON_AutoECompRpm "This value only use for ATCU Library data monitoring (Only use before SOP)";
BA_ "GenSigSendType" SG_ 778 MON_AutoECompRpm 4;
BA_ "UserSigValidity" SG_ 778 MON_AutoECompRpm 0;
BA_REL_ "GenSigTimeoutTime" BU_SG_REL_ L_ATCU SG_ 778 MON_AutoECompRpm 5000;
BA_ "Version" SG_ 778 MON_AutoECompRpm "24.06.02";
BA_ "GenMsgSendType" BO_ 797 0;
BA_ "GenMsgCycleTime" BO_ 797 500;
BA_ "Description" SG_ 797 MON_AutoDrvTempDrVtgVal "This value only use for ATCU Library data monitoring (Only use before SOP)";
BA_ "GenSigSendType" SG_ 797 MON_AutoDrvTempDrVtgVal 4;
BA_ "UserSigValidity" SG_ 797 MON_AutoDrvTempDrVtgVal 0;
BA_REL_ "GenSigTimeoutTime" BU_SG_REL_ L_ATCU SG_ 797 MON_AutoDrvTempDrVtgVal 5000;
BA_ "Version" SG_ 797 MON_AutoDrvTempDrVtgVal "25.05.04";
BA_ "Description" SG_ 797 MON_AutoAstTempDrVtgVal "This value only use for ATCU Library data monitoring (Only use before SOP)";
BA_ "GenSigSendType" SG_ 797 MON_AutoAstTempDrVtgVal 4;
BA_ "UserSigValidity" SG_ 797 MON_AutoAstTempDrVtgVal 0;
BA_REL_ "GenSigTimeoutTime" BU_SG_REL_ L_ATCU SG_ 797 MON_AutoAstTempDrVtgVal 5000;
BA_ "Version" SG_ 797 MON_AutoAstTempDrVtgVal "25.05.04";
BA_ "Description" SG_ 797 MON_AutoDrv2TempDrVtgVal "This value only use for ATCU Library data monitoring (Only use before SOP)";
BA_ "GenSigSendType" SG_ 797 MON_AutoDrv2TempDrVtgVal 4;
BA_ "UserSigValidity" SG_ 797 MON_AutoDrv2TempDrVtgVal 0;
BA_REL_ "GenSigTimeoutTime" BU_SG_REL_ L_ATCU SG_ 797 MON_AutoDrv2TempDrVtgVal 5000;
BA_ "Version" SG_ 797 MON_AutoDrv2TempDrVtgVal "25.05.04";
BA_ "Description" SG_ 797 MON_ADSTempDrLmtState "This value only use for ATCU Library data monitoring (Only use before SOP)";
BA_ "GenSigSendType" SG_ 797 MON_ADSTempDrLmtState 4;
BA_ "UserSigValidity" SG_ 797 MON_ADSTempDrLmtState 0;
BA_REL_ "GenSigTimeoutTime" BU_SG_REL_ L_ATCU SG_ 797 MON_ADSTempDrLmtState 5000;
BA_ "Version" SG_ 797 MON_ADSTempDrLmtState "25.05.04";
BA_ "GenMsgSendType" BO_ 798 0;
BA_ "GenMsgCycleTime" BO_ 798 500;
BA_ "Description" SG_ 798 MON_ADSModState "This value only use for ATCU Library data monitoring (Only use before SOP)";
BA_ "GenSigSendType" SG_ 798 MON_ADSModState 4;
BA_ "UserSigValidity" SG_ 798 MON_ADSModState 0;
BA_REL_ "GenSigTimeoutTime" BU_SG_REL_ L_ATCU SG_ 798 MON_ADSModState 5000;
BA_ "Version" SG_ 798 MON_ADSModState "25.05.04";
BA_ "Description" SG_ 798 MON_ADSACForcedOnReq "This value only use for ATCU Library data monitoring (Only use before SOP)";
BA_ "GenSigSendType" SG_ 798 MON_ADSACForcedOnReq 4;
BA_ "UserSigValidity" SG_ 798 MON_ADSACForcedOnReq 0;
BA_REL_ "GenSigTimeoutTime" BU_SG_REL_ L_ATCU SG_ 798 MON_ADSACForcedOnReq 5000;
BA_ "Version" SG_ 798 MON_ADSACForcedOnReq "25.05.04";
BA_ "Description" SG_ 798 MON_ADSACDispPreValHoldReq "This value only use for ATCU Library data monitoring (Only use before SOP)";
BA_ "GenSigSendType" SG_ 798 MON_ADSACDispPreValHoldReq 4;
BA_ "UserSigValidity" SG_ 798 MON_ADSACDispPreValHoldReq 0;
BA_REL_ "GenSigTimeoutTime" BU_SG_REL_ L_ATCU SG_ 798 MON_ADSACDispPreValHoldReq 5000;
BA_ "Version" SG_ 798 MON_ADSACDispPreValHoldReq "25.05.04";
BA_ "Description" SG_ 798 MON_ADSSymState "This value only use for ATCU Library data monitoring (Only use before SOP)";
BA_ "GenSigSendType" SG_ 798 MON_ADSSymState 4;
BA_ "UserSigValidity" SG_ 798 MON_ADSSymState 0;
BA_REL_ "GenSigTimeoutTime" BU_SG_REL_ L_ATCU SG_ 798 MON_ADSSymState 5000;
BA_ "Version" SG_ 798 MON_ADSSymState "25.05.04";
BA_ "Description" SG_ 798 MON_ADSInhibitPIReq "This value only use for ATCU Library data monitoring (Only use before SOP)";
BA_ "GenSigSendType" SG_ 798 MON_ADSInhibitPIReq 4;
BA_ "UserSigValidity" SG_ 798 MON_ADSInhibitPIReq 0;
BA_REL_ "GenSigTimeoutTime" BU_SG_REL_ L_ATCU SG_ 798 MON_ADSInhibitPIReq 5000;
BA_ "Version" SG_ 798 MON_ADSInhibitPIReq "25.05.04";
BA_ "Description" SG_ 798 MON_ADSOpState "This value only use for ATCU Library data monitoring (Only use before SOP)";
BA_ "GenSigSendType" SG_ 798 MON_ADSOpState 4;
BA_ "UserSigValidity" SG_ 798 MON_ADSOpState 0;
BA_REL_ "GenSigTimeoutTime" BU_SG_REL_ L_ATCU SG_ 798 MON_ADSOpState 5000;
BA_ "Version" SG_ 798 MON_ADSOpState "25.05.04";
BA_ "Description" SG_ 798 MON_ADSBlrVtgVal "This value only use for ATCU Library data monitoring (Only use before SOP)";
BA_ "GenSigSendType" SG_ 798 MON_ADSBlrVtgVal 4;
BA_ "UserSigValidity" SG_ 798 MON_ADSBlrVtgVal 0;
BA_REL_ "GenSigTimeoutTime" BU_SG_REL_ L_ATCU SG_ 798 MON_ADSBlrVtgVal 5000;
BA_ "Version" SG_ 798 MON_ADSBlrVtgVal "25.05.04";
BA_ "Description" SG_ 798 MON_ADSIntakeState "This value only use for ATCU Library data monitoring (Only use before SOP)";
BA_ "GenSigSendType" SG_ 798 MON_ADSIntakeState 4;
BA_ "UserSigValidity" SG_ 798 MON_ADSIntakeState 0;
BA_REL_ "GenSigTimeoutTime" BU_SG_REL_ L_ATCU SG_ 798 MON_ADSIntakeState 5000;
BA_ "Version" SG_ 798 MON_ADSIntakeState "25.05.04";
BA_ "Description" SG_ 798 MON_ADSDEFDrState "This value only use for ATCU Library data monitoring (Only use before SOP)";
BA_ "GenSigSendType" SG_ 798 MON_ADSDEFDrState 4;
BA_ "UserSigValidity" SG_ 798 MON_ADSDEFDrState 0;
BA_REL_ "GenSigTimeoutTime" BU_SG_REL_ L_ATCU SG_ 798 MON_ADSDEFDrState 5000;
BA_ "Version" SG_ 798 MON_ADSDEFDrState "25.05.04";
BA_ "Description" SG_ 798 MON_ADSModPrfleChgReq "This value only use for ATCU Library data monitoring (Only use before SOP)";
BA_ "GenSigSendType" SG_ 798 MON_ADSModPrfleChgReq 4;
BA_ "UserSigValidity" SG_ 798 MON_ADSModPrfleChgReq 0;
BA_REL_ "GenSigTimeoutTime" BU_SG_REL_ L_ATCU SG_ 798 MON_ADSModPrfleChgReq 5000;
BA_ "Version" SG_ 798 MON_ADSModPrfleChgReq "25.05.04";
BA_ "Description" SG_ 798 MON_ADSACState "This value only use for ATCU Library data monitoring (Only use before SOP)";
BA_ "GenSigSendType" SG_ 798 MON_ADSACState 4;
BA_ "UserSigValidity" SG_ 798 MON_ADSACState 0;
BA_REL_ "GenSigTimeoutTime" BU_SG_REL_ L_ATCU SG_ 798 MON_ADSACState 5000;
BA_ "Version" SG_ 798 MON_ADSACState "25.05.04";
BA_ "GenMsgSendType" BO_ 779 0;
BA_ "GenMsgCycleTime" BO_ 779 2000;
BA_ "Description" SG_ 779 MON_StatMngr_Humid "This value only use for ATCU Library data monitoring (Only use before SOP)";
BA_ "GenSigSendType" SG_ 779 MON_StatMngr_Humid 4;
BA_ "UserSigValidity" SG_ 779 MON_StatMngr_Humid 0;
BA_REL_ "GenSigTimeoutTime" BU_SG_REL_ L_ATCU SG_ 779 MON_StatMngr_Humid 5000;
BA_ "Version" SG_ 779 MON_StatMngr_Humid "24.09.01";
BA_ "GenMsgSendType" BO_ 780 0;
BA_ "GenMsgCycleTime" BO_ 780 2000;
BA_ "Description" SG_ 780 MON_StatMngr_Temp "This value only use for ATCU Library data monitoring (Only use before SOP)";
BA_ "GenSigSendType" SG_ 780 MON_StatMngr_Temp 4;
BA_ "UserSigValidity" SG_ 780 MON_StatMngr_Temp 0;
BA_REL_ "GenSigTimeoutTime" BU_SG_REL_ L_ATCU SG_ 780 MON_StatMngr_Temp 5000;
BA_ "Version" SG_ 780 MON_StatMngr_Temp "24.09.01";
BA_ "GenMsgSendType" BO_ 781 0;
BA_ "GenMsgCycleTime" BO_ 781 2000;
BA_ "Description" SG_ 781 MON_StatMngr_SafetynCool "This value only use for ATCU Library data monitoring (Only use before SOP)";
BA_ "GenSigSendType" SG_ 781 MON_StatMngr_SafetynCool 4;
BA_ "UserSigValidity" SG_ 781 MON_StatMngr_SafetynCool 0;
BA_REL_ "GenSigTimeoutTime" BU_SG_REL_ L_ATCU SG_ 781 MON_StatMngr_SafetynCool 5000;
BA_ "Version" SG_ 781 MON_StatMngr_SafetynCool "24.09.01";
BA_ "GenMsgSendType" BO_ 782 0;
BA_ "GenMsgCycleTime" BO_ 782 2000;
BA_ "Description" SG_ 782 MON_StatMngr_Mngr "This value only use for ATCU Library data monitoring (Only use before SOP)";
BA_ "GenSigSendType" SG_ 782 MON_StatMngr_Mngr 4;
BA_ "UserSigValidity" SG_ 782 MON_StatMngr_Mngr 0;
BA_REL_ "GenSigTimeoutTime" BU_SG_REL_ L_ATCU SG_ 782 MON_StatMngr_Mngr 5000;
BA_ "Version" SG_ 782 MON_StatMngr_Mngr "24.09.01";
BA_ "GenMsgSendType" BO_ 783 0;
BA_ "GenMsgCycleTime" BO_ 783 2000;
BA_ "Description" SG_ 783 MON_StatMngr_Convenience "This value only use for ATCU Library data monitoring (Only use before SOP)";
BA_ "GenSigSendType" SG_ 783 MON_StatMngr_Convenience 4;
BA_ "UserSigValidity" SG_ 783 MON_StatMngr_Convenience 0;
BA_REL_ "GenSigTimeoutTime" BU_SG_REL_ L_ATCU SG_ 783 MON_StatMngr_Convenience 5000;
BA_ "Version" SG_ 783 MON_StatMngr_Convenience "24.09.01";
BA_ "GenMsgSendType" BO_ 784 0;
BA_ "GenMsgCycleTime" BO_ 784 2000;
BA_ "Description" SG_ 784 MON_StatMngr_AirQuality "This value only use for ATCU Library data monitoring (Only use before SOP)";
BA_ "GenSigSendType" SG_ 784 MON_StatMngr_AirQuality 4;
BA_ "UserSigValidity" SG_ 784 MON_StatMngr_AirQuality 0;
BA_REL_ "GenSigTimeoutTime" BU_SG_REL_ L_ATCU SG_ 784 MON_StatMngr_AirQuality 5000;
BA_ "Version" SG_ 784 MON_StatMngr_AirQuality "24.09.01";
BA_ "GenMsgSendType" BO_ 792 0;
BA_ "GenMsgCycleTime" BO_ 792 2000;
BA_ "Description" SG_ 792 MON_StatMngr_2ndConvenience "This value only use for ATCU Library data monitoring (Only use before SOP)";
BA_ "GenSigSendType" SG_ 792 MON_StatMngr_2ndConvenience 4;
BA_ "UserSigValidity" SG_ 792 MON_StatMngr_2ndConvenience 0;
BA_REL_ "GenSigTimeoutTime" BU_SG_REL_ L_ATCU SG_ 792 MON_StatMngr_2ndConvenience 5000;
BA_ "Version" SG_ 792 MON_StatMngr_2ndConvenience "24.09.01";
BA_ "GenMsgSendType" BO_ 793 0;
BA_ "GenMsgCycleTime" BO_ 793 2000;
BA_ "Description" SG_ 793 MON_StatMngr_2ndAirQuality "This value only use for ATCU Library data monitoring (Only use before SOP)";
BA_ "GenSigSendType" SG_ 793 MON_StatMngr_2ndAirQuality 4;
BA_ "UserSigValidity" SG_ 793 MON_StatMngr_2ndAirQuality 0;
BA_REL_ "GenSigTimeoutTime" BU_SG_REL_ L_ATCU SG_ 793 MON_StatMngr_2ndAirQuality 5000;
BA_ "Version" SG_ 793 MON_StatMngr_2ndAirQuality "24.09.01";
BA_ "GenMsgSendType" BO_ 794 0;
BA_ "GenMsgCycleTime" BO_ 794 2000;
BA_ "Description" SG_ 794 MON_StatMngr_2ndETC "This value only use for ATCU Library data monitoring (Only use before SOP)";
BA_ "GenSigSendType" SG_ 794 MON_StatMngr_2ndETC 4;
BA_ "UserSigValidity" SG_ 794 MON_StatMngr_2ndETC 0;
BA_REL_ "GenSigTimeoutTime" BU_SG_REL_ L_ATCU SG_ 794 MON_StatMngr_2ndETC 5000;
BA_ "Version" SG_ 794 MON_StatMngr_2ndETC "24.09.01";
BA_ "GenMsgSendType" BO_ 795 0;
BA_ "GenMsgCycleTime" BO_ 795 2000;
BA_ "Description" SG_ 795 MON_StatMngr_2ndFuelEfficiency "This value only use for ATCU Library data monitoring (Only use before SOP)";
BA_ "GenSigSendType" SG_ 795 MON_StatMngr_2ndFuelEfficiency 4;
BA_ "UserSigValidity" SG_ 795 MON_StatMngr_2ndFuelEfficiency 0;
BA_REL_ "GenSigTimeoutTime" BU_SG_REL_ L_ATCU SG_ 795 MON_StatMngr_2ndFuelEfficiency 5000;
BA_ "Version" SG_ 795 MON_StatMngr_2ndFuelEfficiency "24.09.01";
VAL_ 36 L_ATCU_ArClnIntroEvt 0 "OFF" 1 "ON" ;
VAL_ 36 L_ATCU_ArClnSmblClr 0 "Default (Initial Value)" 1 "Mono Color" 2 "Blue Color" 3 "Green Color" 4 "Orange Color" 5 "Red Color" 6 "Yellow Color" 7 "RESERVED" 8 "RESERVED" 9 "RESERVED" 10 "RESERVED" 11 "RESERVED" 12 "RESERVED" 13 "RESERVED" 14 "Gray Color (Deactivate)" 15 "Invalid" ;
VAL_ 36 L_ATCU_DustLevelDis 0 "Sensor Fail" 1 "Good" 2 "Normal" 3 "Bad" 4 "Very Bad" 5 "RESERVED" 6 "Loading(Init or StandBy)" 7 "Error Indicator" ;
VAL_ 36 L_ATCU_DustBarDisOff 0 "False(Symbol ON)" 1 "True(Symbol OFF)" ;
VAL_ 36 L_ATCU_DustSnrStepDis 0 "default" 1 "0step" 2 "1step" 3 "2step" 4 "3step" 5 "4step" 6 "5step" 7 "6step" 8 "7step" 9 "8step" 10 "9step" 11 "10step" 12 "11step" 13 "12step" 14 "13step" 15 "14step" 16 "15step" 17 "16step" ;
VAL_ 36 L_ATCU_FragStrhDis 0 "OFF" 1 "1st(Low)" 2 "1st&2nd(Mid)" 3 "1st&2nd&3rd(High)" ;
VAL_ 36 L_ATCU_FragKindDis 0 "Default" 1 "First" 2 "Second" 3 "RESERVED" 4 "RESERVED" 5 "RESERVED" 6 "None" 7 "Error Indicator" ;
VAL_ 36 L_ATCU_Frag1Inform 0 "Default" 1 "THE DRIVER'S AWAKENING" 2 "MY FAVORITE PLACE" 3 "THE GREAT OUTDOORS" 4 "The Hidden Core" 5 "Arabian Dusk" 6 "One of One" 7 "RESERVED" 8 "RESERVED" 9 "RESERVED" 10 "RESERVED" 11 "RESERVED" 12 "New Fragrance Mounted" 13 "No Cartridge Mounted" 14 "Unknown Cartridge Monuted" 15 "Error Indicator" ;
VAL_ 36 L_ATCU_Frag2Inform 4 "The Hidden Core" 5 "Arabian Dusk" 6 "One of One" 0 "Default" 1 "THE DRIVER'S AWAKENING" 2 "MY FAVORITE PLACE" 3 "THE GREAT OUTDOORS" 7 "RESERVED" 8 "RESERVED" 9 "RESERVED" 10 "RESERVED" 11 "RESERVED" 12 "New Fragrance Mounted" 13 "No Cartridge Mounted" 14 "Unknown Cartridge Monuted" 15 "Error Indicator" ;
VAL_ 36 L_ATCU_Frag1RemainDisp 0 "Default" 1 "Remains 100% (70~100%)" 2 "Remains 70% (30~70%)" 3 "Remains 30% (0~30%)" 4 "Remains 0%" 5 "RESERVED" 6 "Unknown" 7 "Error Indicator" ;
VAL_ 36 L_ATCU_Frag2RemainDisp 0 "Default" 1 "Remains 100% (70~100%)" 2 "Remains 70% (30~70%)" 3 "Remains 30% (0~30%)" 4 "Remains 0%" 5 "RESERVED" 6 "Unknown" 7 "Error Indicator" ;
VAL_ 36 L_ATCU_ArClnSmblTyp 0 "Default" 1 "BLANK DISPLAY" 2 "Tree Only" 3 "Tree & Fixed Arrow" 4 "Tree & Rotating Arrow" ;
VAL_ 36 L_ATCU_FrtBlwMaxLvlVaild 0 "Invalid (Multi AUTO Not Applied)" 1 "Reversed" 2 "1 Level" 3 "2 Level" 4 "3 Level" 5 "4 Level" 6 "5 Level" 7 "6 Level" 8 "7 Level" 9 "8 Level" 10 "Not used" 11 "Not used" 12 "Not used" 13 "Not used" 14 "Not used" 15 "Error Indicator" ;
VAL_ 36 L_ATCU_OpSta 0 "DATC Off (Power Down)" 1 "DATC Normal" 2 "DATC System Off (Blower Off)" 3 "DATC Self Diagnosis" 4 "Version Display" 5 "Not used" 6 "Not used" 7 "Error Indicator" ;
VAL_ 36 L_ATCU_TempDispUnit 0 "Centigrade(¡É)" 1 "Fahrenheit(¢µ)" 2 "Not used" 3 "Error Indicator" ;
VAL_ 36 L_ATCU_DrvAUTOStep 0 "Default" 1 "OFF" 2 "1st & 2nd & 3rd On (3 Step Type)" 3 "1st & 2nd On (3 Step Type)" 4 "1st On (3 Step Type)" 5 "1st & 2nd On (2 Step Type)" 6 "1st On (2 Step Type)" 7 "RESERVED" 8 "RESERVED" 9 "RESERVED" 10 "RESERVED" 11 "RESERVED" 12 "RESERVED" 13 "RESERVED" 14 "RESERVED" 15 "Error Indicator" ;
VAL_ 36 L_ATCU_DiagCodeDis 0 "Blank Display" 1023 "Error Indicator" ;
VAL_ 37 L_ATCU_RrOpSta 0 "DATC Off (Power Down)" 1 "DATC Normal" 2 "DATC System Off (Blower Off)" 3 "DATC Self Diagnosis" 4 "Not used" 5 "Not used" 6 "Not used" 7 "Error Indicator" ;
VAL_ 37 L_ATCU_RrDrvTempFDis 0 "Blank Display (Default)" 1 "'LO' Display" 2 "58¢µ~92¢µ" 3 "58¢µ~92¢µ" 4 "58¢µ~92¢µ" 5 "58¢µ~92¢µ" 6 "58¢µ~92¢µ" 7 "58¢µ~92¢µ" 8 "58¢µ~92¢µ" 9 "58¢µ~92¢µ" 10 "58¢µ~92¢µ" 11 "58¢µ~92¢µ" 12 "58¢µ~92¢µ" 13 "58¢µ~92¢µ" 14 "58¢µ~92¢µ" 15 "58¢µ~92¢µ" 16 "58¢µ~92¢µ" 17 "58¢µ~92¢µ" 18 "58¢µ~92¢µ" 19 "58¢µ~92¢µ" 20 "58¢µ~92¢µ" 21 "58¢µ~92¢µ" 22 "58¢µ~92¢µ" 23 "58¢µ~92¢µ" 24 "58¢µ~92¢µ" 25 "58¢µ~92¢µ" 26 "58¢µ~92¢µ" 27 "58¢µ~92¢µ" 28 "58¢µ~92¢µ" 29 "58¢µ~92¢µ" 30 "58¢µ~92¢µ" 31 "58¢µ~92¢µ" 32 "58¢µ~92¢µ" 33 "58¢µ~92¢µ" 34 "58¢µ~92¢µ" 35 "58¢µ~92¢µ" 36 "58¢µ~92¢µ" 37 "25~0xFD:RESERVED" 253 "25~0xFD:RESERVED" 254 "'HI' Display" 255 "Error Indicator" ;
VAL_ 37 L_ATCU_RrDrvModDis 0 "Off(Blank Display, Vent mode not Display ex) Auto" 1 "VENT" 2 "B_L" 3 "FLOOR" 4 "MIX" 5 "DEF(Including Max DEF)" 6 "AUTO DEFOG" 7 "Def (7 mode only)" 8 "DefVent(7 mode only)" 9 "DefFL(7 mode only)" 10 "VentFL(7 mode only)" 11 "DefVentFL(7 mode only)" 12 "Not used" 13 "Not used" 14 "Not used" 15 "Error Indicator" ;
VAL_ 37 L_ATCU_RrDrvBlwDis 0 "OFF(System Off)" 1 "Blank Display(Blower Level no display, ex)Auto mode)" 2 "1 Level" 3 "2 Level" 4 "3 Level" 5 "4 Level" 6 "5 Level" 7 "6 Level" 8 "7 Level" 9 "8 Level" 10 "Not used" 11 "Not used" 12 "Not used" 13 "Not used" 14 "Not used" 15 "Error Indicator" ;
VAL_ 37 L_ATCU_RrDrvAutoDis 0 "RrAUTO Off" 1 "RrAUTO On" 2 "Not used" 3 "Error Indicator" ;
VAL_ 37 L_ATCU_RrDrvMultiAutoBlwDis 0 "MultiAutoBlr Display Off" 1 "Multi Auto Blower Low" 2 "Multi Auto Blower Mid" 3 "Multi Auto Blower High" ;
VAL_ 37 L_ATCU_RrDrvTempCDis 0 "Blank Display (Default)" 1 "'LO' Display" 2 "15.0¡É~32.0¡É" 3 "15.0¡É~32.0¡É" 4 "15.0¡É~32.0¡É" 5 "15.0¡É~32.0¡É" 6 "15.0¡É~32.0¡É" 7 "15.0¡É~32.0¡É" 8 "15.0¡É~32.0¡É" 9 "15.0¡É~32.0¡É" 10 "15.0¡É~32.0¡É" 11 "15.0¡É~32.0¡É" 12 "15.0¡É~32.0¡É" 13 "15.0¡É~32.0¡É" 14 "15.0¡É~32.0¡É" 15 "15.0¡É~32.0¡É" 16 "15.0¡É~32.0¡É" 17 "15.0¡É~32.0¡É" 18 "15.0¡É~32.0¡É" 19 "15.0¡É~32.0¡É" 20 "15.0¡É~32.0¡É" 21 "15.0¡É~32.0¡É" 22 "15.0¡É~32.0¡É" 23 "15.0¡É~32.0¡É" 24 "15.0¡É~32.0¡É" 25 "15.0¡É~32.0¡É" 26 "15.0¡É~32.0¡É" 27 "15.0¡É~32.0¡É" 28 "15.0¡É~32.0¡É" 29 "15.0¡É~32.0¡É" 30 "15.0¡É~32.0¡É" 31 "15.0¡É~32.0¡É" 32 "15.0¡É~32.0¡É" 33 "15.0¡É~32.0¡É" 34 "15.0¡É~32.0¡É" 35 "15.0¡É~32.0¡É" 36 "15.0¡É~32.0¡É" 37 "25~0xFD:RESERVED" 253 "25~0xFD:RESERVED" 254 "'HI' Display" 255 "Error Indicator" ;
VAL_ 37 L_ATCU_RrSyncDis 0 "RrSYNC Off" 1 "RrSYNC On" 2 "Not used" 3 "Error Indicator" ;
VAL_ 37 L_ATCU_RrLcdBckLightSta 0 "OFF" 1 "ON" ;
VAL_ 37 L_ATCU_RrGUIBlankDis 0 "OFF" 1 "ON" ;
VAL_ 37 L_ATCU_RLStHeatSwHInd 0 "OFF" 1 "ON" ;
VAL_ 37 L_ATCU_RLStHeatSwMInd 0 "OFF" 1 "ON" ;
VAL_ 37 L_ATCU_RLStHeatSwLInd 0 "OFF" 1 "ON" ;
VAL_ 37 L_ATCU_RLStVntSwHInd 0 "OFF" 1 "ON" ;
VAL_ 37 L_ATCU_RLStVntSwMInd 0 "OFF" 1 "ON" ;
VAL_ 37 L_ATCU_RLStVntSwLInd 0 "OFF" 1 "ON" ;
VAL_ 37 L_ATCU_RRStHeatSwHInd 0 "OFF" 1 "ON" ;
VAL_ 37 L_ATCU_RRStHeatSwMInd 0 "OFF" 1 "ON" ;
VAL_ 37 L_ATCU_RRStHeatSwLInd 0 "OFF" 1 "ON" ;
VAL_ 37 L_ATCU_RRStVntSwHInd 0 "OFF" 1 "ON" ;
VAL_ 37 L_ATCU_RRStVntSwMInd 0 "OFF" 1 "ON" ;
VAL_ 37 L_ATCU_RRStVntSwLInd 0 "OFF" 1 "ON" ;
VAL_ 37 L_ATCU_RrMTCOpSta 0 "DATC Off (Power Down)" 1 "DATC Normal" 2 "DATC System Off (Blower Off)" 3 "Error Indicator" ;
VAL_ 37 L_ATCU_RrMTCTempLvl 0 "Off" 1 "Level 1" 2 "Level 2" 3 "Level 3" 4 "Level 4" 5 "Level 5" 6 "Level 6" 7 "Level 7" 8 "Level 8" ;
VAL_ 37 L_ATCU_RrPsModDis 0 "Off(Blank Display, Vent mode not Display ex) Auto" 1 "VENT" 2 "B_L" 3 "FLOOR" 4 "MIX" 5 "DEF(Including Max DEF)" 6 "AUTO DEFOG" 7 "Def (7 mode only)" 8 "DefVent(7 mode only)" 9 "DefFL(7 mode only)" 10 "VentFL(7 mode only)" 11 "DefVentFL(7 mode only)" 12 "Not used" 13 "Not used" 14 "Not used" 15 "Error Indicator" ;
VAL_ 37 L_ATCU_RrLockDis 0 "RearLock Off" 1 "RearLock On" 2 "Not Used" 3 "Error Indicator" ;
VAL_ 37 L_ATCU_RrDrvAutoStep 0 "Default" 1 "OFF" 2 "1st & 2nd & 3rd On (3 Step Type)" 3 "1st & 2nd On (3 Step Type)" 4 "1st On (3 Step Type)" 5 "1st & 2nd On (2 Step Type)" 6 "1st On (2 Step Type)" 7 "RESERVED" 8 "RESERVED" 9 "RESERVED" 10 "RESERVED" 11 "RESERVED" 12 "RESERVED" 13 "RESERVED" 14 "RESERVED" 15 "Error Indicator" ;
VAL_ 40 L_ATCU_PassAUTOStep 0 "Default" 1 "OFF" 2 "1st & 2nd & 3rd On (3 Step Type)" 3 "1st & 2nd On (3 Step Type)" 4 "1st On (3 Step Type)" 5 "1st & 2nd On (2 Step Type)" 6 "1st On (2 Step Type)" 7 "Error Indicator" ;
VAL_ 40 L_ATCU_RrPassTempFDis 0 "Blank Display(Default)" 1 "'LO' Display" 2 "58¢µ~32¢µ" 3 "58¢µ~32¢µ" 4 "58¢µ~32¢µ" 5 "58¢µ~32¢µ" 6 "58¢µ~32¢µ" 7 "58¢µ~32¢µ" 8 "58¢µ~32¢µ" 9 "58¢µ~32¢µ" 10 "58¢µ~32¢µ" 11 "58¢µ~32¢µ" 12 "58¢µ~32¢µ" 13 "58¢µ~32¢µ" 14 "58¢µ~32¢µ" 15 "58¢µ~32¢µ" 16 "58¢µ~32¢µ" 17 "58¢µ~32¢µ" 18 "58¢µ~32¢µ" 19 "58¢µ~32¢µ" 20 "58¢µ~32¢µ" 21 "58¢µ~32¢µ" 22 "58¢µ~32¢µ" 23 "58¢µ~32¢µ" 24 "58¢µ~32¢µ" 25 "58¢µ~32¢µ" 26 "58¢µ~32¢µ" 27 "58¢µ~32¢µ" 28 "58¢µ~32¢µ" 29 "58¢µ~32¢µ" 30 "58¢µ~32¢µ" 31 "58¢µ~32¢µ" 32 "58¢µ~32¢µ" 33 "58¢µ~32¢µ" 34 "58¢µ~32¢µ" 35 "58¢µ~32¢µ" 36 "58¢µ~32¢µ" 37 "25~0xFD:RESERVED" 253 "25~0xFD:RESERVED" 254 "'HI' Display" 255 "Error Indicator" ;
VAL_ 40 L_ATCU_RrPassBlwDis 0 "OFF(Default)" 1 "Blank Display(Blower level not display, ex)Auto mode)" 2 "1 Step" 3 "2 Step" 4 "3 Step" 5 "4 Step" 6 "5 Step" 7 "6 Step" 8 "7 Step" 9 "8 Step" 10 "BLOWER AUTO" 11 "RESERVED" 12 "RESERVED" 13 "RESERVED" 14 "RESERVED" 15 "Error Indicator" ;
VAL_ 40 L_ATCU_RrPassAUTODis 0 "PsAUTO Off" 1 "PsAUTO On" 2 "Not used" 3 "Error Indicator" ;
VAL_ 40 L_ATCU_RrPassAUTOStep 0 "Default" 1 "OFF" 2 "1st & 2nd & 3rd On (3 Step Type)" 3 "1st & 2nd On (3 Step Type)" 4 "1st On (3 Step Type)" 5 "1st & 2nd On (2 Step Type)" 6 "1st On (2 Step Type)" 7 "Error Indicator" ;
VAL_ 40 L_ATCU_CampModeSta 0 "Default" 1 "Off" 2 "On" 3 "Invalid" ;
VAL_ 40 L_ATCU_RrPassTempCDis 0 "Blank Display(Default)" 1 "'LO' Display" 2 "15.0¡É~32.0¡É" 3 "15.0¡É~32.0¡É" 4 "15.0¡É~32.0¡É" 5 "15.0¡É~32.0¡É" 6 "15.0¡É~32.0¡É" 7 "15.0¡É~32.0¡É" 8 "15.0¡É~32.0¡É" 9 "15.0¡É~32.0¡É" 10 "15.0¡É~32.0¡É" 11 "15.0¡É~32.0¡É" 12 "15.0¡É~32.0¡É" 13 "15.0¡É~32.0¡É" 14 "15.0¡É~32.0¡É" 15 "15.0¡É~32.0¡É" 16 "15.0¡É~32.0¡É" 17 "15.0¡É~32.0¡É" 18 "15.0¡É~32.0¡É" 19 "15.0¡É~32.0¡É" 20 "15.0¡É~32.0¡É" 21 "15.0¡É~32.0¡É" 22 "15.0¡É~32.0¡É" 23 "15.0¡É~32.0¡É" 24 "15.0¡É~32.0¡É" 25 "15.0¡É~32.0¡É" 26 "15.0¡É~32.0¡É" 27 "15.0¡É~32.0¡É" 28 "15.0¡É~32.0¡É" 29 "15.0¡É~32.0¡É" 30 "15.0¡É~32.0¡É" 31 "15.0¡É~32.0¡É" 32 "15.0¡É~32.0¡É" 33 "15.0¡É~32.0¡É" 34 "15.0¡É~32.0¡É" 35 "15.0¡É~32.0¡É" 36 "15.0¡É~32.0¡É" 37 "25~0xFD:RESERVED" 253 "25~0xFD:RESERVED" 254 "'HI' Display" 255 "Error Indicator" ;
VAL_ 40 L_ATCU_UtilModeUsmSta 0 "Disable" 1 "Rest Mode Off" 2 "Rest Mode On" 3 "Invalid" ;
VAL_ 40 L_ATCU_RrAcDis 0 "AC OFF" 1 "AC ON" 2 "Not used" 3 "Error Indicator" ;
VAL_ 40 L_ATCU_3rdAcDis 0 "AC Off" 1 "AC ON" 2 "Not used" 3 "Error Indicator" ;
VAL_ 40 L_ATCU_ValetModeSta 0 "Default" 1 "Off" 2 "On" 3 "Invalid" ;
VAL_ 40 L_ATCU_FrSysOnOffDis 0 "Default" 1 "Off" 2 "On" 3 "Error Indicator" ;
VAL_ 40 L_ATCU_RrSysOnOffDis 0 "Default" 1 "Off" 2 "On" 3 "Error Indicator" ;
VAL_ 40 L_ATCU_3rdSysOnOffDis 0 "Default" 1 "Off" 2 "On" 3 "Error Indicator" ;
VAL_ 40 L_ATCU_RrCurtainPosition 0 "None" 1 "Down0x2:Mid" 3 "Up" ;
VAL_ 40 L_ATCU_SafetyModeSta 0 "Off(Default)" 1 "On" 2 "RESERVED" 3 "RESERVED" ;
VAL_ 41 L_ATCU_OutTempDispC 0 "Default" 1 "Not Used" 2 "02~0xCA:-40¡É~60¡É" 202 "02~0xCA:-40¡É~60¡É" 203 "RESERVED" 204 "RESERVED" 205 "RESERVED" 206 "RESERVED" 207 "RESERVED" 208 "RESERVED" 209 "RESERVED" 210 "RESERVED" 211 "RESERVED" 212 "RESERVED" 213 "RESERVED" 214 "RESERVED" 215 "RESERVED" 216 "RESERVED" 217 "RESERVED" 218 "RESERVED" 219 "RESERVED" 220 "RESERVED" 221 "RESERVED" 222 "RESERVED" 223 "RESERVED" 224 "RESERVED" 225 "RESERVED" 226 "RESERVED" 227 "RESERVED" 228 "RESERVED" 229 "RESERVED" 230 "RESERVED" 231 "RESERVED" 232 "RESERVED" 233 "RESERVED" 234 "RESERVED" 235 "RESERVED" 236 "RESERVED" 237 "RESERVED" 238 "RESERVED" 239 "RESERVED" 240 "RESERVED" 241 "RESERVED" 242 "RESERVED" 243 "RESERVED" 244 "RESERVED" 245 "RESERVED" 246 "RESERVED" 247 "RESERVED" 248 "RESERVED" 249 "RESERVED" 250 "RESERVED" 251 "RESERVED" 252 "RESERVED" 253 "RESERVED" 254 "Sensor Fail (--Display)" 255 "Invalid" ;
VAL_ 41 L_ATCU_DtntOutSta 0 "Detent Off" 1 "Detent On" ;
VAL_ 41 L_ATCU_AutoBrightSta 0 "RESERVED" 1 "01~0xC8:Bright State (1~200 Step)" 200 "01~0xC8:Bright State (1~200 Step)" 201 "RESERVED" 202 "RESERVED" 203 "RESERVED" 204 "RESERVED" 205 "RESERVED" 206 "RESERVED" 207 "RESERVED" 208 "RESERVED" 209 "RESERVED" 210 "RESERVED" 211 "RESERVED" 212 "RESERVED" 213 "RESERVED" 214 "RESERVED" 215 "RESERVED" 216 "RESERVED" 217 "RESERVED" 218 "RESERVED" 219 "RESERVED" 220 "RESERVED" 221 "RESERVED" 222 "RESERVED" 223 "RESERVED" 224 "RESERVED" 225 "RESERVED" 226 "RESERVED" 227 "RESERVED" 228 "RESERVED" 229 "RESERVED" 230 "RESERVED" 231 "RESERVED" 232 "RESERVED" 233 "RESERVED" 234 "RESERVED" 235 "RESERVED" 236 "RESERVED" 237 "RESERVED" 238 "RESERVED" 239 "RESERVED" 240 "RESERVED" 241 "RESERVED" 242 "RESERVED" 243 "RESERVED" 244 "RESERVED" 245 "RESERVED" 246 "RESERVED" 247 "RESERVED" 248 "RESERVED" 249 "RESERVED" 250 "RESERVED" 251 "RESERVED" 252 "RESERVED" 253 "RESERVED" 254 "RESERVED" 255 "RESERVED" ;
VAL_ 41 L_ATCU_DustSnrVal 1021 "Standby" 1022 "Init" 1023 "RESERVED" ;
VAL_ 41 L_ATCU_NotMinModeBrightSta 0 "RESERVED (Not Used)" 1 "01~0xC8:Bright State(1~200 Step)" 200 "01~0xC8:Bright State(1~200 Step)" ;
VAL_ 41 L_ATCU_IAUPrfleVal 0 "Default" 1 "Guest" 2 "Profile 1" 3 "Profile 2" 4 "Profile 3" 5 "Profile 4" 6 "Profile 5" 7 "Proflie 6" 8 "Profile 7" 9 "Profile 8" 10 "Profile 9" 11 "RESERVED" 12 "RESERVED" 13 "RESERVED" 14 "RESERVED" 15 "Invalid" ;
VAL_ 41 L_ATCU_AVNPrfleVal 0 "Default" 1 "Guest" 2 "Profile 1" 3 "Profile 2" 4 "Profile 3" 5 "Profile 4" 6 "Profile 5" 7 "Profile 6" 8 "Profile 7" 9 "Profile 8" 10 "Profile 9" 11 "RESERVED" 12 "RESERVED" 13 "RESERVED" 14 "RESERVED" 15 "Invalid" ;
VAL_ 41 L_ATCU_SchdldClimateSta 0 "Default" 1 "Deactivated" 2 "Activated" 3 "Invalid" ;
VAL_ 41 L_ATCU_SchedRmtFcn_OpSta 0 "None" 1 "Monitoring Mode(by AVN)" 2 "Normal Charge Mode (by VCMS)" 2 "Normal Charge Mode (by VCMS)" 3 "Prog/Imme Charge Or Prog Charge Wait Mode (by VCU/AVNT/VCMS)" 4 ":Prog Aircon and SOC Sustaining Mode(by VCU)" 5 "Prog/Imme Aircon Mode and Prog/Imme Charge Mode (by VCU/AVNT/VCMS)" 6 "RESERVED" 7 "Prog/Imme Aircon Mode and Normal Charge Mode (by VCU/AVNT)" 8 "Imme Aircon Only Mode (by AVNT)" 9 "Aux Battery Charge Mode" 10 "Abnormal Stop Mode during Prog/Imme Charge/Aircon" 11 "RESERVED" 12 "RESERVED" 13 "RESERVED" 14 "RESERVED" 15 "RESERVED" ;
VAL_ 41 L_ATCU_AirconCtrReq 0 "Deativatie Remote Air Conditioner Control" 1 "Activate Remote Air Condtioner Control" 2 "Not used" 3 "Error Indicator" ;
VAL_ 41 L_ATCU_OutTempDispF 0 "Default" 1 "Not Used" 2 "02~0xCA:-40¢µ~160¢µ" 202 "02~0xCA:-40¢µ~160¢µ" 203 "RESERVED" 204 "RESERVED" 205 "RESERVED" 206 "RESERVED" 207 "RESERVED" 208 "RESERVED" 209 "RESERVED" 210 "RESERVED" 211 "RESERVED" 212 "RESERVED" 213 "RESERVED" 214 "RESERVED" 215 "RESERVED" 216 "RESERVED" 217 "RESERVED" 218 "RESERVED" 219 "RESERVED" 220 "RESERVED" 221 "RESERVED" 222 "RESERVED" 223 "RESERVED" 224 "RESERVED" 225 "RESERVED" 226 "RESERVED" 227 "RESERVED" 228 "RESERVED" 229 "RESERVED" 230 "RESERVED" 231 "RESERVED" 232 "RESERVED" 233 "RESERVED" 234 "RESERVED" 235 "RESERVED" 236 "RESERVED" 237 "RESERVED" 238 "RESERVED" 239 "RESERVED" 240 "RESERVED" 241 "RESERVED" 242 "RESERVED" 243 "RESERVED" 244 "RESERVED" 245 "RESERVED" 246 "RESERVED" 247 "RESERVED" 248 "RESERVED" 249 "RESERVED" 250 "RESERVED" 251 "RESERVED" 252 "RESERVED" 253 "RESERVED" 254 "Sensor Fail (--Display)" 255 "Invalid" ;
VAL_ 48 L_ATCU_SW_Ver1 0 "0x00~0x7E:ASCII value" 126 "0x00~0x7E:ASCII value" 127 "Invalid" ;
VAL_ 48 L_ATCU_SW_Ver3 0 "0x00~0x7E:ASCII value" 126 "0x00~0x7E:ASCII value" 127 "Invalid" ;
VAL_ 48 L_ATCU_SW_Ver4 0 "0x00~0x7E:ASCII value" 126 "0x00~0x7E:ASCII value" 127 "Invalid" ;
VAL_ 48 L_ATCU_SW_Ver5 0 "0x00~0x7E:ASCII value" 126 "0x00~0x7E:ASCII value" 127 "Invalid" ;
VAL_ 48 L_ATCU_SW_Ver2 0 "0x00~0x7E:ASCII value" 126 "0x00~0x7E:ASCII value" 127 "Invalid" ;
VAL_ 49 L_ATCU_ResetPreWrngForOthers 0 "No Warning" 1 "Warning" 2 "RESERVED" 3 "Invalid" ;
VAL_ 49 L_ATCU_ResetReqForOthers 0 "No Request" 1 "Reset Request" 2 "RESERVED" 3 "Invalid" ;
VAL_ 290 L_ATCU_HU_FrDrEVntSideBdryUp_X 0 "Default" 1 "01~0xC0:PHY=HEX*10 + 0" 192 "01~0xC0:PHY=HEX*10 + 0" 193 "RESERVED" 194 "RESERVED" 195 "RESERVED" 196 "RESERVED" 197 "RESERVED" 198 "RESERVED" 199 "RESERVED" 200 "RESERVED" 201 "RESERVED" 202 "RESERVED" 203 "RESERVED" 204 "RESERVED" 205 "RESERVED" 206 "RESERVED" 207 "RESERVED" 208 "RESERVED" 209 "RESERVED" 210 "RESERVED" 211 "RESERVED" 212 "RESERVED" 213 "RESERVED" 214 "RESERVED" 215 "RESERVED" 216 "RESERVED" 217 "RESERVED" 218 "RESERVED" 219 "RESERVED" 220 "RESERVED" 221 "RESERVED" 222 "RESERVED" 223 "RESERVED" 224 "RESERVED" 225 "RESERVED" 226 "RESERVED" 227 "RESERVED" 228 "RESERVED" 229 "RESERVED" 230 "RESERVED" 231 "RESERVED" 232 "RESERVED" 233 "RESERVED" 234 "RESERVED" 235 "RESERVED" 236 "RESERVED" 237 "RESERVED" 238 "RESERVED" 239 "RESERVED" 240 "RESERVED" 241 "RESERVED" 242 "RESERVED" 243 "RESERVED" 244 "RESERVED" 245 "RESERVED" 246 "RESERVED" 247 "RESERVED" 248 "RESERVED" 249 "RESERVED" 250 "RESERVED" 251 "RESERVED" 252 "RESERVED" 253 "RESERVED" 254 "RESERVED" 255 "Invalid" ;
VAL_ 290 L_ATCU_HU_FrDrEVntSideBdryLo_X 0 "Default" 1 "01~0xC0:PHY=HEX*10 + 0" 192 "01~0xC0:PHY=HEX*10 + 0" 193 "RESERVED" 194 "RESERVED" 195 "RESERVED" 196 "RESERVED" 197 "RESERVED" 198 "RESERVED" 199 "RESERVED" 200 "RESERVED" 201 "RESERVED" 202 "RESERVED" 203 "RESERVED" 204 "RESERVED" 205 "RESERVED" 206 "RESERVED" 207 "RESERVED" 208 "RESERVED" 209 "RESERVED" 210 "RESERVED" 211 "RESERVED" 212 "RESERVED" 213 "RESERVED" 214 "RESERVED" 215 "RESERVED" 216 "RESERVED" 217 "RESERVED" 218 "RESERVED" 219 "RESERVED" 220 "RESERVED" 221 "RESERVED" 222 "RESERVED" 223 "RESERVED" 224 "RESERVED" 225 "RESERVED" 226 "RESERVED" 227 "RESERVED" 228 "RESERVED" 229 "RESERVED" 230 "RESERVED" 231 "RESERVED" 232 "RESERVED" 233 "RESERVED" 234 "RESERVED" 235 "RESERVED" 236 "RESERVED" 237 "RESERVED" 238 "RESERVED" 239 "RESERVED" 240 "RESERVED" 241 "RESERVED" 242 "RESERVED" 243 "RESERVED" 244 "RESERVED" 245 "RESERVED" 246 "RESERVED" 247 "RESERVED" 248 "RESERVED" 249 "RESERVED" 250 "RESERVED" 251 "RESERVED" 252 "RESERVED" 253 "RESERVED" 254 "RESERVED" 255 "Invalid" ;
VAL_ 290 L_ATCU_HU_FrDrEVntSideBdryLo_Y 0 "Default" 1 "01~0xC0:PHY=HEX*10 + 0" 192 "01~0xC0:PHY=HEX*10 + 0" 193 "RESERVED" 194 "RESERVED" 195 "RESERVED" 196 "RESERVED" 197 "RESERVED" 198 "RESERVED" 199 "RESERVED" 200 "RESERVED" 201 "RESERVED" 202 "RESERVED" 203 "RESERVED" 204 "RESERVED" 205 "RESERVED" 206 "RESERVED" 207 "RESERVED" 208 "RESERVED" 209 "RESERVED" 210 "RESERVED" 211 "RESERVED" 212 "RESERVED" 213 "RESERVED" 214 "RESERVED" 215 "RESERVED" 216 "RESERVED" 217 "RESERVED" 218 "RESERVED" 219 "RESERVED" 220 "RESERVED" 221 "RESERVED" 222 "RESERVED" 223 "RESERVED" 224 "RESERVED" 225 "RESERVED" 226 "RESERVED" 227 "RESERVED" 228 "RESERVED" 229 "RESERVED" 230 "RESERVED" 231 "RESERVED" 232 "RESERVED" 233 "RESERVED" 234 "RESERVED" 235 "RESERVED" 236 "RESERVED" 237 "RESERVED" 238 "RESERVED" 239 "RESERVED" 240 "RESERVED" 241 "RESERVED" 242 "RESERVED" 243 "RESERVED" 244 "RESERVED" 245 "RESERVED" 246 "RESERVED" 247 "RESERVED" 248 "RESERVED" 249 "RESERVED" 250 "RESERVED" 251 "RESERVED" 252 "RESERVED" 253 "RESERVED" 254 "RESERVED" 255 "Invalid" ;
VAL_ 290 L_ATCU_HU_FrDrEVntCtrBdryUp_X 0 "Default" 1 "01~0xC0:PHY=HEX*10 + 0" 192 "01~0xC0:PHY=HEX*10 + 0" 193 "RESERVED" 194 "RESERVED" 195 "RESERVED" 196 "RESERVED" 197 "RESERVED" 198 "RESERVED" 199 "RESERVED" 200 "RESERVED" 201 "RESERVED" 202 "RESERVED" 203 "RESERVED" 204 "RESERVED" 205 "RESERVED" 206 "RESERVED" 207 "RESERVED" 208 "RESERVED" 209 "RESERVED" 210 "RESERVED" 211 "RESERVED" 212 "RESERVED" 213 "RESERVED" 214 "RESERVED" 215 "RESERVED" 216 "RESERVED" 217 "RESERVED" 218 "RESERVED" 219 "RESERVED" 220 "RESERVED" 221 "RESERVED" 222 "RESERVED" 223 "RESERVED" 224 "RESERVED" 225 "RESERVED" 226 "RESERVED" 227 "RESERVED" 228 "RESERVED" 229 "RESERVED" 230 "RESERVED" 231 "RESERVED" 232 "RESERVED" 233 "RESERVED" 234 "RESERVED" 235 "RESERVED" 236 "RESERVED" 237 "RESERVED" 238 "RESERVED" 239 "RESERVED" 240 "RESERVED" 241 "RESERVED" 242 "RESERVED" 243 "RESERVED" 244 "RESERVED" 245 "RESERVED" 246 "RESERVED" 247 "RESERVED" 248 "RESERVED" 249 "RESERVED" 250 "RESERVED" 251 "RESERVED" 252 "RESERVED" 253 "RESERVED" 254 "RESERVED" 255 "Invalid" ;
VAL_ 290 L_ATCU_HU_FrDrEVntCtrBdryUp_Y 0 "Default" 1 "01~0xC0:PHY=HEX*10 + 0" 192 "01~0xC0:PHY=HEX*10 + 0" 193 "RESERVED" 194 "RESERVED" 195 "RESERVED" 196 "RESERVED" 197 "RESERVED" 198 "RESERVED" 199 "RESERVED" 200 "RESERVED" 201 "RESERVED" 202 "RESERVED" 203 "RESERVED" 204 "RESERVED" 205 "RESERVED" 206 "RESERVED" 207 "RESERVED" 208 "RESERVED" 209 "RESERVED" 210 "RESERVED" 211 "RESERVED" 212 "RESERVED" 213 "RESERVED" 214 "RESERVED" 215 "RESERVED" 216 "RESERVED" 217 "RESERVED" 218 "RESERVED" 219 "RESERVED" 220 "RESERVED" 221 "RESERVED" 222 "RESERVED" 223 "RESERVED" 224 "RESERVED" 225 "RESERVED" 226 "RESERVED" 227 "RESERVED" 228 "RESERVED" 229 "RESERVED" 230 "RESERVED" 231 "RESERVED" 232 "RESERVED" 233 "RESERVED" 234 "RESERVED" 235 "RESERVED" 236 "RESERVED" 237 "RESERVED" 238 "RESERVED" 239 "RESERVED" 240 "RESERVED" 241 "RESERVED" 242 "RESERVED" 243 "RESERVED" 244 "RESERVED" 245 "RESERVED" 246 "RESERVED" 247 "RESERVED" 248 "RESERVED" 249 "RESERVED" 250 "RESERVED" 251 "RESERVED" 252 "RESERVED" 253 "RESERVED" 254 "RESERVED" 255 "Invalid" ;
VAL_ 290 L_ATCU_HU_FrDrEVntCtrBdryLo_X 0 "Default" 1 "01~0xC0:PHY=HEX*10 + 0" 192 "01~0xC0:PHY=HEX*10 + 0" 193 "RESERVED" 194 "RESERVED" 195 "RESERVED" 196 "RESERVED" 197 "RESERVED" 198 "RESERVED" 199 "RESERVED" 200 "RESERVED" 201 "RESERVED" 202 "RESERVED" 203 "RESERVED" 204 "RESERVED" 205 "RESERVED" 206 "RESERVED" 207 "RESERVED" 208 "RESERVED" 209 "RESERVED" 210 "RESERVED" 211 "RESERVED" 212 "RESERVED" 213 "RESERVED" 214 "RESERVED" 215 "RESERVED" 216 "RESERVED" 217 "RESERVED" 218 "RESERVED" 219 "RESERVED" 220 "RESERVED" 221 "RESERVED" 222 "RESERVED" 223 "RESERVED" 224 "RESERVED" 225 "RESERVED" 226 "RESERVED" 227 "RESERVED" 228 "RESERVED" 229 "RESERVED" 230 "RESERVED" 231 "RESERVED" 232 "RESERVED" 233 "RESERVED" 234 "RESERVED" 235 "RESERVED" 236 "RESERVED" 237 "RESERVED" 238 "RESERVED" 239 "RESERVED" 240 "RESERVED" 241 "RESERVED" 242 "RESERVED" 243 "RESERVED" 244 "RESERVED" 245 "RESERVED" 246 "RESERVED" 247 "RESERVED" 248 "RESERVED" 249 "RESERVED" 250 "RESERVED" 251 "RESERVED" 252 "RESERVED" 253 "RESERVED" 254 "RESERVED" 255 "Invalid" ;
VAL_ 290 L_ATCU_HU_FrDrEVntCtrBdryLo_Y 0 "Default" 1 "01~0xC0:PHY=HEX*10 + 0" 192 "01~0xC0:PHY=HEX*10 + 0" 193 "RESERVED" 194 "RESERVED" 195 "RESERVED" 196 "RESERVED" 197 "RESERVED" 198 "RESERVED" 199 "RESERVED" 200 "RESERVED" 201 "RESERVED" 202 "RESERVED" 203 "RESERVED" 204 "RESERVED" 205 "RESERVED" 206 "RESERVED" 207 "RESERVED" 208 "RESERVED" 209 "RESERVED" 210 "RESERVED" 211 "RESERVED" 212 "RESERVED" 213 "RESERVED" 214 "RESERVED" 215 "RESERVED" 216 "RESERVED" 217 "RESERVED" 218 "RESERVED" 219 "RESERVED" 220 "RESERVED" 221 "RESERVED" 222 "RESERVED" 223 "RESERVED" 224 "RESERVED" 225 "RESERVED" 226 "RESERVED" 227 "RESERVED" 228 "RESERVED" 229 "RESERVED" 230 "RESERVED" 231 "RESERVED" 232 "RESERVED" 233 "RESERVED" 234 "RESERVED" 235 "RESERVED" 236 "RESERVED" 237 "RESERVED" 238 "RESERVED" 239 "RESERVED" 240 "RESERVED" 241 "RESERVED" 242 "RESERVED" 243 "RESERVED" 244 "RESERVED" 245 "RESERVED" 246 "RESERVED" 247 "RESERVED" 248 "RESERVED" 249 "RESERVED" 250 "RESERVED" 251 "RESERVED" 252 "RESERVED" 253 "RESERVED" 254 "RESERVED" 255 "Invalid" ;
VAL_ 290 L_ATCU_HU_FrDrEVntSideBdryUp_Y 0 "Default" 1 "01~0xC0:PHY=HEX*10 + 0" 192 "01~0xC0:PHY=HEX*10 + 0" 193 "RESERVED" 194 "RESERVED" 195 "RESERVED" 196 "RESERVED" 197 "RESERVED" 198 "RESERVED" 199 "RESERVED" 200 "RESERVED" 201 "RESERVED" 202 "RESERVED" 203 "RESERVED" 204 "RESERVED" 205 "RESERVED" 206 "RESERVED" 207 "RESERVED" 208 "RESERVED" 209 "RESERVED" 210 "RESERVED" 211 "RESERVED" 212 "RESERVED" 213 "RESERVED" 214 "RESERVED" 215 "RESERVED" 216 "RESERVED" 217 "RESERVED" 218 "RESERVED" 219 "RESERVED" 220 "RESERVED" 221 "RESERVED" 222 "RESERVED" 223 "RESERVED" 224 "RESERVED" 225 "RESERVED" 226 "RESERVED" 227 "RESERVED" 228 "RESERVED" 229 "RESERVED" 230 "RESERVED" 231 "RESERVED" 232 "RESERVED" 233 "RESERVED" 234 "RESERVED" 235 "RESERVED" 236 "RESERVED" 237 "RESERVED" 238 "RESERVED" 239 "RESERVED" 240 "RESERVED" 241 "RESERVED" 242 "RESERVED" 243 "RESERVED" 244 "RESERVED" 245 "RESERVED" 246 "RESERVED" 247 "RESERVED" 248 "RESERVED" 249 "RESERVED" 250 "RESERVED" 251 "RESERVED" 252 "RESERVED" 253 "RESERVED" 254 "RESERVED" 255 "Invalid" ;
VAL_ 291 L_ATCU_HU_FrPsEVntSideBdryUp_X 0 "Default" 1 "01~0xC0:PHY=HEX*10 + 0" 192 "01~0xC0:PHY=HEX*10 + 0" 193 "RESERVED" 194 "RESERVED" 195 "RESERVED" 196 "RESERVED" 197 "RESERVED" 198 "RESERVED" 199 "RESERVED" 200 "RESERVED" 201 "RESERVED" 202 "RESERVED" 203 "RESERVED" 204 "RESERVED" 205 "RESERVED" 206 "RESERVED" 207 "RESERVED" 208 "RESERVED" 209 "RESERVED" 210 "RESERVED" 211 "RESERVED" 212 "RESERVED" 213 "RESERVED" 214 "RESERVED" 215 "RESERVED" 216 "RESERVED" 217 "RESERVED" 218 "RESERVED" 219 "RESERVED" 220 "RESERVED" 221 "RESERVED" 222 "RESERVED" 223 "RESERVED" 224 "RESERVED" 225 "RESERVED" 226 "RESERVED" 227 "RESERVED" 228 "RESERVED" 229 "RESERVED" 230 "RESERVED" 231 "RESERVED" 232 "RESERVED" 233 "RESERVED" 234 "RESERVED" 235 "RESERVED" 236 "RESERVED" 237 "RESERVED" 238 "RESERVED" 239 "RESERVED" 240 "RESERVED" 241 "RESERVED" 242 "RESERVED" 243 "RESERVED" 244 "RESERVED" 245 "RESERVED" 246 "RESERVED" 247 "RESERVED" 248 "RESERVED" 249 "RESERVED" 250 "RESERVED" 251 "RESERVED" 252 "RESERVED" 253 "RESERVED" 254 "RESERVED" 255 "Invalid" ;
VAL_ 291 L_ATCU_HU_FrPsEVntSideBdryLo_X 0 "Default" 1 "01~0xC0:PHY=HEX*10 + 0" 192 "01~0xC0:PHY=HEX*10 + 0" 193 "RESERVED" 194 "RESERVED" 195 "RESERVED" 196 "RESERVED" 197 "RESERVED" 198 "RESERVED" 199 "RESERVED" 200 "RESERVED" 201 "RESERVED" 202 "RESERVED" 203 "RESERVED" 204 "RESERVED" 205 "RESERVED" 206 "RESERVED" 207 "RESERVED" 208 "RESERVED" 209 "RESERVED" 210 "RESERVED" 211 "RESERVED" 212 "RESERVED" 213 "RESERVED" 214 "RESERVED" 215 "RESERVED" 216 "RESERVED" 217 "RESERVED" 218 "RESERVED" 219 "RESERVED" 220 "RESERVED" 221 "RESERVED" 222 "RESERVED" 223 "RESERVED" 224 "RESERVED" 225 "RESERVED" 226 "RESERVED" 227 "RESERVED" 228 "RESERVED" 229 "RESERVED" 230 "RESERVED" 231 "RESERVED" 232 "RESERVED" 233 "RESERVED" 234 "RESERVED" 235 "RESERVED" 236 "RESERVED" 237 "RESERVED" 238 "RESERVED" 239 "RESERVED" 240 "RESERVED" 241 "RESERVED" 242 "RESERVED" 243 "RESERVED" 244 "RESERVED" 245 "RESERVED" 246 "RESERVED" 247 "RESERVED" 248 "RESERVED" 249 "RESERVED" 250 "RESERVED" 251 "RESERVED" 252 "RESERVED" 253 "RESERVED" 254 "RESERVED" 255 "Invalid" ;
VAL_ 291 L_ATCU_HU_FrPsEVntSideBdryLo_Y 0 "Default" 1 "01~0xC0:PHY=HEX*10 + 0" 192 "01~0xC0:PHY=HEX*10 + 0" 193 "RESERVED" 194 "RESERVED" 195 "RESERVED" 196 "RESERVED" 197 "RESERVED" 198 "RESERVED" 199 "RESERVED" 200 "RESERVED" 201 "RESERVED" 202 "RESERVED" 203 "RESERVED" 204 "RESERVED" 205 "RESERVED" 206 "RESERVED" 207 "RESERVED" 208 "RESERVED" 209 "RESERVED" 210 "RESERVED" 211 "RESERVED" 212 "RESERVED" 213 "RESERVED" 214 "RESERVED" 215 "RESERVED" 216 "RESERVED" 217 "RESERVED" 218 "RESERVED" 219 "RESERVED" 220 "RESERVED" 221 "RESERVED" 222 "RESERVED" 223 "RESERVED" 224 "RESERVED" 225 "RESERVED" 226 "RESERVED" 227 "RESERVED" 228 "RESERVED" 229 "RESERVED" 230 "RESERVED" 231 "RESERVED" 232 "RESERVED" 233 "RESERVED" 234 "RESERVED" 235 "RESERVED" 236 "RESERVED" 237 "RESERVED" 238 "RESERVED" 239 "RESERVED" 240 "RESERVED" 241 "RESERVED" 242 "RESERVED" 243 "RESERVED" 244 "RESERVED" 245 "RESERVED" 246 "RESERVED" 247 "RESERVED" 248 "RESERVED" 249 "RESERVED" 250 "RESERVED" 251 "RESERVED" 252 "RESERVED" 253 "RESERVED" 254 "RESERVED" 255 "Invalid" ;
VAL_ 291 L_ATCU_HU_FrPsEVntCtrBdryUp_X 0 "Default" 1 "01~0xC0:PHY=HEX*10 + 0" 192 "01~0xC0:PHY=HEX*10 + 0" 193 "RESERVED" 194 "RESERVED" 195 "RESERVED" 196 "RESERVED" 197 "RESERVED" 198 "RESERVED" 199 "RESERVED" 200 "RESERVED" 201 "RESERVED" 202 "RESERVED" 203 "RESERVED" 204 "RESERVED" 205 "RESERVED" 206 "RESERVED" 207 "RESERVED" 208 "RESERVED" 209 "RESERVED" 210 "RESERVED" 211 "RESERVED" 212 "RESERVED" 213 "RESERVED" 214 "RESERVED" 215 "RESERVED" 216 "RESERVED" 217 "RESERVED" 218 "RESERVED" 219 "RESERVED" 220 "RESERVED" 221 "RESERVED" 222 "RESERVED" 223 "RESERVED" 224 "RESERVED" 225 "RESERVED" 226 "RESERVED" 227 "RESERVED" 228 "RESERVED" 229 "RESERVED" 230 "RESERVED" 231 "RESERVED" 232 "RESERVED" 233 "RESERVED" 234 "RESERVED" 235 "RESERVED" 236 "RESERVED" 237 "RESERVED" 238 "RESERVED" 239 "RESERVED" 240 "RESERVED" 241 "RESERVED" 242 "RESERVED" 243 "RESERVED" 244 "RESERVED" 245 "RESERVED" 246 "RESERVED" 247 "RESERVED" 248 "RESERVED" 249 "RESERVED" 250 "RESERVED" 251 "RESERVED" 252 "RESERVED" 253 "RESERVED" 254 "RESERVED" 255 "Invalid" ;
VAL_ 291 L_ATCU_HU_FrPsEVntCtrBdryUp_Y 0 "Default" 1 "01~0xC0:PHY=HEX*10 + 0" 192 "01~0xC0:PHY=HEX*10 + 0" 193 "RESERVED" 194 "RESERVED" 195 "RESERVED" 196 "RESERVED" 197 "RESERVED" 198 "RESERVED" 199 "RESERVED" 200 "RESERVED" 201 "RESERVED" 202 "RESERVED" 203 "RESERVED" 204 "RESERVED" 205 "RESERVED" 206 "RESERVED" 207 "RESERVED" 208 "RESERVED" 209 "RESERVED" 210 "RESERVED" 211 "RESERVED" 212 "RESERVED" 213 "RESERVED" 214 "RESERVED" 215 "RESERVED" 216 "RESERVED" 217 "RESERVED" 218 "RESERVED" 219 "RESERVED" 220 "RESERVED" 221 "RESERVED" 222 "RESERVED" 223 "RESERVED" 224 "RESERVED" 225 "RESERVED" 226 "RESERVED" 227 "RESERVED" 228 "RESERVED" 229 "RESERVED" 230 "RESERVED" 231 "RESERVED" 232 "RESERVED" 233 "RESERVED" 234 "RESERVED" 235 "RESERVED" 236 "RESERVED" 237 "RESERVED" 238 "RESERVED" 239 "RESERVED" 240 "RESERVED" 241 "RESERVED" 242 "RESERVED" 243 "RESERVED" 244 "RESERVED" 245 "RESERVED" 246 "RESERVED" 247 "RESERVED" 248 "RESERVED" 249 "RESERVED" 250 "RESERVED" 251 "RESERVED" 252 "RESERVED" 253 "RESERVED" 254 "RESERVED" 255 "Invalid" ;
VAL_ 291 L_ATCU_HU_FrPsEVntCtrBdryLo_X 0 "Default" 1 "01~0xC0:PHY=HEX*10 + 0" 192 "01~0xC0:PHY=HEX*10 + 0" 193 "RESERVED" 194 "RESERVED" 195 "RESERVED" 196 "RESERVED" 197 "RESERVED" 198 "RESERVED" 199 "RESERVED" 200 "RESERVED" 201 "RESERVED" 202 "RESERVED" 203 "RESERVED" 204 "RESERVED" 205 "RESERVED" 206 "RESERVED" 207 "RESERVED" 208 "RESERVED" 209 "RESERVED" 210 "RESERVED" 211 "RESERVED" 212 "RESERVED" 213 "RESERVED" 214 "RESERVED" 215 "RESERVED" 216 "RESERVED" 217 "RESERVED" 218 "RESERVED" 219 "RESERVED" 220 "RESERVED" 221 "RESERVED" 222 "RESERVED" 223 "RESERVED" 224 "RESERVED" 225 "RESERVED" 226 "RESERVED" 227 "RESERVED" 228 "RESERVED" 229 "RESERVED" 230 "RESERVED" 231 "RESERVED" 232 "RESERVED" 233 "RESERVED" 234 "RESERVED" 235 "RESERVED" 236 "RESERVED" 237 "RESERVED" 238 "RESERVED" 239 "RESERVED" 240 "RESERVED" 241 "RESERVED" 242 "RESERVED" 243 "RESERVED" 244 "RESERVED" 245 "RESERVED" 246 "RESERVED" 247 "RESERVED" 248 "RESERVED" 249 "RESERVED" 250 "RESERVED" 251 "RESERVED" 252 "RESERVED" 253 "RESERVED" 254 "RESERVED" 255 "Invalid" ;
VAL_ 291 L_ATCU_HU_FrPsEVntCtrBdryLo_Y 0 "Default" 1 "01~0xC0:PHY=HEX*10 + 0" 192 "01~0xC0:PHY=HEX*10 + 0" 193 "RESERVED" 194 "RESERVED" 195 "RESERVED" 196 "RESERVED" 197 "RESERVED" 198 "RESERVED" 199 "RESERVED" 200 "RESERVED" 201 "RESERVED" 202 "RESERVED" 203 "RESERVED" 204 "RESERVED" 205 "RESERVED" 206 "RESERVED" 207 "RESERVED" 208 "RESERVED" 209 "RESERVED" 210 "RESERVED" 211 "RESERVED" 212 "RESERVED" 213 "RESERVED" 214 "RESERVED" 215 "RESERVED" 216 "RESERVED" 217 "RESERVED" 218 "RESERVED" 219 "RESERVED" 220 "RESERVED" 221 "RESERVED" 222 "RESERVED" 223 "RESERVED" 224 "RESERVED" 225 "RESERVED" 226 "RESERVED" 227 "RESERVED" 228 "RESERVED" 229 "RESERVED" 230 "RESERVED" 231 "RESERVED" 232 "RESERVED" 233 "RESERVED" 234 "RESERVED" 235 "RESERVED" 236 "RESERVED" 237 "RESERVED" 238 "RESERVED" 239 "RESERVED" 240 "RESERVED" 241 "RESERVED" 242 "RESERVED" 243 "RESERVED" 244 "RESERVED" 245 "RESERVED" 246 "RESERVED" 247 "RESERVED" 248 "RESERVED" 249 "RESERVED" 250 "RESERVED" 251 "RESERVED" 252 "RESERVED" 253 "RESERVED" 254 "RESERVED" 255 "Invalid" ;
VAL_ 291 L_ATCU_HU_FrPsEVntSideBdryUp_Y 0 "Default" 1 "01~0xC0:PHY=HEX*10 + 0" 192 "01~0xC0:PHY=HEX*10 + 0" 193 "RESERVED" 194 "RESERVED" 195 "RESERVED" 196 "RESERVED" 197 "RESERVED" 198 "RESERVED" 199 "RESERVED" 200 "RESERVED" 201 "RESERVED" 202 "RESERVED" 203 "RESERVED" 204 "RESERVED" 205 "RESERVED" 206 "RESERVED" 207 "RESERVED" 208 "RESERVED" 209 "RESERVED" 210 "RESERVED" 211 "RESERVED" 212 "RESERVED" 213 "RESERVED" 214 "RESERVED" 215 "RESERVED" 216 "RESERVED" 217 "RESERVED" 218 "RESERVED" 219 "RESERVED" 220 "RESERVED" 221 "RESERVED" 222 "RESERVED" 223 "RESERVED" 224 "RESERVED" 225 "RESERVED" 226 "RESERVED" 227 "RESERVED" 228 "RESERVED" 229 "RESERVED" 230 "RESERVED" 231 "RESERVED" 232 "RESERVED" 233 "RESERVED" 234 "RESERVED" 235 "RESERVED" 236 "RESERVED" 237 "RESERVED" 238 "RESERVED" 239 "RESERVED" 240 "RESERVED" 241 "RESERVED" 242 "RESERVED" 243 "RESERVED" 244 "RESERVED" 245 "RESERVED" 246 "RESERVED" 247 "RESERVED" 248 "RESERVED" 249 "RESERVED" 250 "RESERVED" 251 "RESERVED" 252 "RESERVED" 253 "RESERVED" 254 "RESERVED" 255 "Invalid" ;
VAL_ 292 L_ATCU_HU_RrDrEVntConsBdryUp_X 0 "Default" 1 "01~0xC0:PHY=HEX*10 + 0" 192 "01~0xC0:PHY=HEX*10 + 0" 193 "RESERVED" 194 "RESERVED" 195 "RESERVED" 196 "RESERVED" 197 "RESERVED" 198 "RESERVED" 199 "RESERVED" 200 "RESERVED" 201 "RESERVED" 202 "RESERVED" 203 "RESERVED" 204 "RESERVED" 205 "RESERVED" 206 "RESERVED" 207 "RESERVED" 208 "RESERVED" 209 "RESERVED" 210 "RESERVED" 211 "RESERVED" 212 "RESERVED" 213 "RESERVED" 214 "RESERVED" 215 "RESERVED" 216 "RESERVED" 217 "RESERVED" 218 "RESERVED" 219 "RESERVED" 220 "RESERVED" 221 "RESERVED" 222 "RESERVED" 223 "RESERVED" 224 "RESERVED" 225 "RESERVED" 226 "RESERVED" 227 "RESERVED" 228 "RESERVED" 229 "RESERVED" 230 "RESERVED" 231 "RESERVED" 232 "RESERVED" 233 "RESERVED" 234 "RESERVED" 235 "RESERVED" 236 "RESERVED" 237 "RESERVED" 238 "RESERVED" 239 "RESERVED" 240 "RESERVED" 241 "RESERVED" 242 "RESERVED" 243 "RESERVED" 244 "RESERVED" 245 "RESERVED" 246 "RESERVED" 247 "RESERVED" 248 "RESERVED" 249 "RESERVED" 250 "RESERVED" 251 "RESERVED" 252 "RESERVED" 253 "RESERVED" 254 "RESERVED" 255 "Invalid" ;
VAL_ 292 L_ATCU_HU_RrDrEVntConsBdryLo_X 0 "Default" 1 "01~0xC0:PHY=HEX*10 + 0" 192 "01~0xC0:PHY=HEX*10 + 0" 193 "RESERVED" 194 "RESERVED" 195 "RESERVED" 196 "RESERVED" 197 "RESERVED" 198 "RESERVED" 199 "RESERVED" 200 "RESERVED" 201 "RESERVED" 202 "RESERVED" 203 "RESERVED" 204 "RESERVED" 205 "RESERVED" 206 "RESERVED" 207 "RESERVED" 208 "RESERVED" 209 "RESERVED" 210 "RESERVED" 211 "RESERVED" 212 "RESERVED" 213 "RESERVED" 214 "RESERVED" 215 "RESERVED" 216 "RESERVED" 217 "RESERVED" 218 "RESERVED" 219 "RESERVED" 220 "RESERVED" 221 "RESERVED" 222 "RESERVED" 223 "RESERVED" 224 "RESERVED" 225 "RESERVED" 226 "RESERVED" 227 "RESERVED" 228 "RESERVED" 229 "RESERVED" 230 "RESERVED" 231 "RESERVED" 232 "RESERVED" 233 "RESERVED" 234 "RESERVED" 235 "RESERVED" 236 "RESERVED" 237 "RESERVED" 238 "RESERVED" 239 "RESERVED" 240 "RESERVED" 241 "RESERVED" 242 "RESERVED" 243 "RESERVED" 244 "RESERVED" 245 "RESERVED" 246 "RESERVED" 247 "RESERVED" 248 "RESERVED" 249 "RESERVED" 250 "RESERVED" 251 "RESERVED" 252 "RESERVED" 253 "RESERVED" 254 "RESERVED" 255 "Invalid" ;
VAL_ 292 L_ATCU_HU_RrDrEVntConsBdryLo_Y 0 "Default" 1 "01~0xC0:PHY=HEX*10 + 0" 192 "01~0xC0:PHY=HEX*10 + 0" 193 "RESERVED" 194 "RESERVED" 195 "RESERVED" 196 "RESERVED" 197 "RESERVED" 198 "RESERVED" 199 "RESERVED" 200 "RESERVED" 201 "RESERVED" 202 "RESERVED" 203 "RESERVED" 204 "RESERVED" 205 "RESERVED" 206 "RESERVED" 207 "RESERVED" 208 "RESERVED" 209 "RESERVED" 210 "RESERVED" 211 "RESERVED" 212 "RESERVED" 213 "RESERVED" 214 "RESERVED" 215 "RESERVED" 216 "RESERVED" 217 "RESERVED" 218 "RESERVED" 219 "RESERVED" 220 "RESERVED" 221 "RESERVED" 222 "RESERVED" 223 "RESERVED" 224 "RESERVED" 225 "RESERVED" 226 "RESERVED" 227 "RESERVED" 228 "RESERVED" 229 "RESERVED" 230 "RESERVED" 231 "RESERVED" 232 "RESERVED" 233 "RESERVED" 234 "RESERVED" 235 "RESERVED" 236 "RESERVED" 237 "RESERVED" 238 "RESERVED" 239 "RESERVED" 240 "RESERVED" 241 "RESERVED" 242 "RESERVED" 243 "RESERVED" 244 "RESERVED" 245 "RESERVED" 246 "RESERVED" 247 "RESERVED" 248 "RESERVED" 249 "RESERVED" 250 "RESERVED" 251 "RESERVED" 252 "RESERVED" 253 "RESERVED" 254 "RESERVED" 255 "Invalid" ;
VAL_ 292 L_ATCU_HU_RrPsEVntConsBdryUp_X 0 "Default" 1 "01~0xC0:PHY=HEX*10 + 0" 192 "01~0xC0:PHY=HEX*10 + 0" 193 "RESERVED" 194 "RESERVED" 195 "RESERVED" 196 "RESERVED" 197 "RESERVED" 198 "RESERVED" 199 "RESERVED" 200 "RESERVED" 201 "RESERVED" 202 "RESERVED" 203 "RESERVED" 204 "RESERVED" 205 "RESERVED" 206 "RESERVED" 207 "RESERVED" 208 "RESERVED" 209 "RESERVED" 210 "RESERVED" 211 "RESERVED" 212 "RESERVED" 213 "RESERVED" 214 "RESERVED" 215 "RESERVED" 216 "RESERVED" 217 "RESERVED" 218 "RESERVED" 219 "RESERVED" 220 "RESERVED" 221 "RESERVED" 222 "RESERVED" 223 "RESERVED" 224 "RESERVED" 225 "RESERVED" 226 "RESERVED" 227 "RESERVED" 228 "RESERVED" 229 "RESERVED" 230 "RESERVED" 231 "RESERVED" 232 "RESERVED" 233 "RESERVED" 234 "RESERVED" 235 "RESERVED" 236 "RESERVED" 237 "RESERVED" 238 "RESERVED" 239 "RESERVED" 240 "RESERVED" 241 "RESERVED" 242 "RESERVED" 243 "RESERVED" 244 "RESERVED" 245 "RESERVED" 246 "RESERVED" 247 "RESERVED" 248 "RESERVED" 249 "RESERVED" 250 "RESERVED" 251 "RESERVED" 252 "RESERVED" 253 "RESERVED" 254 "RESERVED" 255 "Invalid" ;
VAL_ 292 L_ATCU_HU_RrPsEVntConsBdryUp_Y 0 "Default" 1 "01~0xC0:PHY=HEX*10 + 0" 192 "01~0xC0:PHY=HEX*10 + 0" 193 "RESERVED" 194 "RESERVED" 195 "RESERVED" 196 "RESERVED" 197 "RESERVED" 198 "RESERVED" 199 "RESERVED" 200 "RESERVED" 201 "RESERVED" 202 "RESERVED" 203 "RESERVED" 204 "RESERVED" 205 "RESERVED" 206 "RESERVED" 207 "RESERVED" 208 "RESERVED" 209 "RESERVED" 210 "RESERVED" 211 "RESERVED" 212 "RESERVED" 213 "RESERVED" 214 "RESERVED" 215 "RESERVED" 216 "RESERVED" 217 "RESERVED" 218 "RESERVED" 219 "RESERVED" 220 "RESERVED" 221 "RESERVED" 222 "RESERVED" 223 "RESERVED" 224 "RESERVED" 225 "RESERVED" 226 "RESERVED" 227 "RESERVED" 228 "RESERVED" 229 "RESERVED" 230 "RESERVED" 231 "RESERVED" 232 "RESERVED" 233 "RESERVED" 234 "RESERVED" 235 "RESERVED" 236 "RESERVED" 237 "RESERVED" 238 "RESERVED" 239 "RESERVED" 240 "RESERVED" 241 "RESERVED" 242 "RESERVED" 243 "RESERVED" 244 "RESERVED" 245 "RESERVED" 246 "RESERVED" 247 "RESERVED" 248 "RESERVED" 249 "RESERVED" 250 "RESERVED" 251 "RESERVED" 252 "RESERVED" 253 "RESERVED" 254 "RESERVED" 255 "Invalid" ;
VAL_ 292 L_ATCU_HU_RrPsEVntConsBdryLo_X 0 "Default" 1 "01~0xC0:PHY=HEX*10 + 0" 192 "01~0xC0:PHY=HEX*10 + 0" 193 "RESERVED" 194 "RESERVED" 195 "RESERVED" 196 "RESERVED" 197 "RESERVED" 198 "RESERVED" 199 "RESERVED" 200 "RESERVED" 201 "RESERVED" 202 "RESERVED" 203 "RESERVED" 204 "RESERVED" 205 "RESERVED" 206 "RESERVED" 207 "RESERVED" 208 "RESERVED" 209 "RESERVED" 210 "RESERVED" 211 "RESERVED" 212 "RESERVED" 213 "RESERVED" 214 "RESERVED" 215 "RESERVED" 216 "RESERVED" 217 "RESERVED" 218 "RESERVED" 219 "RESERVED" 220 "RESERVED" 221 "RESERVED" 222 "RESERVED" 223 "RESERVED" 224 "RESERVED" 225 "RESERVED" 226 "RESERVED" 227 "RESERVED" 228 "RESERVED" 229 "RESERVED" 230 "RESERVED" 231 "RESERVED" 232 "RESERVED" 233 "RESERVED" 234 "RESERVED" 235 "RESERVED" 236 "RESERVED" 237 "RESERVED" 238 "RESERVED" 239 "RESERVED" 240 "RESERVED" 241 "RESERVED" 242 "RESERVED" 243 "RESERVED" 244 "RESERVED" 245 "RESERVED" 246 "RESERVED" 247 "RESERVED" 248 "RESERVED" 249 "RESERVED" 250 "RESERVED" 251 "RESERVED" 252 "RESERVED" 253 "RESERVED" 254 "RESERVED" 255 "Invalid" ;
VAL_ 292 L_ATCU_HU_RrPsEVntConsBdryLo_Y 0 "Default" 1 "01~0xC0:PHY=HEX*10 + 0" 192 "01~0xC0:PHY=HEX*10 + 0" 193 "RESERVED" 194 "RESERVED" 195 "RESERVED" 196 "RESERVED" 197 "RESERVED" 198 "RESERVED" 199 "RESERVED" 200 "RESERVED" 201 "RESERVED" 202 "RESERVED" 203 "RESERVED" 204 "RESERVED" 205 "RESERVED" 206 "RESERVED" 207 "RESERVED" 208 "RESERVED" 209 "RESERVED" 210 "RESERVED" 211 "RESERVED" 212 "RESERVED" 213 "RESERVED" 214 "RESERVED" 215 "RESERVED" 216 "RESERVED" 217 "RESERVED" 218 "RESERVED" 219 "RESERVED" 220 "RESERVED" 221 "RESERVED" 222 "RESERVED" 223 "RESERVED" 224 "RESERVED" 225 "RESERVED" 226 "RESERVED" 227 "RESERVED" 228 "RESERVED" 229 "RESERVED" 230 "RESERVED" 231 "RESERVED" 232 "RESERVED" 233 "RESERVED" 234 "RESERVED" 235 "RESERVED" 236 "RESERVED" 237 "RESERVED" 238 "RESERVED" 239 "RESERVED" 240 "RESERVED" 241 "RESERVED" 242 "RESERVED" 243 "RESERVED" 244 "RESERVED" 245 "RESERVED" 246 "RESERVED" 247 "RESERVED" 248 "RESERVED" 249 "RESERVED" 250 "RESERVED" 251 "RESERVED" 252 "RESERVED" 253 "RESERVED" 254 "RESERVED" 255 "Invalid" ;
VAL_ 292 L_ATCU_HU_RrDrEVntConsBdryUp_Y 0 "Default" 1 "01~0xC0:PHY=HEX*10 + 0" 192 "01~0xC0:PHY=HEX*10 + 0" 193 "RESERVED" 194 "RESERVED" 195 "RESERVED" 196 "RESERVED" 197 "RESERVED" 198 "RESERVED" 199 "RESERVED" 200 "RESERVED" 201 "RESERVED" 202 "RESERVED" 203 "RESERVED" 204 "RESERVED" 205 "RESERVED" 206 "RESERVED" 207 "RESERVED" 208 "RESERVED" 209 "RESERVED" 210 "RESERVED" 211 "RESERVED" 212 "RESERVED" 213 "RESERVED" 214 "RESERVED" 215 "RESERVED" 216 "RESERVED" 217 "RESERVED" 218 "RESERVED" 219 "RESERVED" 220 "RESERVED" 221 "RESERVED" 222 "RESERVED" 223 "RESERVED" 224 "RESERVED" 225 "RESERVED" 226 "RESERVED" 227 "RESERVED" 228 "RESERVED" 229 "RESERVED" 230 "RESERVED" 231 "RESERVED" 232 "RESERVED" 233 "RESERVED" 234 "RESERVED" 235 "RESERVED" 236 "RESERVED" 237 "RESERVED" 238 "RESERVED" 239 "RESERVED" 240 "RESERVED" 241 "RESERVED" 242 "RESERVED" 243 "RESERVED" 244 "RESERVED" 245 "RESERVED" 246 "RESERVED" 247 "RESERVED" 248 "RESERVED" 249 "RESERVED" 250 "RESERVED" 251 "RESERVED" 252 "RESERVED" 253 "RESERVED" 254 "RESERVED" 255 "Invalid" ;
VAL_ 293 L_ATCU_CTS_FrDrEVntSidePt_X 0 "Default" 1 "001~0x780:PHY=HEX*1 + 0" 1920 "001~0x780:PHY=HEX*1 + 0" 1921 "781~0x7FE:RESERVED" 2046 "781~0x7FE:RESERVED" 2047 "Invalid" ;
VAL_ 293 L_ATCU_CTS_FrDrEVntSidePt_Y 0 "Default" 1 "001~0x780:PHY=HEX*1 + 0" 1920 "001~0x780:PHY=HEX*1 + 0" 1921 "781~0x7FE:RESERVED" 2046 "781~0x7FE:RESERVED" 2047 "Invalid" ;
VAL_ 293 L_ATCU_CTS_FrDrEVntCtrPt_X 0 "Default" 1 "001~0x780:PHY=HEX*1 + 0" 1920 "001~0x780:PHY=HEX*1 + 0" 1921 "781~0x7FE:RESERVED" 2046 "781~0x7FE:RESERVED" 2047 "Invalid" ;
VAL_ 293 L_ATCU_CTS_FrDrEVntCtrPt_Y 0 "Default" 1 "001~0x780:PHY=HEX*1 + 0" 1920 "001~0x780:PHY=HEX*1 + 0" 1921 "781~0x7FE:RESERVED" 2046 "781~0x7FE:RESERVED" 2047 "Invalid" ;
VAL_ 294 L_ATCU_CTS_FrPsEVntSidePt_X 0 "Default" 1 "001~0x780:PHY=HEX*1 + 0" 1920 "001~0x780:PHY=HEX*1 + 0" 1921 "781~0x7FE:RESERVED" 2046 "781~0x7FE:RESERVED" 2047 "Invalid" ;
VAL_ 294 L_ATCU_CTS_FrPsEVntSidePt_Y 0 "Default" 1 "001~0x780:PHY=HEX*1 + 0" 1920 "001~0x780:PHY=HEX*1 + 0" 1921 "781~0x7FE:RESERVED" 2046 "781~0x7FE:RESERVED" 2047 "Invalid" ;
VAL_ 294 L_ATCU_CTS_FrPsEVntCtrPt_X 0 "Default" 1 "001~0x780:PHY=HEX*1 + 0" 1920 "001~0x780:PHY=HEX*1 + 0" 1921 "781~0x7FE:RESERVED" 2046 "781~0x7FE:RESERVED" 2047 "Invalid" ;
VAL_ 294 L_ATCU_CTS_FrPsEVntCtrPt_Y 0 "Default" 1 "001~0x780:PHY=HEX*1 + 0" 1920 "001~0x780:PHY=HEX*1 + 0" 1921 "781~0x7FE:RESERVED" 2046 "781~0x7FE:RESERVED" 2047 "Invalid" ;
VAL_ 295 L_ATCU_CTS_RrDrEVntConsPt_X 0 "Default" 1 "001~0x780:PHY=HEX*1 + 0" 1920 "001~0x780:PHY=HEX*1 + 0" 1921 "781~0x7FE:RESERVED" 2046 "781~0x7FE:RESERVED" 2047 "Invalid" ;
VAL_ 295 L_ATCU_CTS_RrDrEVntConsPt_Y 0 "Default" 1 "001~0x780:PHY=HEX*1 + 0" 1920 "001~0x780:PHY=HEX*1 + 0" 1921 "781~0x7FE:RESERVED" 2046 "781~0x7FE:RESERVED" 2047 "Invalid" ;
VAL_ 295 L_ATCU_CTS_RrPsEVntConsPt_X 0 "Default" 1 "001~0x780:PHY=HEX*1 + 0" 1920 "001~0x780:PHY=HEX*1 + 0" 1921 "781~0x7FE:RESERVED" 2046 "781~0x7FE:RESERVED" 2047 "Invalid" ;
VAL_ 295 L_ATCU_CTS_RrPsEVntConsPt_Y 0 "Default" 1 "001~0x780:PHY=HEX*1 + 0" 1920 "001~0x780:PHY=HEX*1 + 0" 1921 "781~0x7FE:RESERVED" 2046 "781~0x7FE:RESERVED" 2047 "Invalid" ;
VAL_ 295 L_ATCU_CTS_RrDrEVntModeSet 0 "Default" 1 "FOCUS Mode" 2 "SPREAD Mode" 3 "CYCLE Mode" 4 "FREE Mode" 5 "OFF" 6 "RESERVED" 7 "RESERVED" 8 "RESERVED" 9 "RESERVED" 10 "RESERVED" 11 "RESERVED" 12 "RESERVED" 13 "RESERVED" 14 "RESERVED" 15 "Invalid" ;
VAL_ 295 L_ATCU_CTS_RrPsEVntModeSet 0 "Default" 1 "FOCUS Mode" 2 "SPREAD Mode" 3 "CYCLE Mode" 4 "FREE Mode" 5 "OFF" 6 "RESERVED" 7 "RESERVED" 8 "RESERVED" 9 "RESERVED" 10 "RESERVED" 11 "RESERVED" 12 "RESERVED" 13 "RESERVED" 14 "RESERVED" 15 "Invalid" ;
VAL_ 295 L_ATCU_CTS_RrDrEVntConsOpnCls 0 "Default" 1 "OPEN" 2 "CLOSE" 3 "Invalid" ;
VAL_ 295 L_ATCU_CTS_RrPsEVntConsOpnCls 0 "Default" 1 "OPEN" 2 "CLOSE" 3 "Invalid" ;
VAL_ 296 L_ATCU_CTS_FrDrEVntSideBdryUp_X 0 "Default" 1 "01~0xC0:PHY=HEX*10 + 0" 192 "01~0xC0:PHY=HEX*10 + 0" 193 "RESERVED" 194 "RESERVED" 195 "RESERVED" 196 "RESERVED" 197 "RESERVED" 198 "RESERVED" 199 "RESERVED" 200 "RESERVED" 201 "RESERVED" 202 "RESERVED" 203 "RESERVED" 204 "RESERVED" 205 "RESERVED" 206 "RESERVED" 207 "RESERVED" 208 "RESERVED" 209 "RESERVED" 210 "RESERVED" 211 "RESERVED" 212 "RESERVED" 213 "RESERVED" 214 "RESERVED" 215 "RESERVED" 216 "RESERVED" 217 "RESERVED" 218 "RESERVED" 219 "RESERVED" 220 "RESERVED" 221 "RESERVED" 222 "RESERVED" 223 "RESERVED" 224 "RESERVED" 225 "RESERVED" 226 "RESERVED" 227 "RESERVED" 228 "RESERVED" 229 "RESERVED" 230 "RESERVED" 231 "RESERVED" 232 "RESERVED" 233 "RESERVED" 234 "RESERVED" 235 "RESERVED" 236 "RESERVED" 237 "RESERVED" 238 "RESERVED" 239 "RESERVED" 240 "RESERVED" 241 "RESERVED" 242 "RESERVED" 243 "RESERVED" 244 "RESERVED" 245 "RESERVED" 246 "RESERVED" 247 "RESERVED" 248 "RESERVED" 249 "RESERVED" 250 "RESERVED" 251 "RESERVED" 252 "RESERVED" 253 "RESERVED" 254 "RESERVED" 255 "Invalid" ;
VAL_ 296 L_ATCU_CTS_FrDrEVntSideBdryLo_X 0 "Default" 1 "01~0xC0:PHY=HEX*10 + 0" 192 "01~0xC0:PHY=HEX*10 + 0" 193 "RESERVED" 194 "RESERVED" 195 "RESERVED" 196 "RESERVED" 197 "RESERVED" 198 "RESERVED" 199 "RESERVED" 200 "RESERVED" 201 "RESERVED" 202 "RESERVED" 203 "RESERVED" 204 "RESERVED" 205 "RESERVED" 206 "RESERVED" 207 "RESERVED" 208 "RESERVED" 209 "RESERVED" 210 "RESERVED" 211 "RESERVED" 212 "RESERVED" 213 "RESERVED" 214 "RESERVED" 215 "RESERVED" 216 "RESERVED" 217 "RESERVED" 218 "RESERVED" 219 "RESERVED" 220 "RESERVED" 221 "RESERVED" 222 "RESERVED" 223 "RESERVED" 224 "RESERVED" 225 "RESERVED" 226 "RESERVED" 227 "RESERVED" 228 "RESERVED" 229 "RESERVED" 230 "RESERVED" 231 "RESERVED" 232 "RESERVED" 233 "RESERVED" 234 "RESERVED" 235 "RESERVED" 236 "RESERVED" 237 "RESERVED" 238 "RESERVED" 239 "RESERVED" 240 "RESERVED" 241 "RESERVED" 242 "RESERVED" 243 "RESERVED" 244 "RESERVED" 245 "RESERVED" 246 "RESERVED" 247 "RESERVED" 248 "RESERVED" 249 "RESERVED" 250 "RESERVED" 251 "RESERVED" 252 "RESERVED" 253 "RESERVED" 254 "RESERVED" 255 "Invalid" ;
VAL_ 296 L_ATCU_CTS_FrDrEVntSideBdryLo_Y 0 "Default" 1 "01~0xC0:PHY=HEX*10 + 0" 192 "01~0xC0:PHY=HEX*10 + 0" 193 "RESERVED" 194 "RESERVED" 195 "RESERVED" 196 "RESERVED" 197 "RESERVED" 198 "RESERVED" 199 "RESERVED" 200 "RESERVED" 201 "RESERVED" 202 "RESERVED" 203 "RESERVED" 204 "RESERVED" 205 "RESERVED" 206 "RESERVED" 207 "RESERVED" 208 "RESERVED" 209 "RESERVED" 210 "RESERVED" 211 "RESERVED" 212 "RESERVED" 213 "RESERVED" 214 "RESERVED" 215 "RESERVED" 216 "RESERVED" 217 "RESERVED" 218 "RESERVED" 219 "RESERVED" 220 "RESERVED" 221 "RESERVED" 222 "RESERVED" 223 "RESERVED" 224 "RESERVED" 225 "RESERVED" 226 "RESERVED" 227 "RESERVED" 228 "RESERVED" 229 "RESERVED" 230 "RESERVED" 231 "RESERVED" 232 "RESERVED" 233 "RESERVED" 234 "RESERVED" 235 "RESERVED" 236 "RESERVED" 237 "RESERVED" 238 "RESERVED" 239 "RESERVED" 240 "RESERVED" 241 "RESERVED" 242 "RESERVED" 243 "RESERVED" 244 "RESERVED" 245 "RESERVED" 246 "RESERVED" 247 "RESERVED" 248 "RESERVED" 249 "RESERVED" 250 "RESERVED" 251 "RESERVED" 252 "RESERVED" 253 "RESERVED" 254 "RESERVED" 255 "Invalid" ;
VAL_ 296 L_ATCU_CTS_FrDrEVntCtrBdryUp_X 0 "Default" 1 "01~0xC0:PHY=HEX*10 + 0" 192 "01~0xC0:PHY=HEX*10 + 0" 193 "RESERVED" 194 "RESERVED" 195 "RESERVED" 196 "RESERVED" 197 "RESERVED" 198 "RESERVED" 199 "RESERVED" 200 "RESERVED" 201 "RESERVED" 202 "RESERVED" 203 "RESERVED" 204 "RESERVED" 205 "RESERVED" 206 "RESERVED" 207 "RESERVED" 208 "RESERVED" 209 "RESERVED" 210 "RESERVED" 211 "RESERVED" 212 "RESERVED" 213 "RESERVED" 214 "RESERVED" 215 "RESERVED" 216 "RESERVED" 217 "RESERVED" 218 "RESERVED" 219 "RESERVED" 220 "RESERVED" 221 "RESERVED" 222 "RESERVED" 223 "RESERVED" 224 "RESERVED" 225 "RESERVED" 226 "RESERVED" 227 "RESERVED" 228 "RESERVED" 229 "RESERVED" 230 "RESERVED" 231 "RESERVED" 232 "RESERVED" 233 "RESERVED" 234 "RESERVED" 235 "RESERVED" 236 "RESERVED" 237 "RESERVED" 238 "RESERVED" 239 "RESERVED" 240 "RESERVED" 241 "RESERVED" 242 "RESERVED" 243 "RESERVED" 244 "RESERVED" 245 "RESERVED" 246 "RESERVED" 247 "RESERVED" 248 "RESERVED" 249 "RESERVED" 250 "RESERVED" 251 "RESERVED" 252 "RESERVED" 253 "RESERVED" 254 "RESERVED" 255 "Invalid" ;
VAL_ 296 L_ATCU_CTS_FrDrEVntCtrBdryUp_Y 0 "Default" 1 "01~0xC0:PHY=HEX*10 + 0" 192 "01~0xC0:PHY=HEX*10 + 0" 193 "RESERVED" 194 "RESERVED" 195 "RESERVED" 196 "RESERVED" 197 "RESERVED" 198 "RESERVED" 199 "RESERVED" 200 "RESERVED" 201 "RESERVED" 202 "RESERVED" 203 "RESERVED" 204 "RESERVED" 205 "RESERVED" 206 "RESERVED" 207 "RESERVED" 208 "RESERVED" 209 "RESERVED" 210 "RESERVED" 211 "RESERVED" 212 "RESERVED" 213 "RESERVED" 214 "RESERVED" 215 "RESERVED" 216 "RESERVED" 217 "RESERVED" 218 "RESERVED" 219 "RESERVED" 220 "RESERVED" 221 "RESERVED" 222 "RESERVED" 223 "RESERVED" 224 "RESERVED" 225 "RESERVED" 226 "RESERVED" 227 "RESERVED" 228 "RESERVED" 229 "RESERVED" 230 "RESERVED" 231 "RESERVED" 232 "RESERVED" 233 "RESERVED" 234 "RESERVED" 235 "RESERVED" 236 "RESERVED" 237 "RESERVED" 238 "RESERVED" 239 "RESERVED" 240 "RESERVED" 241 "RESERVED" 242 "RESERVED" 243 "RESERVED" 244 "RESERVED" 245 "RESERVED" 246 "RESERVED" 247 "RESERVED" 248 "RESERVED" 249 "RESERVED" 250 "RESERVED" 251 "RESERVED" 252 "RESERVED" 253 "RESERVED" 254 "RESERVED" 255 "Invalid" ;
VAL_ 296 L_ATCU_CTS_FrDrEVntCtrBdryLo_X 0 "Default" 1 "01~0xC0:PHY=HEX*10 + 0" 192 "01~0xC0:PHY=HEX*10 + 0" 193 "RESERVED" 194 "RESERVED" 195 "RESERVED" 196 "RESERVED" 197 "RESERVED" 198 "RESERVED" 199 "RESERVED" 200 "RESERVED" 201 "RESERVED" 202 "RESERVED" 203 "RESERVED" 204 "RESERVED" 205 "RESERVED" 206 "RESERVED" 207 "RESERVED" 208 "RESERVED" 209 "RESERVED" 210 "RESERVED" 211 "RESERVED" 212 "RESERVED" 213 "RESERVED" 214 "RESERVED" 215 "RESERVED" 216 "RESERVED" 217 "RESERVED" 218 "RESERVED" 219 "RESERVED" 220 "RESERVED" 221 "RESERVED" 222 "RESERVED" 223 "RESERVED" 224 "RESERVED" 225 "RESERVED" 226 "RESERVED" 227 "RESERVED" 228 "RESERVED" 229 "RESERVED" 230 "RESERVED" 231 "RESERVED" 232 "RESERVED" 233 "RESERVED" 234 "RESERVED" 235 "RESERVED" 236 "RESERVED" 237 "RESERVED" 238 "RESERVED" 239 "RESERVED" 240 "RESERVED" 241 "RESERVED" 242 "RESERVED" 243 "RESERVED" 244 "RESERVED" 245 "RESERVED" 246 "RESERVED" 247 "RESERVED" 248 "RESERVED" 249 "RESERVED" 250 "RESERVED" 251 "RESERVED" 252 "RESERVED" 253 "RESERVED" 254 "RESERVED" 255 "Invalid" ;
VAL_ 296 L_ATCU_CTS_FrDrEVntCtrBdryLo_Y 0 "Default" 1 "01~0xC0:PHY=HEX*10 + 0" 192 "01~0xC0:PHY=HEX*10 + 0" 193 "RESERVED" 194 "RESERVED" 195 "RESERVED" 196 "RESERVED" 197 "RESERVED" 198 "RESERVED" 199 "RESERVED" 200 "RESERVED" 201 "RESERVED" 202 "RESERVED" 203 "RESERVED" 204 "RESERVED" 205 "RESERVED" 206 "RESERVED" 207 "RESERVED" 208 "RESERVED" 209 "RESERVED" 210 "RESERVED" 211 "RESERVED" 212 "RESERVED" 213 "RESERVED" 214 "RESERVED" 215 "RESERVED" 216 "RESERVED" 217 "RESERVED" 218 "RESERVED" 219 "RESERVED" 220 "RESERVED" 221 "RESERVED" 222 "RESERVED" 223 "RESERVED" 224 "RESERVED" 225 "RESERVED" 226 "RESERVED" 227 "RESERVED" 228 "RESERVED" 229 "RESERVED" 230 "RESERVED" 231 "RESERVED" 232 "RESERVED" 233 "RESERVED" 234 "RESERVED" 235 "RESERVED" 236 "RESERVED" 237 "RESERVED" 238 "RESERVED" 239 "RESERVED" 240 "RESERVED" 241 "RESERVED" 242 "RESERVED" 243 "RESERVED" 244 "RESERVED" 245 "RESERVED" 246 "RESERVED" 247 "RESERVED" 248 "RESERVED" 249 "RESERVED" 250 "RESERVED" 251 "RESERVED" 252 "RESERVED" 253 "RESERVED" 254 "RESERVED" 255 "Invalid" ;
VAL_ 296 L_ATCU_CTS_FrDrEVntSideBdryUp_Y 0 "Default" 1 "01~0xC0:PHY=HEX*10 + 0" 192 "01~0xC0:PHY=HEX*10 + 0" 193 "RESERVED" 194 "RESERVED" 195 "RESERVED" 196 "RESERVED" 197 "RESERVED" 198 "RESERVED" 199 "RESERVED" 200 "RESERVED" 201 "RESERVED" 202 "RESERVED" 203 "RESERVED" 204 "RESERVED" 205 "RESERVED" 206 "RESERVED" 207 "RESERVED" 208 "RESERVED" 209 "RESERVED" 210 "RESERVED" 211 "RESERVED" 212 "RESERVED" 213 "RESERVED" 214 "RESERVED" 215 "RESERVED" 216 "RESERVED" 217 "RESERVED" 218 "RESERVED" 219 "RESERVED" 220 "RESERVED" 221 "RESERVED" 222 "RESERVED" 223 "RESERVED" 224 "RESERVED" 225 "RESERVED" 226 "RESERVED" 227 "RESERVED" 228 "RESERVED" 229 "RESERVED" 230 "RESERVED" 231 "RESERVED" 232 "RESERVED" 233 "RESERVED" 234 "RESERVED" 235 "RESERVED" 236 "RESERVED" 237 "RESERVED" 238 "RESERVED" 239 "RESERVED" 240 "RESERVED" 241 "RESERVED" 242 "RESERVED" 243 "RESERVED" 244 "RESERVED" 245 "RESERVED" 246 "RESERVED" 247 "RESERVED" 248 "RESERVED" 249 "RESERVED" 250 "RESERVED" 251 "RESERVED" 252 "RESERVED" 253 "RESERVED" 254 "RESERVED" 255 "Invalid" ;
VAL_ 297 L_ATCU_CTS_FrPsEVntSideBdryUp_X 0 "Default" 1 "01~0xC0:PHY=HEX*10 + 0" 192 "01~0xC0:PHY=HEX*10 + 0" 193 "RESERVED" 194 "RESERVED" 195 "RESERVED" 196 "RESERVED" 197 "RESERVED" 198 "RESERVED" 199 "RESERVED" 200 "RESERVED" 201 "RESERVED" 202 "RESERVED" 203 "RESERVED" 204 "RESERVED" 205 "RESERVED" 206 "RESERVED" 207 "RESERVED" 208 "RESERVED" 209 "RESERVED" 210 "RESERVED" 211 "RESERVED" 212 "RESERVED" 213 "RESERVED" 214 "RESERVED" 215 "RESERVED" 216 "RESERVED" 217 "RESERVED" 218 "RESERVED" 219 "RESERVED" 220 "RESERVED" 221 "RESERVED" 222 "RESERVED" 223 "RESERVED" 224 "RESERVED" 225 "RESERVED" 226 "RESERVED" 227 "RESERVED" 228 "RESERVED" 229 "RESERVED" 230 "RESERVED" 231 "RESERVED" 232 "RESERVED" 233 "RESERVED" 234 "RESERVED" 235 "RESERVED" 236 "RESERVED" 237 "RESERVED" 238 "RESERVED" 239 "RESERVED" 240 "RESERVED" 241 "RESERVED" 242 "RESERVED" 243 "RESERVED" 244 "RESERVED" 245 "RESERVED" 246 "RESERVED" 247 "RESERVED" 248 "RESERVED" 249 "RESERVED" 250 "RESERVED" 251 "RESERVED" 252 "RESERVED" 253 "RESERVED" 254 "RESERVED" 255 "Invalid" ;
VAL_ 297 L_ATCU_CTS_FrPsEVntSideBdryLo_X 0 "Default" 1 "01~0xC0:PHY=HEX*10 + 0" 192 "01~0xC0:PHY=HEX*10 + 0" 193 "RESERVED" 194 "RESERVED" 195 "RESERVED" 196 "RESERVED" 197 "RESERVED" 198 "RESERVED" 199 "RESERVED" 200 "RESERVED" 201 "RESERVED" 202 "RESERVED" 203 "RESERVED" 204 "RESERVED" 205 "RESERVED" 206 "RESERVED" 207 "RESERVED" 208 "RESERVED" 209 "RESERVED" 210 "RESERVED" 211 "RESERVED" 212 "RESERVED" 213 "RESERVED" 214 "RESERVED" 215 "RESERVED" 216 "RESERVED" 217 "RESERVED" 218 "RESERVED" 219 "RESERVED" 220 "RESERVED" 221 "RESERVED" 222 "RESERVED" 223 "RESERVED" 224 "RESERVED" 225 "RESERVED" 226 "RESERVED" 227 "RESERVED" 228 "RESERVED" 229 "RESERVED" 230 "RESERVED" 231 "RESERVED" 232 "RESERVED" 233 "RESERVED" 234 "RESERVED" 235 "RESERVED" 236 "RESERVED" 237 "RESERVED" 238 "RESERVED" 239 "RESERVED" 240 "RESERVED" 241 "RESERVED" 242 "RESERVED" 243 "RESERVED" 244 "RESERVED" 245 "RESERVED" 246 "RESERVED" 247 "RESERVED" 248 "RESERVED" 249 "RESERVED" 250 "RESERVED" 251 "RESERVED" 252 "RESERVED" 253 "RESERVED" 254 "RESERVED" 255 "Invalid" ;
VAL_ 297 L_ATCU_CTS_FrPsEVntSideBdryLo_Y 0 "Default" 1 "01~0xC0:PHY=HEX*10 + 0" 192 "01~0xC0:PHY=HEX*10 + 0" 193 "RESERVED" 194 "RESERVED" 195 "RESERVED" 196 "RESERVED" 197 "RESERVED" 198 "RESERVED" 199 "RESERVED" 200 "RESERVED" 201 "RESERVED" 202 "RESERVED" 203 "RESERVED" 204 "RESERVED" 205 "RESERVED" 206 "RESERVED" 207 "RESERVED" 208 "RESERVED" 209 "RESERVED" 210 "RESERVED" 211 "RESERVED" 212 "RESERVED" 213 "RESERVED" 214 "RESERVED" 215 "RESERVED" 216 "RESERVED" 217 "RESERVED" 218 "RESERVED" 219 "RESERVED" 220 "RESERVED" 221 "RESERVED" 222 "RESERVED" 223 "RESERVED" 224 "RESERVED" 225 "RESERVED" 226 "RESERVED" 227 "RESERVED" 228 "RESERVED" 229 "RESERVED" 230 "RESERVED" 231 "RESERVED" 232 "RESERVED" 233 "RESERVED" 234 "RESERVED" 235 "RESERVED" 236 "RESERVED" 237 "RESERVED" 238 "RESERVED" 239 "RESERVED" 240 "RESERVED" 241 "RESERVED" 242 "RESERVED" 243 "RESERVED" 244 "RESERVED" 245 "RESERVED" 246 "RESERVED" 247 "RESERVED" 248 "RESERVED" 249 "RESERVED" 250 "RESERVED" 251 "RESERVED" 252 "RESERVED" 253 "RESERVED" 254 "RESERVED" 255 "Invalid" ;
VAL_ 297 L_ATCU_CTS_FrPsEVntCtrBdryUp_X 0 "Default" 1 "01~0xC0:PHY=HEX*10 + 0" 192 "01~0xC0:PHY=HEX*10 + 0" 193 "RESERVED" 194 "RESERVED" 195 "RESERVED" 196 "RESERVED" 197 "RESERVED" 198 "RESERVED" 199 "RESERVED" 200 "RESERVED" 201 "RESERVED" 202 "RESERVED" 203 "RESERVED" 204 "RESERVED" 205 "RESERVED" 206 "RESERVED" 207 "RESERVED" 208 "RESERVED" 209 "RESERVED" 210 "RESERVED" 211 "RESERVED" 212 "RESERVED" 213 "RESERVED" 214 "RESERVED" 215 "RESERVED" 216 "RESERVED" 217 "RESERVED" 218 "RESERVED" 219 "RESERVED" 220 "RESERVED" 221 "RESERVED" 222 "RESERVED" 223 "RESERVED" 224 "RESERVED" 225 "RESERVED" 226 "RESERVED" 227 "RESERVED" 228 "RESERVED" 229 "RESERVED" 230 "RESERVED" 231 "RESERVED" 232 "RESERVED" 233 "RESERVED" 234 "RESERVED" 235 "RESERVED" 236 "RESERVED" 237 "RESERVED" 238 "RESERVED" 239 "RESERVED" 240 "RESERVED" 241 "RESERVED" 242 "RESERVED" 243 "RESERVED" 244 "RESERVED" 245 "RESERVED" 246 "RESERVED" 247 "RESERVED" 248 "RESERVED" 249 "RESERVED" 250 "RESERVED" 251 "RESERVED" 252 "RESERVED" 253 "RESERVED" 254 "RESERVED" 255 "Invalid" ;
VAL_ 297 L_ATCU_CTS_FrPsEVntCtrBdryUp_Y 0 "Default" 1 "01~0xC0:PHY=HEX*10 + 0" 192 "01~0xC0:PHY=HEX*10 + 0" 193 "RESERVED" 194 "RESERVED" 195 "RESERVED" 196 "RESERVED" 197 "RESERVED" 198 "RESERVED" 199 "RESERVED" 200 "RESERVED" 201 "RESERVED" 202 "RESERVED" 203 "RESERVED" 204 "RESERVED" 205 "RESERVED" 206 "RESERVED" 207 "RESERVED" 208 "RESERVED" 209 "RESERVED" 210 "RESERVED" 211 "RESERVED" 212 "RESERVED" 213 "RESERVED" 214 "RESERVED" 215 "RESERVED" 216 "RESERVED" 217 "RESERVED" 218 "RESERVED" 219 "RESERVED" 220 "RESERVED" 221 "RESERVED" 222 "RESERVED" 223 "RESERVED" 224 "RESERVED" 225 "RESERVED" 226 "RESERVED" 227 "RESERVED" 228 "RESERVED" 229 "RESERVED" 230 "RESERVED" 231 "RESERVED" 232 "RESERVED" 233 "RESERVED" 234 "RESERVED" 235 "RESERVED" 236 "RESERVED" 237 "RESERVED" 238 "RESERVED" 239 "RESERVED" 240 "RESERVED" 241 "RESERVED" 242 "RESERVED" 243 "RESERVED" 244 "RESERVED" 245 "RESERVED" 246 "RESERVED" 247 "RESERVED" 248 "RESERVED" 249 "RESERVED" 250 "RESERVED" 251 "RESERVED" 252 "RESERVED" 253 "RESERVED" 254 "RESERVED" 255 "Invalid" ;
VAL_ 297 L_ATCU_CTS_FrPsEVntCtrBdryLo_X 0 "Default" 1 "01~0xC0:PHY=HEX*10 + 0" 192 "01~0xC0:PHY=HEX*10 + 0" 193 "RESERVED" 194 "RESERVED" 195 "RESERVED" 196 "RESERVED" 197 "RESERVED" 198 "RESERVED" 199 "RESERVED" 200 "RESERVED" 201 "RESERVED" 202 "RESERVED" 203 "RESERVED" 204 "RESERVED" 205 "RESERVED" 206 "RESERVED" 207 "RESERVED" 208 "RESERVED" 209 "RESERVED" 210 "RESERVED" 211 "RESERVED" 212 "RESERVED" 213 "RESERVED" 214 "RESERVED" 215 "RESERVED" 216 "RESERVED" 217 "RESERVED" 218 "RESERVED" 219 "RESERVED" 220 "RESERVED" 221 "RESERVED" 222 "RESERVED" 223 "RESERVED" 224 "RESERVED" 225 "RESERVED" 226 "RESERVED" 227 "RESERVED" 228 "RESERVED" 229 "RESERVED" 230 "RESERVED" 231 "RESERVED" 232 "RESERVED" 233 "RESERVED" 234 "RESERVED" 235 "RESERVED" 236 "RESERVED" 237 "RESERVED" 238 "RESERVED" 239 "RESERVED" 240 "RESERVED" 241 "RESERVED" 242 "RESERVED" 243 "RESERVED" 244 "RESERVED" 245 "RESERVED" 246 "RESERVED" 247 "RESERVED" 248 "RESERVED" 249 "RESERVED" 250 "RESERVED" 251 "RESERVED" 252 "RESERVED" 253 "RESERVED" 254 "RESERVED" 255 "Invalid" ;
VAL_ 297 L_ATCU_CTS_FrPsEVntCtrBdryLo_Y 0 "Default" 1 "01~0xC0:PHY=HEX*10 + 0" 192 "01~0xC0:PHY=HEX*10 + 0" 193 "RESERVED" 194 "RESERVED" 195 "RESERVED" 196 "RESERVED" 197 "RESERVED" 198 "RESERVED" 199 "RESERVED" 200 "RESERVED" 201 "RESERVED" 202 "RESERVED" 203 "RESERVED" 204 "RESERVED" 205 "RESERVED" 206 "RESERVED" 207 "RESERVED" 208 "RESERVED" 209 "RESERVED" 210 "RESERVED" 211 "RESERVED" 212 "RESERVED" 213 "RESERVED" 214 "RESERVED" 215 "RESERVED" 216 "RESERVED" 217 "RESERVED" 218 "RESERVED" 219 "RESERVED" 220 "RESERVED" 221 "RESERVED" 222 "RESERVED" 223 "RESERVED" 224 "RESERVED" 225 "RESERVED" 226 "RESERVED" 227 "RESERVED" 228 "RESERVED" 229 "RESERVED" 230 "RESERVED" 231 "RESERVED" 232 "RESERVED" 233 "RESERVED" 234 "RESERVED" 235 "RESERVED" 236 "RESERVED" 237 "RESERVED" 238 "RESERVED" 239 "RESERVED" 240 "RESERVED" 241 "RESERVED" 242 "RESERVED" 243 "RESERVED" 244 "RESERVED" 245 "RESERVED" 246 "RESERVED" 247 "RESERVED" 248 "RESERVED" 249 "RESERVED" 250 "RESERVED" 251 "RESERVED" 252 "RESERVED" 253 "RESERVED" 254 "RESERVED" 255 "Invalid" ;
VAL_ 297 L_ATCU_CTS_FrPsEVntSideBdryUp_Y 0 "Default" 1 "01~0xC0:PHY=HEX*10 + 0" 192 "01~0xC0:PHY=HEX*10 + 0" 193 "RESERVED" 194 "RESERVED" 195 "RESERVED" 196 "RESERVED" 197 "RESERVED" 198 "RESERVED" 199 "RESERVED" 200 "RESERVED" 201 "RESERVED" 202 "RESERVED" 203 "RESERVED" 204 "RESERVED" 205 "RESERVED" 206 "RESERVED" 207 "RESERVED" 208 "RESERVED" 209 "RESERVED" 210 "RESERVED" 211 "RESERVED" 212 "RESERVED" 213 "RESERVED" 214 "RESERVED" 215 "RESERVED" 216 "RESERVED" 217 "RESERVED" 218 "RESERVED" 219 "RESERVED" 220 "RESERVED" 221 "RESERVED" 222 "RESERVED" 223 "RESERVED" 224 "RESERVED" 225 "RESERVED" 226 "RESERVED" 227 "RESERVED" 228 "RESERVED" 229 "RESERVED" 230 "RESERVED" 231 "RESERVED" 232 "RESERVED" 233 "RESERVED" 234 "RESERVED" 235 "RESERVED" 236 "RESERVED" 237 "RESERVED" 238 "RESERVED" 239 "RESERVED" 240 "RESERVED" 241 "RESERVED" 242 "RESERVED" 243 "RESERVED" 244 "RESERVED" 245 "RESERVED" 246 "RESERVED" 247 "RESERVED" 248 "RESERVED" 249 "RESERVED" 250 "RESERVED" 251 "RESERVED" 252 "RESERVED" 253 "RESERVED" 254 "RESERVED" 255 "Invalid" ;
VAL_ 769 MON_BatteryInit 0 "Off" 1 "On" ;
VAL_ 769 MON_StableStateSnsr 0 "Off" 1 "On" ;
VAL_ 769 MON_KeepMonitorReq 0 "Off" 1 "On" ;
VAL_ 770 MON_InCarTempSnsr 0 "0x0~0x3EB:-40.0~60.0¡É" 1003 "0x0~0x3EB:-40.0~60.0¡É" 1004 "3EC~0xFFFE:RESERVED" 65534 "3EC~0xFFFE:RESERVED" 65535 "Invalid" ;
VAL_ 770 MON_AMBTempSnsr 0 "0x0~0x3EB:-40.0~60.0¡É" 1003 "0x0~0x3EB:-40.0~60.0¡É" 1004 "3EC~0xFFFE:RESERVED" 65534 "3EC~0xFFFE:RESERVED" 65535 "Invalid" ;
VAL_ 770 MON_EvapTempSnsr 0 "0x0~0x258:-20.0~40.0¡É" 600 "0x0~0x258:-20.0~40.0¡É" 601 "259~0xFFFE:RESERVED" 65534 "259~0xFFFE:RESERVED" 65535 "Invalid" ;
VAL_ 770 MON_DOHSnsr 0 "0x0~0x64:0~100%" 100 "0x0~0x64:0~100%" 101 "65~0xFFFE:RESERVED" 65534 "65~0xFFFE:RESERVED" 65535 "Invalid" ;
VAL_ 771 MON_FineDustSnsr 0 "0x0~0xFF:0~255" 255 "0x0~0xFF:0~255" 256 "100~0xFFFE:RESERVED" 65534 "100~0xFFFE:RESERVED" 65535 "Invalid" ;
VAL_ 771 MON_LHPhotoSnsr 0 "0x0~0x1388:0~5.000V" 5000 "0x0~0x1388:0~5.000V" 5001 "1389~0xFFFE:RESERVED" 65534 "1389~0xFFFE:RESERVED" 65535 "Invalid" ;
VAL_ 771 MON_RHPhotoSnsr 0 "0x0~0x1388:0~5.000V" 5000 "0x0~0x1388:0~5.000V" 5001 "1389~0xFFFE:RESERVED" 65534 "1389~0xFFFE:RESERVED" 65535 "Invalid" ;
VAL_ 772 MON_DrvVentDuctSnsr 0 "0x0~0x640:-40.0~160.0¡É" 1600 "0x0~0x640:-40.0~160.0¡É" 1601 "641~0xFFFE:RESERVED" 65534 "641~0xFFFE:RESERVED" 65535 "Invalid" ;
VAL_ 772 MON_AstVentDuctSnsr 0 "0x0~0x640:-40.0~160.0¡É" 1600 "0x0~0x640:-40.0~160.0¡É" 1601 "641~0xFFFE:RESERVED" 65534 "641~0xFFFE:RESERVED" 65535 "Invalid" ;
VAL_ 772 MON_DrvFloorDuctSnsr 0 "0x0~0x640:-40.0~160.0¡É" 1600 "0x0~0x640:-40.0~160.0¡É" 1601 "641~0xFFFE:RESERVED" 65534 "641~0xFFFE:RESERVED" 65535 "Invalid" ;
VAL_ 772 MON_AstFloorDuctSnsr 0 "0x0~0x640:-40.0~160.0¡É" 1600 "0x0~0x640:-40.0~160.0¡É" 1601 "641~0xFFFE:RESERVED" 65534 "641~0xFFFE:RESERVED" 65535 "Invalid" ;
VAL_ 773 MON_DEFDuctSnsr 0 "0x0~0x640:-40.0~160.0¡É" 1600 "0x0~0x640:-40.0~160.0¡É" 1601 "641~0xFFFE:RESERVED" 65534 "641~0xFFFE:RESERVED" 65535 "Invalid" ;
VAL_ 773 MON_RrFloorDuctSnsr 0 "0x0~0x640:-40.0~160.0¡É" 1600 "0x0~0x640:-40.0~160.0¡É" 1601 "641~0xFFFE:RESERVED" 65534 "641~0xFFFE:RESERVED" 65535 "Invalid" ;
VAL_ 773 MON_RrVentDuctSnsr 0 "0x0~0x640:-40.0~160.0¡É" 1600 "0x0~0x640:-40.0~160.0¡É" 1601 "641~0xFFFE:RESERVED" 65534 "641~0xFFFE:RESERVED" 65535 "Invalid" ;
VAL_ 773 MON_PMSnsrSta 0 "Initializing" 1 "NormalOperation" 2 "LimitOperation" 3 "Standby (*)" 4 "Error" ;
VAL_ 774 MON_IGN1 0 "Off(Default)" 1 "On" 2 "RESERVED" 3 "Invalid" ;
VAL_ 774 MON_IGN2 0 "Off(Default)" 1 "On" 2 "RESERVED" 3 "Invalid" ;
VAL_ 774 MON_VBAT 0 "0x0~0x7530:0~30000(30.0V)" 30000 "0x0~0x7530:0~30000(30.0V)" 13501 "34BD~0xFFFE:RESERVED" 65534 "34BD~0xFFFE:RESERVED" 65535 "None" ;
VAL_ 774 MON_IGN3 0 "Off(Default)" 1 "On" 2 "RESERVED" 3 "Invalid" ;
VAL_ 774 MON_PTCRly1 0 "Off(Default)" 1 "On" ;
VAL_ 774 MON_PTCRlyVtg 0 "0x0~0x1388:0~5.000V" 5000 "0x0~0x1388:0~5.000V" 5001 "1389~0xFFFE:RESERVED" 65534 "1389~0xFFFE:RESERVED" 65535 "Invalid" ;
VAL_ 775 MON_RgnOpt 0 "DOM (*)" 1 "GEN" 2 "MID" 3 "EU" 4 "AUS" 5 "CAN" 6 "N/A" 7 "CHN" 8 "RUS" 9 "IND" 10 "BZL" 11 "MEX" ;
VAL_ 775 MON_DrvOnlyOpt 0 "Not Apply(Default)" 1 "Apply" ;
VAL_ 775 MON_ADSOpt 0 "Not Apply(Default)" 1 "Apply" ;
VAL_ 775 MON_AfterBlowOpt 0 "Not Apply(Default)" 1 "Apply" ;
VAL_ 775 MON_SchdldVentOpt 0 "Not Apply(Default)" 1 "Apply" ;
VAL_ 775 MON_FineDustOpt 0 "Not Apply(Default)" 1 "Apply" ;
VAL_ 775 MON_FrontSyncCtrlTypOpt 0 "Not Apply(Default)" 1 "Apply" ;
VAL_ 775 MON_CompOpt 0 "Internal_Comp" 1 "External_Comp_Clutch (*)" 2 "External_Comp_Clutchless" 3 "Fixed_Comp" 4 "Electric_Comp" ;
VAL_ 775 MON_WheelDrivePosOpt 0 "Front" 1 "Rear" 2 "4WD" ;
VAL_ 775 MON_NetworkTypOpt 0 "Master" 1 "3Gen" 2 "2Gen" ;
VAL_ 775 MON_AutoSwTyp 0 "Auto 1 button" 1 "Auto 2 button" ;
VAL_ 775 MON_ModSwTypOpt 0 "Mode1Btn" 1 "Mode2Btn" 2 "Mode3Btn" ;
VAL_ 775 MON_IntakeSwTypOpt 0 "Intake1Btn" 1 "Intake2Btn" ;
VAL_ 775 MON_OffSwTypOpt 0 "OffSw" 1 "OnOffSw" 2 "BlrDnOffSw" ;
VAL_ 775 MON_TempSwKnobOpt 0 "Non-temp knob type" 1 "temp knob type" ;
VAL_ 775 MON_BlrSwKnobOpt 0 "Non-blower knob type" 1 "Blower knob type" ;
VAL_ 775 MON_BATCoolingTypOpt 0 "Air_Cooling" 1 "Water_Cooling" ;
VAL_ 775 MON_PTCStepOpt 0 "Step1" 1 "Step2" ;
VAL_ 775 MON_PTCTypOpt 0 "High Voltage" 1 "Low Voltage" 2 "Not_Apply" ;
VAL_ 775 MON_ThermostatOpt 0 "Not Apply(Default)" 1 "Apply" ;
VAL_ 775 MON_SmartVentOpt 0 "Not Apply(Default)" 1 "Apply" ;
VAL_ 775 MON_ROATypOpt 0 "Not_Apply" 1 "UltrasonicType" ;
VAL_ 775 MON_VehTypOpt 0 "Gasoline (*)" 1 "Diesel" 2 "LPI" 3 "HEV" 4 "PHEV" 5 "EV" 6 "FCEV" ;
VAL_ 775 MON_VRLedOpt 0 "Not Apply(Default)" 1 "Apply" ;
VAL_ 775 MON_FrontAutoStepOpt 0 "Not Apply" 1 "Single Auto Step" 2 "Multi Auto Step(Default)" ;
VAL_ 775 MON_2ndAutoStepOpt 0 "Not Apply(Default)" 1 "Single Auto Step" 2 "Multi Auto Step" ;
VAL_ 775 MON_2ndAutoSwTyp 0 "Auto 1 button" 1 "Auto 2 button" ;
VAL_ 775 MON_2ndOffSwTypOpt 0 "OffSw" 1 "OnOffSw" 2 "BlrDnOffSw" ;
VAL_ 775 MON_2ndModSwTypOpt 0 "Mode1Btn" 1 "Mode2Btn" 2 "Mode3Btn" ;
VAL_ 775 MON_2ndAutoBtnOpt 0 "Single Button Type" 1 "Dual Button Type" 2 "Button OFF" ;
VAL_ 775 MON_2ndBlrBtnOpt 0 "Single Button Type" 1 "Dual Button Type" 2 "Button OFF" ;
VAL_ 775 MON_2ndModBtnOpt 0 "Single Button Type" 1 "Dual Button Type" 2 "Button OFF" ;
VAL_ 775 MON_2ndTmpBtnOpt 0 "Single Button Type" 1 "Dual Button Type" 2 "Button OFF" ;
VAL_ 775 MON_2ndTempSwKnobOpt 0 "Non-temp knob type" 1 "temp knob type" ;
VAL_ 775 MON_DrvHndSideOpt 0 "LHD" 1 "RHD" ;
VAL_ 775 MON_DisplayOpt 0 "Not_Apply" 1 "Mono_Segment" 2 "Color_Segment" 3 "TFT" ;
VAL_ 778 MON_Auto2LHBlrVtgVal 0 "0x0~0x34BC:0~13.500V" 13500 "0x0~0x34BC:0~13.500V" 13501 "34BD~0xFFFE:RESERVED" 65534 "34BD~0xFFFE:RESERVED" 65535 "None" ;
VAL_ 778 MON_Auto2LHModState 0 "Off" 1 "Floor" 2 "Vent" 3 "BL" 4 "Def_EU" 5 "Mix" 6 "Def_Vent" 7 "All" 8 "Vent_Bleed" 9 "Floor_100" 10 "Warm_Floor" 11 "Cool_Mix" 12 "Def" 13 "RESERVED" 14 "RESERVED" 15 "None" ;
VAL_ 778 MON_Auto2LHTempDrState 0 "0x0~0x3E8:0~100.0%" 1000 "0x0~0x3E8:0~100.0%" 1001 "RESERVED" 1002 "RESERVED" 1003 "RESERVED" 1004 "RESERVED" 1005 "RESERVED" 1006 "RESERVED" 1007 "RESERVED" 1008 "RESERVED" 1009 "RESERVED" 1010 "RESERVED" 1011 "RESERVED" 1012 "RESERVED" 1013 "RESERVED" 1014 "RESERVED" 1015 "RESERVED" 1016 "RESERVED" 1017 "RESERVED" 1018 "RESERVED" 1019 "RESERVED" 1020 "RESERVED" 1021 "RESERVED" 1022 "RESERVED" 1023 "None" ;
VAL_ 778 MON_AutoHeatloadStep 0 "Off" 1 "1Step" 2 "2Step" 3 "3Step" 4 "4Step" 5 "5Step" 6 "6Step" 7 "7Step" 8 "8Step" 9 "9Step" 10 "10Step" 11 "11Step" 12 "12Step" 13 "13Step" 14 "14Step" 15 "15Step" 16 "16Step" 17 "RESERVED" 18 "RESERVED" 19 "RESERVED" 20 "RESERVED" 21 "RESERVED" 22 "RESERVED" 23 "RESERVED" 24 "RESERVED" 25 "RESERVED" 26 "RESERVED" 27 "RESERVED" 28 "RESERVED" 29 "RESERVED" 30 "RESERVED" 31 "RESERVED" ;
VAL_ 778 MON_AutoHVPTCDuty 0 "0x0~0x64:0~100%" 100 "0x0~0x64:0~100%" 101 "65~0xFE:RESERVED" 254 "65~0xFE:RESERVED" 255 "Invalid" ;
VAL_ 778 MON_AutoECompRpm 0 "0x0~0xFFFE:0~65534RPM" 65534 "0x0~0xFFFE:0~65534RPM" 65535 "Invalid" ;
VAL_ 797 MON_AutoDrvTempDrVtgVal 0 "0x0~0x1388:0~5.000V" 5000 "0x0~0x1388:0~5.000V" 5001 "1389~0xFFFE:RESERVED" 65534 "1389~0xFFFE:RESERVED" 65535 "Invalid" ;
VAL_ 797 MON_AutoAstTempDrVtgVal 0 "0x0~0x1388:0~5.000V" 5000 "0x0~0x1388:0~5.000V" 5001 "1389~0xFFFE:RESERVED" 65534 "1389~0xFFFE:RESERVED" 65535 "Invalid" ;
VAL_ 797 MON_AutoDrv2TempDrVtgVal 0 "0x0~0x1388:0~5.000V" 5000 "0x0~0x1388:0~5.000V" 5001 "1389~0xFFFE:RESERVED" 65534 "1389~0xFFFE:RESERVED" 65535 "Invalid" ;
VAL_ 797 MON_ADSTempDrLmtState 0 "0x0~0x1388:0~5.000V" 5000 "0x0~0x1388:0~5.000V" 5001 "1389~0xFFFE:RESERVED" 65534 "1389~0xFFFE:RESERVED" 65535 "Invalid" ;
VAL_ 798 MON_ADSModState 0 "OFF" 1 "FLOOR" 2 "VENT" 3 "B_L (VENT_FLOOR)" 4 "DEF_EU" 5 "MIX (DEF_FLOOR)" 6 "DEF_VENT" 7 "ALL (DEF_VENT_FLOOR)" 8 "VENT_BLEED" 9 "FLOOR_100" 10 "WARM_FLOOR" 11 "COOL_MIX" 12 "DEF (MAX_DEF)" ;
VAL_ 798 MON_ADSACForcedOnReq 0 "OFF" 1 "ON" ;
VAL_ 798 MON_ADSACDispPreValHoldReq 0 "OFF" 1 "ON" ;
VAL_ 798 MON_ADSSymState 0 "OFF" 1 "ON" ;
VAL_ 798 MON_ADSInhibitPIReq 0 "OFF" 1 "ON" ;
VAL_ 798 MON_ADSOpState 0 "OFF" 1 "ON" ;
VAL_ 798 MON_ADSBlrVtgVal 0 "0x0~0x34BC:0~13.500V" 13500 "0x0~0x34BC:0~13.500V" 13501 "34BD~0xFFFE:RESERVED" 65534 "34BD~0xFFFE:RESERVED" 65535 "None" ;
VAL_ 798 MON_ADSIntakeState 0 "FRE(0.0%)" 1 "1~0x3E7:Intake(0.1~99.9%)" 999 "1~0x3E7:Intake(0.1~99.9%)" 1000 "REC(100.0%)" 1001 "RESERVED" 1002 "RESERVED" 1003 "RESERVED" 1004 "RESERVED" 1005 "RESERVED" 1006 "RESERVED" 1007 "RESERVED" 1008 "RESERVED" 1009 "RESERVED" 1010 "RESERVED" 1011 "RESERVED" 1012 "RESERVED" 1013 "RESERVED" 1014 "RESERVED" 1015 "RESERVED" 1016 "RESERVED" 1017 "RESERVED" 1018 "RESERVED" 1019 "RESERVED" 1020 "RESERVED" 1021 "RESERVED" 1022 "RESERVED" 1023 "None" ;
VAL_ 798 MON_ADSDEFDrState 0 "0x0~0x3E8:0~100.0%" 1000 "0x0~0x3E8:0~100.0%" 1001 "RESERVED" 1002 "RESERVED" 1003 "RESERVED" 1004 "RESERVED" 1005 "RESERVED" 1006 "RESERVED" 1007 "RESERVED" 1008 "RESERVED" 1009 "RESERVED" 1010 "RESERVED" 1011 "RESERVED" 1012 "RESERVED" 1013 "RESERVED" 1014 "RESERVED" 1015 "RESERVED" 1016 "RESERVED" 1017 "RESERVED" 1018 "RESERVED" 1019 "RESERVED" 1020 "RESERVED" 1021 "RESERVED" 1022 "RESERVED" 1023 "None" ;
VAL_ 798 MON_ADSModPrfleChgReq 0 "OFF" 1 "ON" ;
VAL_ 798 MON_ADSACState 0 "OFF" 1 "ON" ;
